VERSION ""

NS_ :

BS_:

BU_: TM

BO_ 1142 VCU_SF: 8 Vector__XXX
 SG_ PEPS_MTO_Failure_Status : 9|2@0+ (1,0) [0|3] ""  TM
 SG_ ABS_ESP_MRC_Failure_Status : 1|2@0+ (1,0) [0|3] ""  TM
 SG_ ABS_ESP_CRC_Failure_Status : 3|2@0+ (1,0) [0|3] ""  TM
 SG_ BattVolt_VCU : 23|8@0+ (0.1,0) [0|25] "Volts"  TM
 SG_ Telematics_MTO_Failure_status : 61|2@0+ (1,0) [0|3] ""  TM
 SG_ Telematics_Invalid_FailureStatus : 63|2@0+ (1,0) [0|3] ""  TM
 SG_ SRS_MTO_Failure_Status : 59|2@0+ (1,0) [0|3] ""  TM
 SG_ IPcMToFailureStatus : 49|2@0+ (1,0) [0|3] ""  TM
 SG_ IPcInvalidFailureStatus : 51|2@0+ (1,0) [0|3] ""  TM
 SG_ ABsMToFailureStatus : 7|2@0+ (1,0) [0|3] ""  TM
 SG_ ABsInvalidFailureStatus : 5|2@0+ (1,0) [0|3] ""  TM
 SG_ VCU_SW_Version : 31|16@0+ (1,0) [0|65535] ""  TM
 SG_ VCU_EP_Failure_Status : 13|2@0+ (1,0) [0|3] ""  TM
 SG_ VCU_BO_Failure_Status : 15|2@0+ (1,0) [0|3] ""  TM
 SG_ GSS_EV_Invalid_Failure_Status : 41|2@0+ (1,0) [0|3] ""  TM
 SG_ GSS_EV_MTO_Failure_Status : 43|2@0+ (1,0) [0|3] ""  TM
 SG_ CCM_MTO_Failure_Status : 45|2@0+ (1,0) [0|3] ""  TM
 SG_ CCM_Invalid_Failure_Status : 47|2@0+ (1,0) [0|3] ""  TM
 SG_ BCmMToFailureStatus : 11|2@0+ (1,0) [0|3] ""  TM

BO_ 1827 Telematics_DiagRequest: 8 Vector__XXX
 SG_ Telematics_DiagRequest : 7|64@0+ (1,0) [0|0] ""  TM

BO_ 1835 Telematics_DiagResponse_USDT: 8 TM
 SG_ Telematics_DiagResponse_USDT : 7|64@0+ (1,0) [0|0] "" Vector__XXX

BO_ 1579 Telematics_DiagResponse_UUDT: 8 TM
 SG_ Telematics_DiagResponse_UUDT : 7|64@0+ (1,0) [0|0] "" Vector__XXX

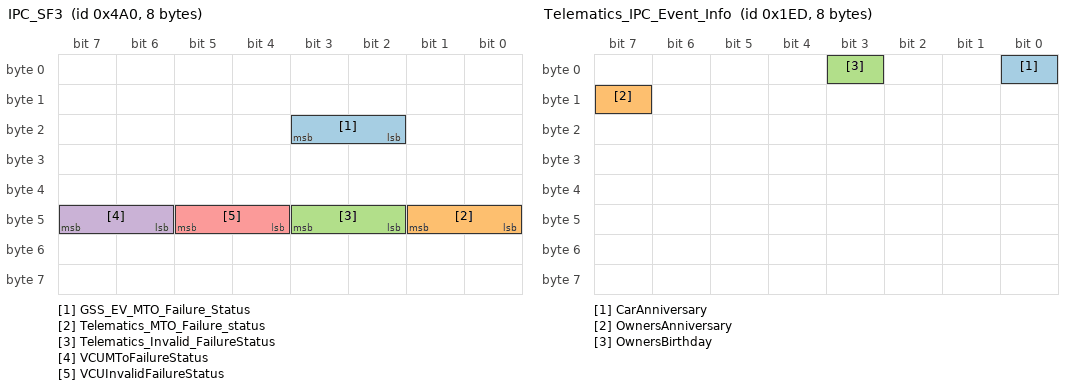
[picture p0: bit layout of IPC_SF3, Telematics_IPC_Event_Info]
BO_ 1184 IPC_SF3: 8 Vector__XXX
 SG_ GSS_EV_MTO_Failure_Status : 19|2@0+ (1,0) [0|3] ""  TM
 SG_ Telematics_MTO_Failure_status : 41|2@0+ (1,0) [0|3] ""  TM
 SG_ Telematics_Invalid_FailureStatus : 43|2@0+ (1,0) [0|3] ""  TM
 SG_ VCUMToFailureStatus : 47|2@0+ (1,0) [0|3] ""  TM
 SG_ VCUInvalidFailureStatus : 45|2@0+ (1,0) [0|3] ""  TM

BO_ 493 Telematics_IPC_Event_Info: 8 TM
 SG_ CarAnniversary : 0|1@0+ (1,0) [0|1] "" Vector__XXX
 SG_ OwnersAnniversary : 15|1@0+ (1,0) [0|1] "" Vector__XXX
 SG_ OwnersBirthday : 3|1@0+ (1,0) [0|1] "" Vector__XXX

BO_ 581 VCU8_RC: 8 Vector__XXX
 SG_ HvChargeTypeStatus : 37|2@0+ (1,0) [0|3] ""  TM
 SG_ HvChargeType : 35|2@0+ (1,0) [0|3] ""  TM
 SG_ HvChargingStateStatus : 33|2@0+ (1,0) [0|3] ""  TM
 SG_ HvChargingState : 26|3@0+ (1,0) [0|7] ""  TM
 SG_ TimetoChargeHVMintsStatus : 17|2@0+ (1,0) [0|3] ""  TM
 SG_ TimetoChargeHVMints : 23|6@0+ (1,0) [0|59] "Minutes"  TM
 SG_ TimetoChargeHVHoursStatus : 10|2@0+ (1,0) [0|3] ""  TM
 SG_ TimetoChargeHVHours : 15|5@0+ (1,0) [0|23] "Hours"  TM
 SG_ CoolingPwrFdbkVal : 63|7@0+ (1,0) [0|100] "%"  TM
 SG_ HeatingPwrFdbkVal : 55|7@0+ (1,0) [0|100] "%"  TM
 SG_ CabinCoolingSolValveStateStatus : 29|2@0+ (1,0) [0|3] ""  TM
 SG_ CabinCoolingSolValveState : 31|2@0+ (1,0) [0|3] ""  TM
 SG_ LowHVBatteryChargeStatus : 7|2@0+ (1,0) [0|3] ""  TM
 SG_ LowHVBatteryCharge : 5|2@0+ (1,0) [0|3] ""  TM
 SG_ LowLVBatteryChargeStatus : 3|2@0+ (1,0) [0|3] ""  TM
 SG_ LowLVBatteryCharge : 1|2@0+ (1,0) [0|3] ""  TM
 SG_ HvAmpHrStatus : 39|2@0+ (1,0) [0|3] ""  TM
 SG_ HvAmpHr : 47|8@0+ (0.5,0) [0|125] ""  TM

BO_ 1171 CCM_SF2: 8 Vector__XXX
 SG_ VCUMToFailureStatus : 33|2@0+ (1,0) [0|3] ""  TM
 SG_ VCUInvalidFailureStatus : 35|2@0+ (1,0) [0|3] ""  TM

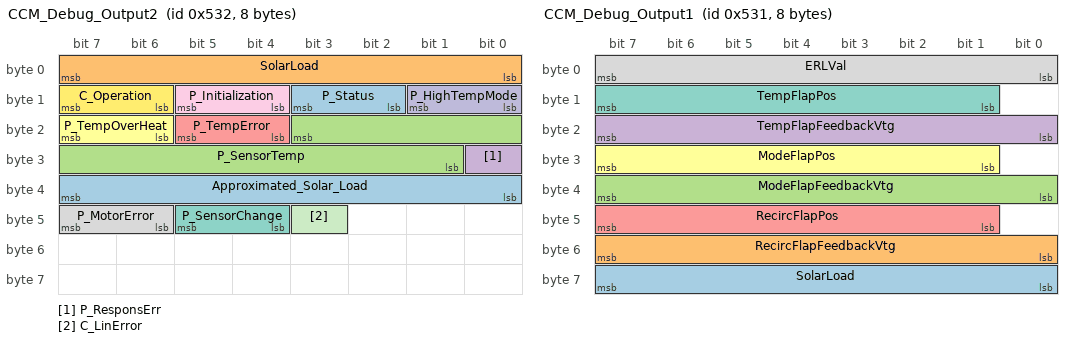
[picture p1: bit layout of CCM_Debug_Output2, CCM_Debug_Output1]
BO_ 1330 CCM_Debug_Output2: 8 Vector__XXX
 SG_ P_Status : 11|2@0+ (1,0) [0|3] ""  TM
 SG_ SolarLoad : 7|8@0+ (5,0) [0|1200] "W/M^2"  TM
 SG_ P_SensorTemp : 19|11@0+ (0.1,-40) [-40|164.7] ""  TM
 SG_ P_ResponsErr : 24|1@0+ (1,0) [0|1] ""  TM
 SG_ P_TempError : 21|2@0+ (1,0) [0|3] ""  TM
 SG_ P_TempOverHeat : 23|2@0+ (1,0) [0|3] ""  TM
 SG_ P_SensorChange : 45|2@0+ (1,0) [0|3] ""  TM
 SG_ P_MotorError : 47|2@0+ (1,0) [0|3] ""  TM
 SG_ P_Initialization : 13|2@0+ (1,0) [0|3] ""  TM
 SG_ P_HighTempMode : 9|2@0+ (1,0) [0|3] ""  TM
 SG_ C_LinError : 43|1@0+ (1,0) [0|1] ""  TM
 SG_ C_Operation : 15|2@0+ (1,0) [0|3] ""  TM
 SG_ Approximated_Solar_Load : 39|8@0+ (5,0) [0|1200] "W/M^2"  TM

BO_ 1329 CCM_Debug_Output1: 8 Vector__XXX
 SG_ SolarLoad : 63|8@0+ (5,0) [0|1200] "W/M^2"  TM
 SG_ RecircFlapFeedbackVtg : 55|8@0+ (0.1,0) [0|25.5] "Volts"  TM
 SG_ ModeFlapFeedbackVtg : 39|8@0+ (0.1,0) [0|25.5] "Volts"  TM
 SG_ TempFlapFeedbackVtg : 23|8@0+ (0.1,0) [0|25.5] "Volts"  TM
 SG_ RecircFlapPos : 47|7@0+ (1,0) [0|100] "%"  TM
 SG_ ModeFlapPos : 31|7@0+ (1,0) [0|100] "%"  TM
 SG_ TempFlapPos : 15|7@0+ (1,0) [0|100] "%"  TM
 SG_ ERLVal : 7|8@0+ (1,0) [0|255] ""  TM

BO_ 1288 TM_NMPDU: 8 TM
 SG_ PartialNetworkInformation_TM : 14|1@0+ (1,0) [0|1] "" Vector__XXX
 SG_ Reserved55 : 23|1@0+ (1,0) [0|1] "" Vector__XXX
 SG_ Reserved54 : 22|1@0+ (1,0) [0|1] "" Vector__XXX
 SG_ Reserved53 : 21|1@0+ (1,0) [0|1] "" Vector__XXX
 SG_ Reserved52 : 20|1@0+ (1,0) [0|1] "" Vector__XXX
 SG_ Reserved51 : 15|1@0+ (1,0) [0|1] "" Vector__XXX
 SG_ Reserved50 : 13|1@0+ (1,0) [0|1] "" Vector__XXX
 SG_ Reserved49 : 10|1@0+ (1,0) [0|1] "" Vector__XXX
 SG_ Reserved48 : 9|1@0+ (1,0) [0|1] "" Vector__XXX
 SG_ RepeatMessageReq_TM : 8|1@0+ (1,0) [0|1] "" Vector__XXX
 SG_ PreviousState_TM : 19|3@0+ (1,0) [0|7] "" Vector__XXX
 SG_ NMCoOrdSlpReady_TM : 11|1@0+ (1,0) [0|1] "" Vector__XXX
 SG_ CurrentState_TM : 16|1@0+ (1,0) [0|1] "" Vector__XXX
 SG_ TM_NMPDU_USER_DATA_D5 : 63|8@0+ (1,0) [0|255] "" Vector__XXX
 SG_ TM_NMPDU_USER_DATA_D4 : 55|8@0+ (1,0) [0|255] "" Vector__XXX
 SG_ TM_NMPDU_USER_DATA_D3 : 47|8@0+ (1,0) [0|255] "" Vector__XXX
 SG_ TM_NMPDU_USER_DATA_D2 : 39|8@0+ (1,0) [0|255] "" Vector__XXX
 SG_ TM_NMPDU_USER_DATA_D1 : 31|8@0+ (1,0) [0|255] "" Vector__XXX
 SG_ TM_NMPDU_SRC_ECU_ID : 7|8@0+ (1,0) [0|255] "" Vector__XXX
 SG_ ActiveWakeUp_TM : 12|1@0+ (1,0) [0|1] "" Vector__XXX

BO_ 1287 VCU_NMPDU: 8 Vector__XXX
 SG_ PartialNetworkInformation_VCU : 14|1@0+ (1,0) [0|1] ""  TM
 SG_ VCU_NMPDU_USER_DATA_D3 : 47|8@0+ (1,0) [0|255] ""  TM
 SG_ Reserved47 : 23|1@0+ (1,0) [0|1] ""  TM
 SG_ Reserved46 : 22|1@0+ (1,0) [0|1] ""  TM
 SG_ Reserved45 : 21|1@0+ (1,0) [0|1] ""  TM
 SG_ Reserved44 : 20|1@0+ (1,0) [0|1] ""  TM
 SG_ Reserved43 : 15|1@0+ (1,0) [0|1] ""  TM
 SG_ Reserved42 : 13|1@0+ (1,0) [0|1] ""  TM
 SG_ Reserved41 : 10|1@0+ (1,0) [0|1] ""  TM
 SG_ Reserved40 : 9|1@0+ (1,0) [0|1] ""  TM
 SG_ RepeatMessageReq_VCU : 8|1@0+ (1,0) [0|1] ""  TM
 SG_ PreviousState_VCU : 19|3@0+ (1,0) [0|7] ""  TM
 SG_ NMCoOrdSlpReady_VCU : 11|1@0+ (1,0) [0|1] ""  TM
 SG_ CurrentState_VCU : 16|1@0+ (1,0) [0|1] ""  TM
 SG_ VCU_NMPDU_USER_DATA_D5 : 63|8@0+ (1,0) [0|255] ""  TM
 SG_ VCU_NMPDU_USER_DATA_D4 : 55|8@0+ (1,0) [0|255] ""  TM
 SG_ VCU_NMPDU_USER_DATA_D2 : 39|8@0+ (1,0) [0|255] ""  TM
 SG_ VCU_NMPDU_USER_DATA_D1 : 31|8@0+ (1,0) [0|255] ""  TM
 SG_ VCU_NMPDU_SRC_ECU_ID : 7|8@0+ (1,0) [0|255] ""  TM
 SG_ ActiveWakeUp_VCU : 12|1@0+ (1,0) [0|1] ""  TM

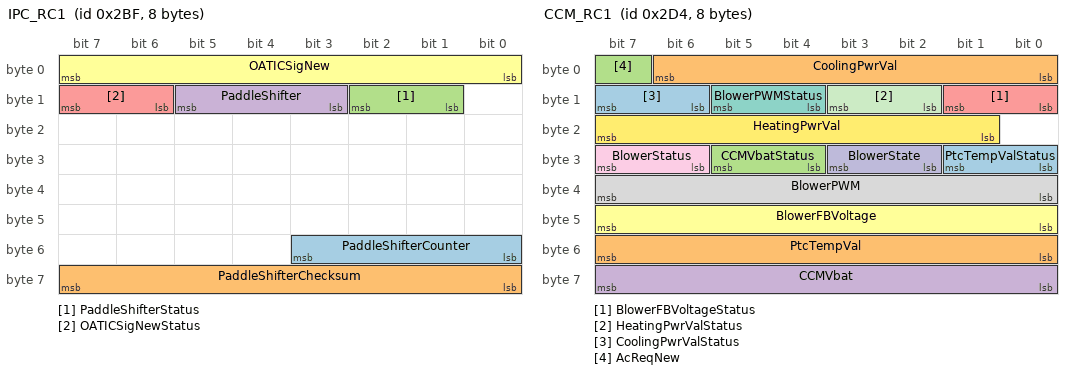
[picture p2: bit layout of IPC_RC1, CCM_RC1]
BO_ 703 IPC_RC1: 8 Vector__XXX
 SG_ PaddleShifterCounter : 51|4@0+ (1,0) [0|15] ""  TM
 SG_ PaddleShifterChecksum : 63|8@0+ (1,0) [0|255] ""  TM
 SG_ PaddleShifterStatus : 10|2@0+ (1,0) [0|3] ""  TM
 SG_ PaddleShifter : 13|3@0+ (1,0) [0|7] ""  TM
 SG_ OATICSigNewStatus : 15|2@0+ (1,0) [0|3] ""  TM
 SG_ OATICSigNew : 7|8@0+ (0.5,-40) [-40|85] "degC"  TM

BO_ 724 CCM_RC1: 8 Vector__XXX
 SG_ PtcTempValStatus : 25|2@0+ (1,0) [0|3] ""  TM
 SG_ PtcTempVal : 55|8@0+ (1,-40) [-40|215] "°C"  TM
 SG_ CCMVbatStatus : 29|2@0+ (1,0) [0|3] ""  TM
 SG_ CCMVbat : 63|8@0+ (0.1,0) [0|25.5] "Volts"  TM
 SG_ BlowerFBVoltageStatus : 9|2@0+ (1,0) [0|3] ""  TM
 SG_ BlowerFBVoltage : 47|8@0+ (0.1,0) [0|25.5] "Volts"  TM
 SG_ BlowerPWMStatus : 13|2@0+ (1,0) [0|3] ""  TM
 SG_ BlowerPWM : 39|8@0+ (1,0) [0|100] "%"  TM
 SG_ BlowerStatus : 31|2@0+ (1,0) [0|3] ""  TM
 SG_ BlowerState : 27|2@0+ (1,0) [0|3] ""  TM
 SG_ HeatingPwrValStatus : 11|2@0+ (1,0) [0|3] ""  TM
 SG_ HeatingPwrVal : 23|7@0+ (1,0) [0|100] "%"  TM
 SG_ CoolingPwrValStatus : 15|2@0+ (1,0) [0|3] ""  TM
 SG_ CoolingPwrVal : 6|7@0+ (1,0) [0|100] "%"  TM
 SG_ AcReqNew : 7|1@0+ (1,0) [0|1] ""  TM

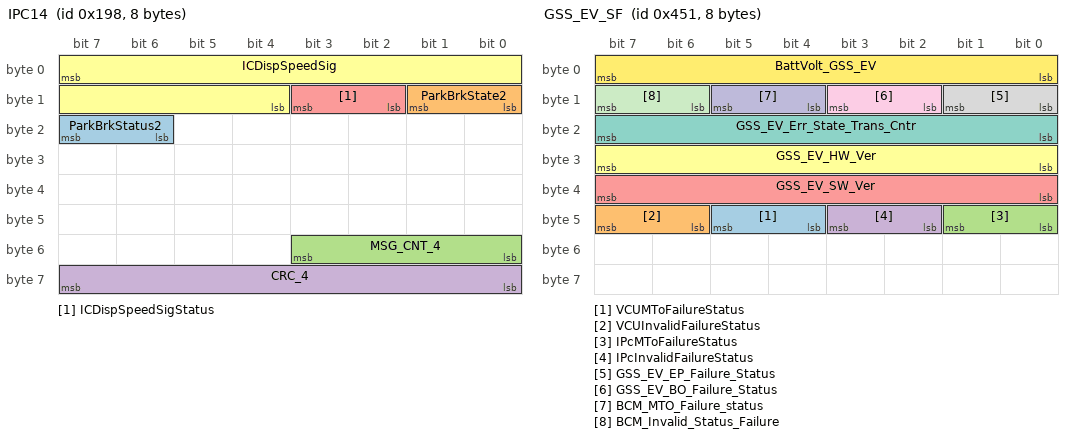
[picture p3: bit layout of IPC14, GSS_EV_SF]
BO_ 408 IPC14: 8 Vector__XXX
 SG_ ParkBrkStatus2 : 23|2@0+ (1,0) [0|3] ""  TM
 SG_ ParkBrkState2 : 9|2@0+ (1,0) [0|3] ""  TM
 SG_ MSG_CNT_4 : 51|4@0+ (1,0) [0|15] ""  TM
 SG_ CRC_4 : 63|8@0+ (1,0) [0|255] ""  TM
 SG_ ICDispSpeedSigStatus : 11|2@0+ (1,0) [0|3] ""  TM
 SG_ ICDispSpeedSig : 7|12@0+ (0.03125,0) [0|127.96875] "m/s"  TM

BO_ 738 BCM_RC5: 8 Vector__XXX
 SG_ BcmHbaFaultState : 49|1@0+ (1,0) [0|1] ""  TM
 SG_ HighBeamState : 23|1@0+ (1,0) [0|1] ""  TM
 SG_ RearWiperStateStatus : 22|2@0+ (1,0) [0|3] ""  TM
 SG_ RearWiperState : 20|2@0+ (1,0) [0|3] ""  TM
 SG_ RemoteUsecaseStateStatus : 51|2@0+ (1,0) [0|3] ""  TM
 SG_ RemoteUsecaseState : 53|2@0+ (1,0) [0|3] ""  TM
 SG_ DewPointTemperature : 47|10@0+ (0.1,-39.5) [-39.5|60.4] ""  TM
 SG_ WindshieldTemperature : 39|8@0+ (0.5,-39.5) [-39.5|87] ""  TM
 SG_ HumidityValue : 31|8@0+ (0.5,0) [0|100] "%"  TM
 SG_ HornStateStatus : 14|2@0+ (1,0) [0|3] ""  TM
 SG_ HornState : 15|1@0+ (1,0) [0|1] ""  TM
 SG_ ForcePanicStatus : 12|1@0+ (1,0) [0|1] ""  TM
 SG_ ApprochLampStateStatus : 18|2@0+ (1,0) [0|3] ""  TM
 SG_ ApprochLampState : 16|1@0+ (1,0) [0|1] ""  TM
 SG_ LowBeamTellTaleStatus : 11|2@0+ (1,0) [0|3] ""  TM
 SG_ LowBeamTellTale : 7|1@0+ (1,0) [0|1] ""  TM
 SG_ IntrusionInfoStateStatus : 9|2@0+ (1,0) [0|3] ""  TM
 SG_ IntrusionInfoState : 6|1@0+ (1,0) [0|1] ""  TM
 SG_ HazardLampState : 3|1@0+ (1,0) [0|1] ""  TM
 SG_ HazardLampStateStatus : 5|2@0+ (1,0) [0|3] ""  TM
 SG_ VehicleSecured : 0|1@0+ (1,0) [0|1] ""  TM
 SG_ VehicleSecuredStatus : 2|2@0+ (1,0) [0|3] ""  TM

BO_ 495 TelematicsEventMsg_RC4: 8 TM
 SG_ SharedLocationReqAck : 14|3@0+ (1,0) [0|7] "" Vector__XXX
 SG_ CommunityHelpResp : 18|3@0+ (1,0) [0|7] "" Vector__XXX
 SG_ CommunityHelpNotif : 55|4@0+ (1,0) [0|15] "" Vector__XXX
 SG_ RemoteHornCmdStatus : 44|2@0+ (1,0) [0|3] "" Vector__XXX
 SG_ RemoteHornCmd : 45|1@0+ (1,0) [0|1] "" Vector__XXX
 SG_ RemoteApprochLmpCmdStatus : 41|2@0+ (1,0) [0|3] "" Vector__XXX
 SG_ RemoteApprochLmpCmd : 42|1@0+ (1,0) [0|1] "" Vector__XXX
 SG_ RemoteValetCmdStatus : 47|2@0+ (1,0) [0|3] "" Vector__XXX
 SG_ RemoteValetCmd : 33|1@0+ (1,0) [0|1] "" Vector__XXX
 SG_ RemoteAcTempSetStatus : 30|2@0+ (1,0) [0|3] "" Vector__XXX
 SG_ RemoteAcTempSet : 28|5@0+ (0.5,0) [0|31] "" Vector__XXX
 SG_ RemoteAcCmd : 31|1@0+ (1,0) [0|1] "" Vector__XXX
 SG_ RemoteAcCmdStatus : 39|2@0+ (1,0) [0|3] "" Vector__XXX
 SG_ RemoteImmoReqStatus : 37|2@0+ (1,0) [0|3] "" Vector__XXX
 SG_ RemoteImmoReq : 35|2@0+ (1,0) [0|3] "" Vector__XXX
 SG_ TowInfoStatus : 20|2@0+ (1,0) [0|3] "" Vector__XXX
 SG_ TowInfo : 21|1@0+ (1,0) [0|1] "" Vector__XXX
 SG_ ParkingCollisionInfoStatus : 23|2@0+ (1,0) [0|3] "" Vector__XXX
 SG_ ParkingCollisionInfo : 8|1@0+ (1,0) [0|1] "" Vector__XXX
 SG_ RemotePositionCmdStatus : 7|2@0+ (1,0) [0|3] "" Vector__XXX
 SG_ RemotePositionCmd : 15|1@0+ (1,0) [0|1] "" Vector__XXX
 SG_ RemoteHazardCmdStatus : 11|2@0+ (1,0) [0|3] "" Vector__XXX
 SG_ RemoteHazardCmd : 9|1@0+ (1,0) [0|1] "" Vector__XXX
 SG_ RemoteVehicleUnlockCmdStatus : 5|2@0+ (1,0) [0|3] "" Vector__XXX
 SG_ RemoteVehicleUnlockCmd : 3|1@0+ (1,0) [0|1] "" Vector__XXX
 SG_ RemoteVehicleLockCmdStatus : 2|2@0+ (1,0) [0|3] "" Vector__XXX
 SG_ RemoteVehicleLockCmd : 0|1@0+ (1,0) [0|1] "" Vector__XXX

BO_ 1105 GSS_EV_SF: 8 Vector__XXX
 SG_ VCUMToFailureStatus : 45|2@0+ (1,0) [0|3] ""  TM
 SG_ VCUInvalidFailureStatus : 47|2@0+ (1,0) [0|3] ""  TM
 SG_ IPcMToFailureStatus : 41|2@0+ (1,0) [0|3] ""  TM
 SG_ IPcInvalidFailureStatus : 43|2@0+ (1,0) [0|3] ""  TM
 SG_ GSS_EV_SW_Ver : 39|8@0+ (1,0) [0|255] ""  TM
 SG_ GSS_EV_HW_Ver : 31|8@0+ (1,0) [0|99] ""  TM
 SG_ GSS_EV_Err_State_Trans_Cntr : 23|8@0+ (1,0) [0|255] ""  TM
 SG_ GSS_EV_EP_Failure_Status : 9|2@0+ (1,0) [0|3] ""  TM
 SG_ GSS_EV_BO_Failure_Status : 11|2@0+ (1,0) [0|3] ""  TM
 SG_ BCM_MTO_Failure_status : 13|2@0+ (1,0) [0|3] ""  TM
 SG_ BCM_Invalid_Status_Failure : 15|2@0+ (1,0) [0|3] ""  TM
 SG_ BattVolt_GSS_EV : 7|8@0+ (0.1,0) [0|25] "V"  TM

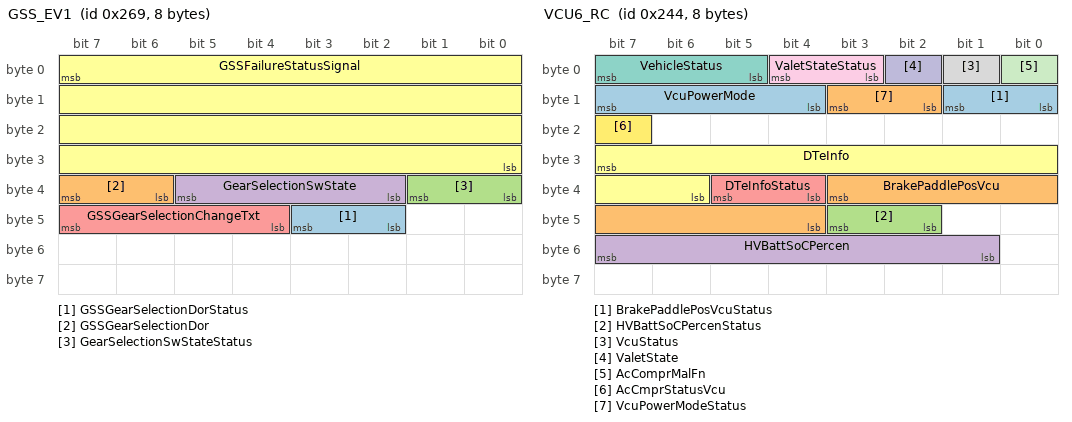
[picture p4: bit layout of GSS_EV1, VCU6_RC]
BO_ 617 GSS_EV1: 8 Vector__XXX
 SG_ GSSGearSelectionDorStatus : 43|2@0+ (1,0) [0|3] ""  TM
 SG_ GSSGearSelectionDor : 39|2@0+ (1,0) [0|3] ""  TM
 SG_ GearSelectionSwStateStatus : 33|2@0+ (1,0) [0|3] ""  TM
 SG_ GearSelectionSwState : 37|4@0+ (1,0) [0|15] ""  TM
 SG_ GSSGearSelectionChangeTxt : 47|4@0+ (1,0) [0|15] ""  TM
 SG_ GSSFailureStatusSignal : 7|32@0+ (1,0) [0|4294967295] ""  TM

BO_ 580 VCU6_RC: 8 Vector__XXX
 SG_ BrakePaddlePosVcuStatus : 9|2@0+ (1,0) [0|3] ""  TM
 SG_ BrakePaddlePosVcu : 35|8@0+ (0.5,0) [0|100] "%"  TM
 SG_ HVBattSoCPercenStatus : 43|2@0+ (1,0) [0|3] ""  TM
 SG_ HVBattSoCPercen : 55|7@0+ (1,0) [0|100] "%"  TM
 SG_ DTeInfoStatus : 37|2@0+ (1,0) [0|3] ""  TM
 SG_ DTeInfo : 31|10@0+ (1,0) [0|999] ""  TM
 SG_ VehicleStatus : 7|3@0+ (1,0) [0|7] ""  TM
 SG_ VcuStatus : 1|1@0+ (1,0) [0|1] ""  TM
 SG_ ValetStateStatus : 4|2@0+ (1,0) [0|3] ""  TM
 SG_ ValetState : 2|1@0+ (1,0) [0|1] ""  TM
 SG_ AcComprMalFn : 0|1@0+ (1,0) [0|1] ""  TM
 SG_ AcCmprStatusVcu : 23|1@0+ (1,0) [0|1] ""  TM
 SG_ VcuPowerMode : 15|4@0+ (1,0) [0|15] ""  TM
 SG_ VcuPowerModeStatus : 11|2@0+ (1,0) [0|3] ""  TM

CM_ BO_ 1142 "Supervision frame transmitted by VCU.";
CM_ SG_ 1142 PEPS_MTO_Failure_Status "Status of the PEPS  Message timeout  failure detected as per Tata-IVN_Specification_Network_Management.";
CM_ SG_ 1142 ABS_ESP_MRC_Failure_Status "Status of the message rolling counter failure detected by IC ECU as per communication layer spec";
CM_ SG_ 1142 ABS_ESP_CRC_Failure_Status "Status of the cyclic reduntancy failure detected by IC ECU as per communication layer spec.";
CM_ SG_ 1142 BattVolt_VCU "Battery voltage evaluated by VCU";
CM_ SG_ 1142 Telematics_MTO_Failure_status "Status of the Telematics Message timeout failure detected as per Tata-IVN_Specification_Network_Management.";
CM_ SG_ 1142 Telematics_Invalid_FailureStatus "Status of the Telematics Invalid failure detected as per Tata-IVN_Specification_Network_Management.";
CM_ SG_ 1142 SRS_MTO_Failure_Status "Status of the SRS  Message timeout  failure detected as per Tata-IVN_Specification_Network_Management.";
CM_ SG_ 1142 IPcMToFailureStatus "Status of the IPC Message Timeout  failure detected as per Tata-IVN_Specification_Network_Management.";
CM_ SG_ 1142 IPcInvalidFailureStatus "Status of the IC Invalid  signal  failure detected as per Tata-IVN_Specification_Network_Management.";
CM_ SG_ 1142 ABsMToFailureStatus "Status of the ESP  Message timeout failure detected as per Tata-IVN_Specification_Network_Management.";
CM_ SG_ 1142 ABsInvalidFailureStatus "Status of the ESP signal implausible  failure detected  by EPAS  as per  communication layer spec";
CM_ SG_ 1142 VCU_SW_Version "software Version of VCU ECU";
CM_ SG_ 1142 VCU_EP_Failure_Status "Status of the error-passive failure detected by VCU ECU as per Tata-IVN_Specification_Network_Management.";
CM_ SG_ 1142 VCU_BO_Failure_Status "Status of the bus off failure detected by VCU  ECU as per Tata-IVN_Specification_Network_Management.";
CM_ SG_ 1142 GSS_EV_Invalid_Failure_Status "Invalid failure status of GSS";
CM_ SG_ 1142 GSS_EV_MTO_Failure_Status "Status of the GSS messege timeout";
CM_ SG_ 1142 CCM_MTO_Failure_Status "Status of the FATC Message timeout failure detected as per Tata-IVN_Specification_Network_Management.";
CM_ SG_ 1142 CCM_Invalid_Failure_Status "Status of the  FATC Invalid  signal  failure detected as per Tata-IVN_Specification_Network_Management.";
CM_ SG_ 1142 BCmMToFailureStatus "Status of the BCM Message timeout  failure detected as per Tata-IVN_Specification_Network_Management.";
CM_ BO_ 1835 "Telematics Diagnostic Response USDT";
CM_ BO_ 1579 "Telematics Diagnostic Response UUDT";
CM_ BO_ 1184 "Supervision frame transmitted by IPC_EV";
CM_ SG_ 1184 GSS_EV_MTO_Failure_Status "Status of the GSS messege timeout";
CM_ SG_ 1184 Telematics_MTO_Failure_status "Status of the Telematics Message timeout failure detected as per Tata-IVN_Specification_Network_Management.";
CM_ SG_ 1184 Telematics_Invalid_FailureStatus "Status of the Telematics Invalid failure detected as per Tata-IVN_Specification_Network_Management.";
CM_ SG_ 1184 VCUMToFailureStatus "VCUMTO failure status";
CM_ SG_ 1184 VCUInvalidFailureStatus "VCU invalid failure status";
CM_ SG_ 493 CarAnniversary "Car Anniversary";
CM_ SG_ 493 OwnersAnniversary "Owenrs Marriage Anniversary";
CM_ SG_ 493 OwnersBirthday "It’s the car Owners Birthday";
CM_ SG_ 581 HvChargeTypeStatus "HV Battery Charging Type Status";
CM_ SG_ 581 HvChargeType "HV Battery Charging Type";
CM_ SG_ 581 HvChargingStateStatus "HV Battery Charging Status";
CM_ SG_ 581 HvChargingState "HV Battery Charging State";
CM_ SG_ 581 TimetoChargeHVMintsStatus "Time to charge HV Battery Minutes Status";
CM_ SG_ 581 TimetoChargeHVMints "Time to charge HV Battery Minutes";
CM_ SG_ 581 TimetoChargeHVHoursStatus "Time to charge HV Battery Hours Status";
CM_ SG_ 581 TimetoChargeHVHours "Time to charge HV Battery Hours";
CM_ SG_ 581 CoolingPwrFdbkVal "This signal is used to indicate the actual value of Cooling Power honored by VCU.";
CM_ SG_ 581 HeatingPwrFdbkVal "This signal is used to indicate the actual value of Heating Power honored by VCU.
";
CM_ SG_ 581 CabinCoolingSolValveStateStatus "Cabin Cooling Solenoid Valve Signal Status";
CM_ SG_ 581 CabinCoolingSolValveState "Cabin Cooling Solenoid Valve Signal";
CM_ SG_ 581 LowHVBatteryChargeStatus "Low HV Battery Charge Status";
CM_ SG_ 581 LowHVBatteryCharge "Low HV Battery Charge";
CM_ SG_ 581 LowLVBatteryChargeStatus "Low LV Battery Charge Status";
CM_ SG_ 581 LowLVBatteryCharge "Low LV Battery Charge";
CM_ SG_ 581 HvAmpHrStatus "HV Battery Charge Status";
CM_ SG_ 581 HvAmpHr "HV Battery Charge";
CM_ BO_ 1171 "Supervision frame transmitted by FATC";
CM_ SG_ 1171 VCUMToFailureStatus "VCUMTO failure status";
CM_ SG_ 1171 VCUInvalidFailureStatus "VCU invalid failure status";
CM_ SG_ 1330 P_Status "Transmit dust Sensor status signal";
CM_ SG_ 1330 SolarLoad "This signal is used to provide the current value of  Solar Load";
CM_ SG_ 1330 P_SensorTemp "Internal Sensor Temperature";
CM_ SG_ 1330 P_ResponsErr "Sensor standard LIN Response error status";
CM_ SG_ 1330 P_TempError "Transmit Sensor Temp error signal";
CM_ SG_ 1330 P_TempOverHeat "Transmit Sensor over-temp signal ";
CM_ SG_ 1330 P_SensorChange "Transmit Sensor Replace signal ";
CM_ SG_ 1330 P_MotorError "Transmit Fan Motor error signal ";
CM_ SG_ 1330 P_Initialization "Transmit initialization signal of Dust Sensor ";
CM_ SG_ 1330 P_HighTempMode "Transmit High temp operating mode signal ";
CM_ SG_ 1330 C_LinError "Sensor Communication error status";
CM_ SG_ 1330 C_Operation "Sensor operation permission signal by FATC.";
CM_ SG_ 1330 Approximated_Solar_Load "This signal is used to provide the current value of  Solar Load";
CM_ SG_ 1329 SolarLoad "This signal is used to provide the current value of  Solar Load";
CM_ SG_ 1329 RecircFlapFeedbackVtg "This signal is used to provide the feedback voltage value of  Air Inlet Flap Potentiometer";
CM_ SG_ 1329 ModeFlapFeedbackVtg "This signal is used to provide the feedback voltage value of  Air Distribution Flap Potentiometer";
CM_ SG_ 1329 TempFlapFeedbackVtg "This signal is used to provide the feedback voltage value of  Temperature Flap Potentiometer";
CM_ SG_ 1329 RecircFlapPos "This signal is used to provide the target value of  Air Inlet Flap";
CM_ SG_ 1329 ModeFlapPos "This signal is used to provide the target value of  Air Distribution Flap";
CM_ SG_ 1329 TempFlapPos "This signal is used to provide the target value of  Temperature Flap";
CM_ SG_ 1329 ERLVal "This signal is used to checked the Energy required for Cabin cooling / heating";
CM_ SG_ 703 PaddleShifterCounter "Rolling counter for the entire GSM Tx messages";
CM_ SG_ 703 PaddleShifterChecksum "CRC for entire GSM Tx messages";
CM_ SG_ 703 PaddleShifterStatus "This signal gives status of Paddle Shifter signal.";
CM_ SG_ 703 PaddleShifter "PaddleShifter signal";
CM_ SG_ 703 OATICSigNewStatus "Signal represents Status of OATSig";
CM_ SG_ 703 OATICSigNew "Signal represents Outside Ambient Temperature raw value evaluated by Instrument Cluster 
";
CM_ SG_ 724 PtcTempValStatus "PTC temperature signal status information";
CM_ SG_ 724 PtcTempVal "This signal is used to provide the current value of PTC temperature sensor";
CM_ SG_ 724 CCMVbatStatus "FATC battery Voltage Status";
CM_ SG_ 724 CCMVbat "Battery voltage measured by FATC";
CM_ SG_ 724 BlowerFBVoltageStatus "Blower feedback Voltage Status";
CM_ SG_ 724 BlowerFBVoltage "Blower Feedback voltage measured by FATC";
CM_ SG_ 724 BlowerPWMStatus "Blower PWM status";
CM_ SG_ 724 BlowerPWM "PWM% Given out by FATC for blower";
CM_ SG_ 724 BlowerStatus "Fault Occured:
It means one of the following faults has occured:
Blower Drive Line Short to Ground.
Blower Drive Line Short to Battery.
Blower Drive Line Open
Blower feedback Line Short to Battery.
Blower feedback Line Short to Ground or Open.";
CM_ SG_ 724 BlowerState "General Blower state
Not initialised:
it means blower is not yet initialised and all signal values of CCMblower message are not valid.
Off : it indicates that blower is Off.
On : it indicates that blower is On.";
CM_ SG_ 724 HeatingPwrValStatus "Indicate the status of heating power required for cabin heating ";
CM_ SG_ 724 HeatingPwrVal "This signal is used to control the PTC Heater for cabin heating";
CM_ SG_ 724 CoolingPwrValStatus "Indicate the status of cooling power required for cabin Cooling ";
CM_ SG_ 724 CoolingPwrVal "This signal is used to control the Compressor rpm for cabin Cooling";
CM_ SG_ 724 AcReqNew "VCU to recive the signal from FATC to know the AC request by driver";
CM_ SG_ 408 ParkBrkStatus2 "Signal represents Park brake status with 2 switch combination for RESS
";
CM_ SG_ 408 ParkBrkState2 "Signal represents Park brake states with 2 switch combination for RESS
";
CM_ SG_ 408 MSG_CNT_4 "rolling counter for message 0x198";
CM_ SG_ 408 CRC_4 "Signal represents CRC of the message.";
CM_ SG_ 408 ICDispSpeedSigStatus "Signal represents Status of Display Vehicle Speed Signal";
CM_ SG_ 408 ICDispSpeedSig "Signal represents Display Vehicle Speed evaluated by Instrument Cluster
";
CM_ SG_ 738 BcmHbaFaultState "It indicates any failure state in BCM for HBA control";
CM_ SG_ 738 HighBeamState "It indicates the status of input of High Beam switch";
CM_ SG_ 738 RearWiperStateStatus "Status of Rear Wiper function Activate/Deactivate to various ECUs";
CM_ SG_ 738 RearWiperState "Rear Wiper function Activate/Deactivate to various ECUs";
CM_ SG_ 738 RemoteUsecaseStateStatus "This signal gives status of RemoteUsecaseState signal.";
CM_ SG_ 738 RemoteUsecaseState "This signal is transmitted from BCM to TCM, PEPS, EMS, IPC & HU for informing ECUs about start working as normal Drive mode and ignore Remote Command recondition checks.";
CM_ SG_ 738 DewPointTemperature "The area of the Dew point Temperature where the RLS sensor is placed. (in Degree Celcius)";
CM_ SG_ 738 WindshieldTemperature "The area of the Windshield Temperature where the RLS sensor is placed. (in Degree Celcius)";
CM_ SG_ 738 HumidityValue "The area of the relative Humidity where the RLS sensor is placed (in terms of percentage)";
CM_ SG_ 738 HornStateStatus "HornStateStatus Signal information";
CM_ SG_ 738 HornState "Horn Status Information ";
CM_ SG_ 738 ForcePanicStatus "Force Panic Request signal";
CM_ SG_ 738 ApprochLampStateStatus "Status signal for ApprochLamp status from BCM";
CM_ SG_ 738 ApprochLampState "ApprochLampstatus from BCM";
CM_ SG_ 738 LowBeamTellTaleStatus "Status of the Low Beam Telltale";
CM_ SG_ 738 LowBeamTellTale "IC to display the low beam tell-tale when the low beam lamp is active";
CM_ SG_ 738 IntrusionInfoStateStatus "Status of Perimetric alarm state from BCM";
CM_ SG_ 738 IntrusionInfoState "Perimetric alarm state from BCM";
CM_ SG_ 738 HazardLampState "Hazard lamp status from BCM";
CM_ SG_ 738 HazardLampStateStatus "Status of signal HazardLampState";
CM_ SG_ 738 VehicleSecured "Vehicle secured information";
CM_ SG_ 738 VehicleSecuredStatus "Status of Vehicle secured information";
CM_ SG_ 495 CommunityHelpResp "TCM feedback to HU for community help command response";
CM_ SG_ 495 CommunityHelpNotif "Signal from Community Help receviers's TCM to receiver's HU to inform  the Community help request to Receiver.";
CM_ SG_ 495 RemoteHornCmdStatus "Status of the HornStateCmd signal published by TCU";
CM_ SG_ 495 RemoteHornCmd "Horn State on/off request from TCU";
CM_ SG_ 495 RemoteApprochLmpCmdStatus "Status of the RemoteApprochCmd signal published by TCU";
CM_ SG_ 495 RemoteApprochLmpCmd "Approch lamp on/off request from TCU";
CM_ SG_ 495 RemoteValetCmdStatus "Status of the Valetcmd Status published by TCU";
CM_ SG_ 495 RemoteValetCmd "Command published by TCU to request FATC";
CM_ SG_ 495 RemoteAcTempSetStatus "Status of the TCuAcTemperatureSet singnal as published by TCU.";
CM_ SG_ 495 RemoteAcTempSet "Set temperature value from TCU to FATC for in-cabin climate control.";
CM_ SG_ 495 RemoteAcCmd "Command published by TCU to request FATC to turn On/Off the AC.";
CM_ SG_ 495 RemoteAcCmdStatus "Status of the TCuAcCmd signal published by TCU";
CM_ SG_ 495 RemoteImmoReqStatus "Status signal for Immobilize request from TCU to VCU";
CM_ SG_ 495 RemoteImmoReq "Immobilize request from TCU to VCU";
CM_ SG_ 495 TowInfoStatus "status signal for TCU sends the Tow away detection to BCM";
CM_ SG_ 495 TowInfo "TCU sends the Tow away detection to BCM ";
CM_ SG_ 495 ParkingCollisionInfoStatus "status signal for TCU sends the Park collision detection to BCM";
CM_ SG_ 495 ParkingCollisionInfo "TCU sends the Park collision detection to BCM ";
CM_ SG_ 495 RemotePositionCmdStatus "Status of the RemotePositionCmd signal published by BCM";
CM_ SG_ 495 RemotePositionCmd "Position lamp on/off request from TCU";
CM_ SG_ 495 RemoteHazardCmdStatus "Status of the RemoteHazardCmd signal published by TCU";
CM_ SG_ 495 RemoteHazardCmd "Hazard lamp on/off request from TCU";
CM_ SG_ 495 RemoteVehicleUnlockCmdStatus "Staus of signal for Command published by TCU to request BCM to unlock the vehicle";
CM_ SG_ 495 RemoteVehicleUnlockCmd "Command published by TCU to request BCM to unlock the vehicle";
CM_ SG_ 495 RemoteVehicleLockCmdStatus "Staus of signal for Command published by TCU to request BCM to lock the vehicle";
CM_ SG_ 495 RemoteVehicleLockCmd "Command published by TCU to request BCM to lock the vehicle";
CM_ BO_ 1105 "Supervision Frame of Gear Selection Switch";
CM_ SG_ 1105 VCUMToFailureStatus "VCUMTO failure status";
CM_ SG_ 1105 VCUInvalidFailureStatus "VCU invalid failure status";
CM_ SG_ 1105 IPcMToFailureStatus "Status of the IPC Message Timeout  failure detected as per Tata-IVN_Specification_Network_Management.";
CM_ SG_ 1105 IPcInvalidFailureStatus "Status of the IC Invalid  signal  failure detected as per Tata-IVN_Specification_Network_Management.";
CM_ SG_ 1105 GSS_EV_SW_Ver "SW version of GSS
";
CM_ SG_ 1105 GSS_EV_HW_Ver "SW version of GSS";
CM_ SG_ 1105 GSS_EV_Err_State_Trans_Cntr "Number of state transitions from bus ON to bus OFF state. Reset this value to Zero in each new Ignition cycle. Freeze this value to 65535 if number of state transitions are more than this value in a given Ignition cycle.
";
CM_ SG_ 1105 GSS_EV_EP_Failure_Status "Status of the error passive detected by GSU as per Tata-IVN_Specification_Network_Management.";
CM_ SG_ 1105 GSS_EV_BO_Failure_Status "Status of the bus-off failure detected byGSU as per Tata-IVN_Specification_Network_Management.

";
CM_ SG_ 1105 BCM_MTO_Failure_status "Message timeout failure flag against BCM ECU";
CM_ SG_ 1105 BCM_Invalid_Status_Failure "Invalid data reception from BCM ECU failure flag";
CM_ SG_ 1105 BattVolt_GSS_EV "Battery voltage evaluated by GSS

";
CM_ BO_ 617 "Gear Selection  Switch";
CM_ SG_ 617 GSSGearSelectionDorStatus "GSS Direction of Rotation Status";
CM_ SG_ 617 GSSGearSelectionDor "GSS Direction of Rotation";
CM_ SG_ 617 GearSelectionSwStateStatus "Information is used to consider the Gear Selection to VCU";
CM_ SG_ 617 GearSelectionSwState "Information is used to consider the Gear Selection to VCU";
CM_ SG_ 617 GSSGearSelectionChangeTxt "GSS Selection Change Request";
CM_ SG_ 617 GSSFailureStatusSignal "Indicates the Failure Modes in GSS";
CM_ SG_ 580 BrakePaddlePosVcuStatus "Brake paddle travel percentage status information shall be Transmissted  by VCU to Telematics ";
CM_ SG_ 580 BrakePaddlePosVcu "Brake paddle travel percentage shall be Transmissted  by VCU to Telematics ";
CM_ SG_ 580 HVBattSoCPercenStatus "HV Battery SoC Percentage Status";
CM_ SG_ 580 HVBattSoCPercen "HV Battery SoC Percentage";
CM_ SG_ 580 DTeInfoStatus "Distance to Empty Information Status";
CM_ SG_ 580 DTeInfo "Distance to Empty Information";
CM_ SG_ 580 VehicleStatus "Vehicle status display messages";
CM_ SG_ 580 VcuStatus "This function displays status of the VCU Malfunctioning
";
CM_ SG_ 580 ValetStateStatus "ValetStateStatus signlal published by VCU";
CM_ SG_ 580 ValetState "ValetState as Published by VCU";
CM_ SG_ 580 AcComprMalFn "This function displays status of the AC Compressor Malfunctioning";
CM_ SG_ 580 AcCmprStatusVcu "This signal is used to cycle the compressor and diagnostic";
CM_ SG_ 580 VcuPowerMode "Indicates the VCU power mode";
CM_ SG_ 580 VcuPowerModeStatus "This information is used to determine the plausibility status for VCU power mode message";
BA_DEF_ SG_  "Remarks" STRING ;
BA_DEF_ SG_  "NWM_WakeupAllowed" ENUM  "No","Yes";
BA_DEF_ SG_  "GenSigTimeoutTime_HU_Mid_X451" INT 0 65535;
BA_DEF_ SG_  "GenSigTimeoutTime_HU_High_X451" INT 0 65535;
BA_DEF_ SG_  "GenSigTimeoutTime_HU_B" INT 0 65535;
BA_DEF_ SG_  "GenSigTimeoutTime_HU_A" INT 0 65535;
BA_DEF_ SG_  "GenSigTimeoutTime_BCM_Mid" INT 0 65535;
BA_DEF_ SG_  "GenSigTimeoutMsg_HU_Mid_X451" INT 0 65535;
BA_DEF_ SG_  "GenSigTimeoutMsg_HU_High_X451" INT 0 65535;
BA_DEF_ SG_  "GenSigTimeoutMsg_HU_B" INT 0 65535;
BA_DEF_ SG_  "GenSigTimeoutMsg_HU_A" INT 0 65535;
BA_DEF_ SG_  "GenSigStartValue" INT 0 0;
BA_DEF_ SG_  "GenSigSendType" ENUM  "Cyclic","OnWrite","OnWriteWithRepetition","OnChange","OnChangeWithRepetition","IfActive","IfActiveWithRepetition","NoSigSendType","NotUsed","NotUsed","NotUsed","NotUsed","NotUsed";
BA_DEF_ SG_  "GenSigInactiveValue" INT 0 0;
BA_DEF_ SG_  "GenSigEnvVarType" ENUM  "int","float","undef";
BA_DEF_ SG_  "GenSigCycleTimeActive" INT 0 0;
BA_DEF_ SG_  "GenSigCycleTime" INT 0 0;
BA_DEF_ SG_  "GenSigTimeoutMsg_HU_High_X445" INT 0 65535;
BA_DEF_ SG_  "GenSigTimeoutMsg_HU_Mid_X445" INT 0 65535;
BA_DEF_ SG_  "GenSigTimeoutTime_HU_High_X445" INT 0 65535;
BA_DEF_ SG_  "GenSigTimeoutTime_HU_Mid_X445" INT 0 65535;
BA_DEF_ SG_  "GenSigTimeoutMsg_IVI" INT 0 65535;
BA_DEF_ SG_  "GenSigTimeoutTime_IVI" INT 0 65535;
BA_DEF_ BO_  "NmMessage" ENUM  "no","yes";
BA_DEF_ BO_  "NmAsrMessage" ENUM  "<n.a.>","No","Yes";
BA_DEF_ BO_  "MessageTimeout" INT 0 65535;
BA_DEF_ BO_  "Me" INT 0 0;
BA_DEF_ BO_  "GenMsgStartDelayTime" INT 0 0;
BA_DEF_ BO_  "GenMsgSendType" ENUM  "Cyclic","NotUsed","NotUsed","NotUsed","NotUsed","NotUsed","NotUsed","IfActive","NoMsgSendType","NotUsed";
BA_DEF_ BO_  "GenMsgNrOfRepetition" INT 0 0;
BA_DEF_ BO_  "GenMsgILSupport" ENUM  "No","Yes";
BA_DEF_ BO_  "GenMsgDelayTime" INT 0 0;
BA_DEF_ BO_  "GenMsgCycleTimeFast" INT 0 0;
BA_DEF_ BO_  "GenMsgCycleTime" INT 0 0;
BA_DEF_ BO_  "DiagUudtResponse" ENUM  "false","true";
BA_DEF_ BO_  "DiagUsdtResponse" ENUM  "false","true";
BA_DEF_ BO_  "DiagState" ENUM  "No","Yes";
BA_DEF_ BO_  "DiagResponse" ENUM  "No","Yes";
BA_DEF_ BO_  "DiagRequest" ENUM  "No","Yes";
BA_DEF_ BO_  "MsgType" ENUM  "Application","NM","NMH";
BA_DEF_ SG_  "SystemSignalLongSymbol" STRING ;
BA_DEF_DEF_  "Remarks" "null";
BA_DEF_DEF_  "NWM_WakeupAllowed" "No";
BA_DEF_DEF_  "GenSigTimeoutTime_HU_Mid_X451" 500;
BA_DEF_DEF_  "GenSigTimeoutTime_HU_High_X451" 500;
BA_DEF_DEF_  "GenSigTimeoutTime_HU_B" 500;
BA_DEF_DEF_  "GenSigTimeoutTime_HU_A" 500;
BA_DEF_DEF_  "GenSigTimeoutTime_BCM_Mid" 0;
BA_DEF_DEF_  "GenSigTimeoutMsg_HU_Mid_X451" 500;
BA_DEF_DEF_  "GenSigTimeoutMsg_HU_High_X451" 500;
BA_DEF_DEF_  "GenSigTimeoutMsg_HU_B" 500;
BA_DEF_DEF_  "GenSigTimeoutMsg_HU_A" 500;
BA_DEF_DEF_  "GenSigStartValue" 0;
BA_DEF_DEF_  "GenSigSendType" "Cyclic";
BA_DEF_DEF_  "GenSigInactiveValue" 0;
BA_DEF_DEF_  "GenSigEnvVarType" "undef";
BA_DEF_DEF_  "GenSigCycleTimeActive" 0;
BA_DEF_DEF_  "GenSigCycleTime" 0;
BA_DEF_DEF_  "GenSigTimeoutMsg_HU_High_X445" 500;
BA_DEF_DEF_  "GenSigTimeoutMsg_HU_Mid_X445" 500;
BA_DEF_DEF_  "GenSigTimeoutTime_HU_High_X445" 500;
BA_DEF_DEF_  "GenSigTimeoutTime_HU_Mid_X445" 500;
BA_DEF_DEF_  "GenSigTimeoutMsg_IVI" 500;
BA_DEF_DEF_  "GenSigTimeoutTime_IVI" 500;
BA_DEF_DEF_  "NmMessage" "no";
BA_DEF_DEF_  "NmAsrMessage" "<n.a.>";
BA_DEF_DEF_  "MessageTimeout" 500;
BA_DEF_DEF_  "Me" 0;
BA_DEF_DEF_  "GenMsgStartDelayTime" 0;
BA_DEF_DEF_  "GenMsgSendType" "Cyclic";
BA_DEF_DEF_  "GenMsgNrOfRepetition" 0;
BA_DEF_DEF_  "GenMsgILSupport" "Yes";
BA_DEF_DEF_  "GenMsgDelayTime" 0;
BA_DEF_DEF_  "GenMsgCycleTimeFast" 0;
BA_DEF_DEF_  "GenMsgCycleTime" 0;
BA_DEF_DEF_  "DiagUudtResponse" "false";
BA_DEF_DEF_  "DiagUsdtResponse" "false";
BA_DEF_DEF_  "DiagState" "No";
BA_DEF_DEF_  "DiagResponse" "No";
BA_DEF_DEF_  "DiagRequest" "No";
BA_DEF_DEF_  "MsgType" "Application";
BA_DEF_DEF_  "SystemSignalLongSymbol" "";
BA_ "MessageTimeout" BO_ 1142 0;
BA_ "GenMsgCycleTime" BO_ 1142 100;
BA_ "MessageTimeout" BO_ 1827 0;
BA_ "GenMsgSendType" BO_ 1827 8;
BA_ "GenMsgILSupport" BO_ 1827 0;
BA_ "DiagRequest" BO_ 1827 1;
BA_ "MessageTimeout" BO_ 1835 0;
BA_ "GenMsgSendType" BO_ 1835 8;
BA_ "GenMsgILSupport" BO_ 1835 0;
BA_ "DiagResponse" BO_ 1835 1;
BA_ "MessageTimeout" BO_ 1579 0;
BA_ "GenMsgSendType" BO_ 1579 8;
BA_ "GenMsgILSupport" BO_ 1579 0;
BA_ "DiagResponse" BO_ 1579 1;
BA_ "MessageTimeout" BO_ 1184 0;
BA_ "GenMsgStartDelayTime" BO_ 1184 35;
BA_ "GenMsgCycleTime" BO_ 1184 100;
BA_ "MessageTimeout" BO_ 493 0;
BA_ "GenMsgSendType" BO_ 493 8;
BA_ "GenMsgNrOfRepetition" BO_ 493 3;
BA_ "GenMsgDelayTime" BO_ 493 100;
BA_ "GenMsgCycleTime" BO_ 581 100;
BA_ "MessageTimeout" BO_ 1171 0;
BA_ "GenMsgCycleTime" BO_ 1171 100;
BA_ "GenMsgCycleTime" BO_ 1330 100;
BA_ "GenMsgCycleTime" BO_ 1329 100;
BA_ "MessageTimeout" BO_ 1288 1000;
BA_ "GenMsgCycleTime" BO_ 1288 200;
BA_ "MessageTimeout" BO_ 1287 1000;
BA_ "GenMsgCycleTime" BO_ 1287 200;
BA_ "GenMsgCycleTime" BO_ 703 100;
BA_ "GenMsgCycleTime" BO_ 724 100;
BA_ "GenMsgCycleTime" BO_ 408 20;
BA_ "GenMsgCycleTime" BO_ 738 100;
BA_ "MessageTimeout" BO_ 495 0;
BA_ "GenMsgSendType" BO_ 495 8;
BA_ "GenMsgNrOfRepetition" BO_ 495 10;
BA_ "GenMsgDelayTime" BO_ 495 200;
BA_ "GenMsgCycleTimeFast" BO_ 495 200;
BA_ "GenMsgCycleTime" BO_ 1105 100;
BA_ "GenMsgCycleTimeFast" BO_ 617 100;
BA_ "GenMsgCycleTime" BO_ 617 100;
BA_ "GenMsgCycleTime" BO_ 580 100;
BA_ "GenSigTimeoutTime_HU_B" SG_ 1142 PEPS_MTO_Failure_Status 0;
BA_ "GenSigTimeoutTime_HU_A" SG_ 1142 PEPS_MTO_Failure_Status 0;
BA_ "GenSigTimeoutMsg_HU_B" SG_ 1142 PEPS_MTO_Failure_Status 0;
BA_ "GenSigTimeoutMsg_HU_A" SG_ 1142 PEPS_MTO_Failure_Status 0;
BA_ "GenSigSendType" SG_ 1142 PEPS_MTO_Failure_Status 7;
BA_ "GenSigCycleTimeActive" SG_ 1142 PEPS_MTO_Failure_Status 100;
BA_ "GenSigCycleTime" SG_ 1142 PEPS_MTO_Failure_Status 100;
BA_ "GenSigTimeoutTime_HU_B" SG_ 1142 ABS_ESP_MRC_Failure_Status 0;
BA_ "GenSigTimeoutTime_HU_A" SG_ 1142 ABS_ESP_MRC_Failure_Status 0;
BA_ "GenSigTimeoutMsg_HU_B" SG_ 1142 ABS_ESP_MRC_Failure_Status 0;
BA_ "GenSigTimeoutMsg_HU_A" SG_ 1142 ABS_ESP_MRC_Failure_Status 0;
BA_ "GenSigSendType" SG_ 1142 ABS_ESP_MRC_Failure_Status 7;
BA_ "GenSigCycleTimeActive" SG_ 1142 ABS_ESP_MRC_Failure_Status 100;
BA_ "GenSigCycleTime" SG_ 1142 ABS_ESP_MRC_Failure_Status 100;
BA_ "GenSigTimeoutTime_HU_B" SG_ 1142 ABS_ESP_CRC_Failure_Status 0;
BA_ "GenSigTimeoutTime_HU_A" SG_ 1142 ABS_ESP_CRC_Failure_Status 0;
BA_ "GenSigTimeoutMsg_HU_B" SG_ 1142 ABS_ESP_CRC_Failure_Status 0;
BA_ "GenSigTimeoutMsg_HU_A" SG_ 1142 ABS_ESP_CRC_Failure_Status 0;
BA_ "GenSigSendType" SG_ 1142 ABS_ESP_CRC_Failure_Status 7;
BA_ "GenSigCycleTimeActive" SG_ 1142 ABS_ESP_CRC_Failure_Status 100;
BA_ "GenSigCycleTime" SG_ 1142 ABS_ESP_CRC_Failure_Status 100;
BA_ "GenSigTimeoutTime_HU_Mid_X451" SG_ 1142 BattVolt_VCU 0;
BA_ "GenSigTimeoutTime_HU_High_X451" SG_ 1142 BattVolt_VCU 0;
BA_ "GenSigTimeoutTime_HU_B" SG_ 1142 BattVolt_VCU 0;
BA_ "GenSigTimeoutTime_HU_A" SG_ 1142 BattVolt_VCU 0;
BA_ "GenSigTimeoutMsg_HU_Mid_X451" SG_ 1142 BattVolt_VCU 0;
BA_ "GenSigTimeoutMsg_HU_High_X451" SG_ 1142 BattVolt_VCU 0;
BA_ "GenSigTimeoutMsg_HU_B" SG_ 1142 BattVolt_VCU 0;
BA_ "GenSigTimeoutMsg_HU_A" SG_ 1142 BattVolt_VCU 0;
BA_ "GenSigSendType" SG_ 1142 BattVolt_VCU 7;
BA_ "GenSigCycleTimeActive" SG_ 1142 BattVolt_VCU 100;
BA_ "GenSigCycleTime" SG_ 1142 BattVolt_VCU 100;
BA_ "GenSigTimeoutTime_HU_Mid_X451" SG_ 1142 Telematics_MTO_Failure_status 0;
BA_ "GenSigTimeoutTime_HU_High_X451" SG_ 1142 Telematics_MTO_Failure_status 0;
BA_ "GenSigTimeoutTime_HU_B" SG_ 1142 Telematics_MTO_Failure_status 0;
BA_ "GenSigTimeoutTime_HU_A" SG_ 1142 Telematics_MTO_Failure_status 0;
BA_ "GenSigTimeoutMsg_HU_Mid_X451" SG_ 1142 Telematics_MTO_Failure_status 0;
BA_ "GenSigTimeoutMsg_HU_High_X451" SG_ 1142 Telematics_MTO_Failure_status 0;
BA_ "GenSigTimeoutMsg_HU_B" SG_ 1142 Telematics_MTO_Failure_status 0;
BA_ "GenSigTimeoutMsg_HU_A" SG_ 1142 Telematics_MTO_Failure_status 0;
BA_ "GenSigSendType" SG_ 1142 Telematics_MTO_Failure_status 7;
BA_ "GenSigCycleTimeActive" SG_ 1142 Telematics_MTO_Failure_status 100;
BA_ "GenSigCycleTime" SG_ 1142 Telematics_MTO_Failure_status 100;
BA_ "GenSigTimeoutTime_HU_Mid_X451" SG_ 1142 Telematics_Invalid_FailureStatus 0;
BA_ "GenSigTimeoutTime_HU_High_X451" SG_ 1142 Telematics_Invalid_FailureStatus 0;
BA_ "GenSigTimeoutTime_HU_B" SG_ 1142 Telematics_Invalid_FailureStatus 0;
BA_ "GenSigTimeoutTime_HU_A" SG_ 1142 Telematics_Invalid_FailureStatus 0;
BA_ "GenSigTimeoutMsg_HU_Mid_X451" SG_ 1142 Telematics_Invalid_FailureStatus 0;
BA_ "GenSigTimeoutMsg_HU_High_X451" SG_ 1142 Telematics_Invalid_FailureStatus 0;
BA_ "GenSigTimeoutMsg_HU_B" SG_ 1142 Telematics_Invalid_FailureStatus 0;
BA_ "GenSigTimeoutMsg_HU_A" SG_ 1142 Telematics_Invalid_FailureStatus 0;
BA_ "GenSigSendType" SG_ 1142 Telematics_Invalid_FailureStatus 7;
BA_ "GenSigCycleTimeActive" SG_ 1142 Telematics_Invalid_FailureStatus 100;
BA_ "GenSigCycleTime" SG_ 1142 Telematics_Invalid_FailureStatus 100;
BA_ "GenSigTimeoutTime_HU_Mid_X451" SG_ 1142 SRS_MTO_Failure_Status 0;
BA_ "GenSigTimeoutTime_HU_High_X451" SG_ 1142 SRS_MTO_Failure_Status 0;
BA_ "GenSigTimeoutTime_HU_B" SG_ 1142 SRS_MTO_Failure_Status 0;
BA_ "GenSigTimeoutTime_HU_A" SG_ 1142 SRS_MTO_Failure_Status 0;
BA_ "GenSigTimeoutMsg_HU_Mid_X451" SG_ 1142 SRS_MTO_Failure_Status 0;
BA_ "GenSigTimeoutMsg_HU_High_X451" SG_ 1142 SRS_MTO_Failure_Status 0;
BA_ "GenSigTimeoutMsg_HU_B" SG_ 1142 SRS_MTO_Failure_Status 0;
BA_ "GenSigTimeoutMsg_HU_A" SG_ 1142 SRS_MTO_Failure_Status 0;
BA_ "GenSigSendType" SG_ 1142 SRS_MTO_Failure_Status 7;
BA_ "GenSigCycleTimeActive" SG_ 1142 SRS_MTO_Failure_Status 100;
BA_ "GenSigCycleTime" SG_ 1142 SRS_MTO_Failure_Status 100;
BA_ "GenSigTimeoutTime_HU_Mid_X451" SG_ 1142 IPcMToFailureStatus 0;
BA_ "GenSigTimeoutTime_HU_High_X451" SG_ 1142 IPcMToFailureStatus 0;
BA_ "GenSigTimeoutTime_HU_B" SG_ 1142 IPcMToFailureStatus 0;
BA_ "GenSigTimeoutTime_HU_A" SG_ 1142 IPcMToFailureStatus 0;
BA_ "GenSigTimeoutMsg_HU_Mid_X451" SG_ 1142 IPcMToFailureStatus 0;
BA_ "GenSigTimeoutMsg_HU_High_X451" SG_ 1142 IPcMToFailureStatus 0;
BA_ "GenSigTimeoutMsg_HU_B" SG_ 1142 IPcMToFailureStatus 0;
BA_ "GenSigTimeoutMsg_HU_A" SG_ 1142 IPcMToFailureStatus 0;
BA_ "GenSigSendType" SG_ 1142 IPcMToFailureStatus 7;
BA_ "GenSigCycleTimeActive" SG_ 1142 IPcMToFailureStatus 100;
BA_ "GenSigCycleTime" SG_ 1142 IPcMToFailureStatus 100;
BA_ "GenSigTimeoutTime_HU_Mid_X451" SG_ 1142 IPcInvalidFailureStatus 0;
BA_ "GenSigTimeoutTime_HU_High_X451" SG_ 1142 IPcInvalidFailureStatus 0;
BA_ "GenSigTimeoutTime_HU_B" SG_ 1142 IPcInvalidFailureStatus 0;
BA_ "GenSigTimeoutTime_HU_A" SG_ 1142 IPcInvalidFailureStatus 0;
BA_ "GenSigTimeoutMsg_HU_Mid_X451" SG_ 1142 IPcInvalidFailureStatus 0;
BA_ "GenSigTimeoutMsg_HU_High_X451" SG_ 1142 IPcInvalidFailureStatus 0;
BA_ "GenSigTimeoutMsg_HU_B" SG_ 1142 IPcInvalidFailureStatus 0;
BA_ "GenSigTimeoutMsg_HU_A" SG_ 1142 IPcInvalidFailureStatus 0;
BA_ "GenSigSendType" SG_ 1142 IPcInvalidFailureStatus 7;
BA_ "GenSigCycleTimeActive" SG_ 1142 IPcInvalidFailureStatus 100;
BA_ "GenSigCycleTime" SG_ 1142 IPcInvalidFailureStatus 100;
BA_ "GenSigTimeoutTime_HU_Mid_X451" SG_ 1142 ABsMToFailureStatus 0;
BA_ "GenSigTimeoutTime_HU_High_X451" SG_ 1142 ABsMToFailureStatus 0;
BA_ "GenSigTimeoutTime_HU_B" SG_ 1142 ABsMToFailureStatus 0;
BA_ "GenSigTimeoutTime_HU_A" SG_ 1142 ABsMToFailureStatus 0;
BA_ "GenSigTimeoutMsg_HU_Mid_X451" SG_ 1142 ABsMToFailureStatus 0;
BA_ "GenSigTimeoutMsg_HU_High_X451" SG_ 1142 ABsMToFailureStatus 0;
BA_ "GenSigTimeoutMsg_HU_B" SG_ 1142 ABsMToFailureStatus 0;
BA_ "GenSigTimeoutMsg_HU_A" SG_ 1142 ABsMToFailureStatus 0;
BA_ "GenSigSendType" SG_ 1142 ABsMToFailureStatus 7;
BA_ "GenSigCycleTimeActive" SG_ 1142 ABsMToFailureStatus 100;
BA_ "GenSigCycleTime" SG_ 1142 ABsMToFailureStatus 100;
BA_ "GenSigTimeoutTime_HU_Mid_X451" SG_ 1142 ABsInvalidFailureStatus 0;
BA_ "GenSigTimeoutTime_HU_High_X451" SG_ 1142 ABsInvalidFailureStatus 0;
BA_ "GenSigTimeoutTime_HU_B" SG_ 1142 ABsInvalidFailureStatus 0;
BA_ "GenSigTimeoutTime_HU_A" SG_ 1142 ABsInvalidFailureStatus 0;
BA_ "GenSigTimeoutMsg_HU_Mid_X451" SG_ 1142 ABsInvalidFailureStatus 0;
BA_ "GenSigTimeoutMsg_HU_High_X451" SG_ 1142 ABsInvalidFailureStatus 0;
BA_ "GenSigTimeoutMsg_HU_B" SG_ 1142 ABsInvalidFailureStatus 0;
BA_ "GenSigTimeoutMsg_HU_A" SG_ 1142 ABsInvalidFailureStatus 0;
BA_ "GenSigSendType" SG_ 1142 ABsInvalidFailureStatus 7;
BA_ "GenSigCycleTimeActive" SG_ 1142 ABsInvalidFailureStatus 100;
BA_ "GenSigCycleTime" SG_ 1142 ABsInvalidFailureStatus 100;
BA_ "GenSigTimeoutTime_HU_Mid_X451" SG_ 1142 VCU_SW_Version 0;
BA_ "GenSigTimeoutTime_HU_High_X451" SG_ 1142 VCU_SW_Version 0;
BA_ "GenSigTimeoutTime_HU_B" SG_ 1142 VCU_SW_Version 0;
BA_ "GenSigTimeoutTime_HU_A" SG_ 1142 VCU_SW_Version 0;
BA_ "GenSigTimeoutMsg_HU_Mid_X451" SG_ 1142 VCU_SW_Version 0;
BA_ "GenSigTimeoutMsg_HU_High_X451" SG_ 1142 VCU_SW_Version 0;
BA_ "GenSigTimeoutMsg_HU_B" SG_ 1142 VCU_SW_Version 0;
BA_ "GenSigTimeoutMsg_HU_A" SG_ 1142 VCU_SW_Version 0;
BA_ "GenSigSendType" SG_ 1142 VCU_SW_Version 7;
BA_ "GenSigCycleTimeActive" SG_ 1142 VCU_SW_Version 100;
BA_ "GenSigCycleTime" SG_ 1142 VCU_SW_Version 100;
BA_ "GenSigTimeoutTime_HU_Mid_X451" SG_ 1142 VCU_EP_Failure_Status 0;
BA_ "GenSigTimeoutTime_HU_High_X451" SG_ 1142 VCU_EP_Failure_Status 0;
BA_ "GenSigTimeoutTime_HU_B" SG_ 1142 VCU_EP_Failure_Status 0;
BA_ "GenSigTimeoutTime_HU_A" SG_ 1142 VCU_EP_Failure_Status 0;
BA_ "GenSigTimeoutMsg_HU_Mid_X451" SG_ 1142 VCU_EP_Failure_Status 0;
BA_ "GenSigTimeoutMsg_HU_High_X451" SG_ 1142 VCU_EP_Failure_Status 0;
BA_ "GenSigTimeoutMsg_HU_B" SG_ 1142 VCU_EP_Failure_Status 0;
BA_ "GenSigTimeoutMsg_HU_A" SG_ 1142 VCU_EP_Failure_Status 0;
BA_ "GenSigSendType" SG_ 1142 VCU_EP_Failure_Status 7;
BA_ "GenSigCycleTimeActive" SG_ 1142 VCU_EP_Failure_Status 100;
BA_ "GenSigCycleTime" SG_ 1142 VCU_EP_Failure_Status 100;
BA_ "GenSigTimeoutTime_HU_Mid_X451" SG_ 1142 VCU_BO_Failure_Status 0;
BA_ "GenSigTimeoutTime_HU_High_X451" SG_ 1142 VCU_BO_Failure_Status 0;
BA_ "GenSigTimeoutTime_HU_B" SG_ 1142 VCU_BO_Failure_Status 0;
BA_ "GenSigTimeoutTime_HU_A" SG_ 1142 VCU_BO_Failure_Status 0;
BA_ "GenSigTimeoutMsg_HU_Mid_X451" SG_ 1142 VCU_BO_Failure_Status 0;
BA_ "GenSigTimeoutMsg_HU_High_X451" SG_ 1142 VCU_BO_Failure_Status 0;
BA_ "GenSigTimeoutMsg_HU_B" SG_ 1142 VCU_BO_Failure_Status 0;
BA_ "GenSigTimeoutMsg_HU_A" SG_ 1142 VCU_BO_Failure_Status 0;
BA_ "GenSigSendType" SG_ 1142 VCU_BO_Failure_Status 7;
BA_ "GenSigCycleTimeActive" SG_ 1142 VCU_BO_Failure_Status 100;
BA_ "GenSigCycleTime" SG_ 1142 VCU_BO_Failure_Status 100;
BA_ "GenSigTimeoutTime_HU_Mid_X451" SG_ 1142 GSS_EV_Invalid_Failure_Status 0;
BA_ "GenSigTimeoutTime_HU_High_X451" SG_ 1142 GSS_EV_Invalid_Failure_Status 0;
BA_ "GenSigTimeoutTime_HU_B" SG_ 1142 GSS_EV_Invalid_Failure_Status 0;
BA_ "GenSigTimeoutTime_HU_A" SG_ 1142 GSS_EV_Invalid_Failure_Status 0;
BA_ "GenSigTimeoutMsg_HU_Mid_X451" SG_ 1142 GSS_EV_Invalid_Failure_Status 0;
BA_ "GenSigTimeoutMsg_HU_High_X451" SG_ 1142 GSS_EV_Invalid_Failure_Status 0;
BA_ "GenSigTimeoutMsg_HU_B" SG_ 1142 GSS_EV_Invalid_Failure_Status 0;
BA_ "GenSigTimeoutMsg_HU_A" SG_ 1142 GSS_EV_Invalid_Failure_Status 0;
BA_ "GenSigSendType" SG_ 1142 GSS_EV_Invalid_Failure_Status 7;
BA_ "GenSigCycleTimeActive" SG_ 1142 GSS_EV_Invalid_Failure_Status 100;
BA_ "GenSigCycleTime" SG_ 1142 GSS_EV_Invalid_Failure_Status 100;
BA_ "GenSigTimeoutTime_HU_Mid_X451" SG_ 1142 GSS_EV_MTO_Failure_Status 0;
BA_ "GenSigTimeoutTime_HU_High_X451" SG_ 1142 GSS_EV_MTO_Failure_Status 0;
BA_ "GenSigTimeoutTime_HU_B" SG_ 1142 GSS_EV_MTO_Failure_Status 0;
BA_ "GenSigTimeoutTime_HU_A" SG_ 1142 GSS_EV_MTO_Failure_Status 0;
BA_ "GenSigTimeoutMsg_HU_Mid_X451" SG_ 1142 GSS_EV_MTO_Failure_Status 0;
BA_ "GenSigTimeoutMsg_HU_High_X451" SG_ 1142 GSS_EV_MTO_Failure_Status 0;
BA_ "GenSigTimeoutMsg_HU_B" SG_ 1142 GSS_EV_MTO_Failure_Status 0;
BA_ "GenSigTimeoutMsg_HU_A" SG_ 1142 GSS_EV_MTO_Failure_Status 0;
BA_ "GenSigSendType" SG_ 1142 GSS_EV_MTO_Failure_Status 7;
BA_ "GenSigCycleTimeActive" SG_ 1142 GSS_EV_MTO_Failure_Status 100;
BA_ "GenSigCycleTime" SG_ 1142 GSS_EV_MTO_Failure_Status 100;
BA_ "GenSigTimeoutTime_HU_Mid_X451" SG_ 1142 CCM_MTO_Failure_Status 0;
BA_ "GenSigTimeoutTime_HU_High_X451" SG_ 1142 CCM_MTO_Failure_Status 0;
BA_ "GenSigTimeoutTime_HU_B" SG_ 1142 CCM_MTO_Failure_Status 0;
BA_ "GenSigTimeoutTime_HU_A" SG_ 1142 CCM_MTO_Failure_Status 0;
BA_ "GenSigTimeoutMsg_HU_Mid_X451" SG_ 1142 CCM_MTO_Failure_Status 0;
BA_ "GenSigTimeoutMsg_HU_High_X451" SG_ 1142 CCM_MTO_Failure_Status 0;
BA_ "GenSigTimeoutMsg_HU_B" SG_ 1142 CCM_MTO_Failure_Status 0;
BA_ "GenSigTimeoutMsg_HU_A" SG_ 1142 CCM_MTO_Failure_Status 0;
BA_ "GenSigSendType" SG_ 1142 CCM_MTO_Failure_Status 7;
BA_ "GenSigCycleTimeActive" SG_ 1142 CCM_MTO_Failure_Status 100;
BA_ "GenSigCycleTime" SG_ 1142 CCM_MTO_Failure_Status 100;
BA_ "GenSigTimeoutTime_HU_Mid_X451" SG_ 1142 CCM_Invalid_Failure_Status 0;
BA_ "GenSigTimeoutTime_HU_High_X451" SG_ 1142 CCM_Invalid_Failure_Status 0;
BA_ "GenSigTimeoutTime_HU_B" SG_ 1142 CCM_Invalid_Failure_Status 0;
BA_ "GenSigTimeoutTime_HU_A" SG_ 1142 CCM_Invalid_Failure_Status 0;
BA_ "GenSigTimeoutMsg_HU_Mid_X451" SG_ 1142 CCM_Invalid_Failure_Status 0;
BA_ "GenSigTimeoutMsg_HU_High_X451" SG_ 1142 CCM_Invalid_Failure_Status 0;
BA_ "GenSigTimeoutMsg_HU_B" SG_ 1142 CCM_Invalid_Failure_Status 0;
BA_ "GenSigTimeoutMsg_HU_A" SG_ 1142 CCM_Invalid_Failure_Status 0;
BA_ "GenSigSendType" SG_ 1142 CCM_Invalid_Failure_Status 7;
BA_ "GenSigCycleTimeActive" SG_ 1142 CCM_Invalid_Failure_Status 100;
BA_ "GenSigCycleTime" SG_ 1142 CCM_Invalid_Failure_Status 100;
BA_ "GenSigTimeoutTime_HU_Mid_X451" SG_ 1142 BCmMToFailureStatus 0;
BA_ "GenSigTimeoutTime_HU_High_X451" SG_ 1142 BCmMToFailureStatus 0;
BA_ "GenSigTimeoutTime_HU_B" SG_ 1142 BCmMToFailureStatus 0;
BA_ "GenSigTimeoutTime_HU_A" SG_ 1142 BCmMToFailureStatus 0;
BA_ "GenSigTimeoutMsg_HU_Mid_X451" SG_ 1142 BCmMToFailureStatus 0;
BA_ "GenSigTimeoutMsg_HU_High_X451" SG_ 1142 BCmMToFailureStatus 0;
BA_ "GenSigTimeoutMsg_HU_B" SG_ 1142 BCmMToFailureStatus 0;
BA_ "GenSigTimeoutMsg_HU_A" SG_ 1142 BCmMToFailureStatus 0;
BA_ "GenSigSendType" SG_ 1142 BCmMToFailureStatus 7;
BA_ "GenSigCycleTimeActive" SG_ 1142 BCmMToFailureStatus 100;
BA_ "GenSigCycleTime" SG_ 1142 BCmMToFailureStatus 100;
BA_ "GenSigTimeoutTime_HU_Mid_X451" SG_ 1827 Telematics_DiagRequest 0;
BA_ "GenSigTimeoutTime_HU_High_X451" SG_ 1827 Telematics_DiagRequest 0;
BA_ "GenSigTimeoutTime_HU_B" SG_ 1827 Telematics_DiagRequest 0;
BA_ "GenSigTimeoutTime_HU_A" SG_ 1827 Telematics_DiagRequest 0;
BA_ "GenSigTimeoutMsg_HU_Mid_X451" SG_ 1827 Telematics_DiagRequest 0;
BA_ "GenSigTimeoutMsg_HU_High_X451" SG_ 1827 Telematics_DiagRequest 0;
BA_ "GenSigTimeoutMsg_HU_B" SG_ 1827 Telematics_DiagRequest 0;
BA_ "GenSigTimeoutMsg_HU_A" SG_ 1827 Telematics_DiagRequest 0;
BA_ "GenSigSendType" SG_ 1827 Telematics_DiagRequest 1;
BA_ "GenSigTimeoutMsg_HU_High_X445" SG_ 1827 Telematics_DiagRequest 0;
BA_ "GenSigTimeoutMsg_HU_Mid_X445" SG_ 1827 Telematics_DiagRequest 0;
BA_ "GenSigTimeoutTime_HU_High_X445" SG_ 1827 Telematics_DiagRequest 0;
BA_ "GenSigTimeoutTime_HU_Mid_X445" SG_ 1827 Telematics_DiagRequest 0;
BA_ "GenSigTimeoutMsg_IVI" SG_ 1827 Telematics_DiagRequest 0;
BA_ "GenSigTimeoutTime_IVI" SG_ 1827 Telematics_DiagRequest 0;
BA_ "GenSigTimeoutTime_HU_Mid_X451" SG_ 1835 Telematics_DiagResponse_USDT 0;
BA_ "GenSigTimeoutTime_HU_High_X451" SG_ 1835 Telematics_DiagResponse_USDT 0;
BA_ "GenSigTimeoutTime_HU_B" SG_ 1835 Telematics_DiagResponse_USDT 0;
BA_ "GenSigTimeoutTime_HU_A" SG_ 1835 Telematics_DiagResponse_USDT 0;
BA_ "GenSigTimeoutMsg_HU_Mid_X451" SG_ 1835 Telematics_DiagResponse_USDT 0;
BA_ "GenSigTimeoutMsg_HU_High_X451" SG_ 1835 Telematics_DiagResponse_USDT 0;
BA_ "GenSigTimeoutMsg_HU_B" SG_ 1835 Telematics_DiagResponse_USDT 0;
BA_ "GenSigTimeoutMsg_HU_A" SG_ 1835 Telematics_DiagResponse_USDT 0;
BA_ "GenSigSendType" SG_ 1835 Telematics_DiagResponse_USDT 1;
BA_ "GenSigTimeoutMsg_HU_High_X445" SG_ 1835 Telematics_DiagResponse_USDT 0;
BA_ "GenSigTimeoutMsg_HU_Mid_X445" SG_ 1835 Telematics_DiagResponse_USDT 0;
BA_ "GenSigTimeoutTime_HU_High_X445" SG_ 1835 Telematics_DiagResponse_USDT 0;
BA_ "GenSigTimeoutTime_HU_Mid_X445" SG_ 1835 Telematics_DiagResponse_USDT 0;
BA_ "GenSigTimeoutMsg_IVI" SG_ 1835 Telematics_DiagResponse_USDT 0;
BA_ "GenSigTimeoutTime_IVI" SG_ 1835 Telematics_DiagResponse_USDT 0;
BA_ "GenSigTimeoutTime_HU_Mid_X451" SG_ 1579 Telematics_DiagResponse_UUDT 0;
BA_ "GenSigTimeoutTime_HU_High_X451" SG_ 1579 Telematics_DiagResponse_UUDT 0;
BA_ "GenSigTimeoutTime_HU_B" SG_ 1579 Telematics_DiagResponse_UUDT 0;
BA_ "GenSigTimeoutTime_HU_A" SG_ 1579 Telematics_DiagResponse_UUDT 0;
BA_ "GenSigTimeoutMsg_HU_Mid_X451" SG_ 1579 Telematics_DiagResponse_UUDT 0;
BA_ "GenSigTimeoutMsg_HU_High_X451" SG_ 1579 Telematics_DiagResponse_UUDT 0;
BA_ "GenSigTimeoutMsg_HU_B" SG_ 1579 Telematics_DiagResponse_UUDT 0;
BA_ "GenSigTimeoutMsg_HU_A" SG_ 1579 Telematics_DiagResponse_UUDT 0;
BA_ "GenSigSendType" SG_ 1579 Telematics_DiagResponse_UUDT 1;
BA_ "GenSigTimeoutMsg_HU_High_X445" SG_ 1579 Telematics_DiagResponse_UUDT 0;
BA_ "GenSigTimeoutMsg_HU_Mid_X445" SG_ 1579 Telematics_DiagResponse_UUDT 0;
BA_ "GenSigTimeoutTime_HU_High_X445" SG_ 1579 Telematics_DiagResponse_UUDT 0;
BA_ "GenSigTimeoutTime_HU_Mid_X445" SG_ 1579 Telematics_DiagResponse_UUDT 0;
BA_ "GenSigTimeoutMsg_IVI" SG_ 1579 Telematics_DiagResponse_UUDT 0;
BA_ "GenSigTimeoutTime_IVI" SG_ 1579 Telematics_DiagResponse_UUDT 0;
BA_ "GenSigSendType" SG_ 1184 GSS_EV_MTO_Failure_Status 7;
BA_ "GenSigCycleTimeActive" SG_ 1184 GSS_EV_MTO_Failure_Status 100;
BA_ "GenSigCycleTime" SG_ 1184 GSS_EV_MTO_Failure_Status 100;
BA_ "GenSigSendType" SG_ 1184 Telematics_MTO_Failure_status 7;
BA_ "GenSigCycleTimeActive" SG_ 1184 Telematics_MTO_Failure_status 100;
BA_ "GenSigCycleTime" SG_ 1184 Telematics_MTO_Failure_status 100;
BA_ "GenSigSendType" SG_ 1184 Telematics_Invalid_FailureStatus 7;
BA_ "GenSigCycleTimeActive" SG_ 1184 Telematics_Invalid_FailureStatus 100;
BA_ "GenSigCycleTime" SG_ 1184 Telematics_Invalid_FailureStatus 100;
BA_ "GenSigSendType" SG_ 1184 VCUMToFailureStatus 7;
BA_ "GenSigCycleTimeActive" SG_ 1184 VCUMToFailureStatus 100;
BA_ "GenSigCycleTime" SG_ 1184 VCUMToFailureStatus 100;
BA_ "GenSigSendType" SG_ 1184 VCUInvalidFailureStatus 7;
BA_ "GenSigCycleTimeActive" SG_ 1184 VCUInvalidFailureStatus 100;
BA_ "GenSigCycleTime" SG_ 1184 VCUInvalidFailureStatus 100;
BA_ "GenSigTimeoutTime_HU_Mid_X451" SG_ 493 CarAnniversary 0;
BA_ "GenSigTimeoutTime_HU_High_X451" SG_ 493 CarAnniversary 0;
BA_ "GenSigTimeoutTime_HU_B" SG_ 493 CarAnniversary 0;
BA_ "GenSigTimeoutTime_HU_A" SG_ 493 CarAnniversary 0;
BA_ "GenSigTimeoutMsg_HU_Mid_X451" SG_ 493 CarAnniversary 0;
BA_ "GenSigTimeoutMsg_HU_High_X451" SG_ 493 CarAnniversary 0;
BA_ "GenSigTimeoutMsg_HU_B" SG_ 493 CarAnniversary 0;
BA_ "GenSigTimeoutMsg_HU_A" SG_ 493 CarAnniversary 0;
BA_ "GenSigSendType" SG_ 493 CarAnniversary 2;
BA_ "GenSigTimeoutMsg_HU_High_X445" SG_ 493 CarAnniversary 0;
BA_ "GenSigTimeoutMsg_HU_Mid_X445" SG_ 493 CarAnniversary 0;
BA_ "GenSigTimeoutTime_HU_High_X445" SG_ 493 CarAnniversary 0;
BA_ "GenSigTimeoutTime_HU_Mid_X445" SG_ 493 CarAnniversary 0;
BA_ "GenSigTimeoutMsg_IVI" SG_ 493 CarAnniversary 0;
BA_ "GenSigTimeoutTime_IVI" SG_ 493 CarAnniversary 0;
BA_ "GenSigTimeoutTime_HU_Mid_X451" SG_ 493 OwnersAnniversary 0;
BA_ "GenSigTimeoutTime_HU_High_X451" SG_ 493 OwnersAnniversary 0;
BA_ "GenSigTimeoutTime_HU_B" SG_ 493 OwnersAnniversary 0;
BA_ "GenSigTimeoutTime_HU_A" SG_ 493 OwnersAnniversary 0;
BA_ "GenSigTimeoutMsg_HU_Mid_X451" SG_ 493 OwnersAnniversary 0;
BA_ "GenSigTimeoutMsg_HU_High_X451" SG_ 493 OwnersAnniversary 0;
BA_ "GenSigTimeoutMsg_HU_B" SG_ 493 OwnersAnniversary 0;
BA_ "GenSigTimeoutMsg_HU_A" SG_ 493 OwnersAnniversary 0;
BA_ "GenSigSendType" SG_ 493 OwnersAnniversary 2;
BA_ "GenSigTimeoutMsg_HU_High_X445" SG_ 493 OwnersAnniversary 0;
BA_ "GenSigTimeoutMsg_HU_Mid_X445" SG_ 493 OwnersAnniversary 0;
BA_ "GenSigTimeoutTime_HU_High_X445" SG_ 493 OwnersAnniversary 0;
BA_ "GenSigTimeoutTime_HU_Mid_X445" SG_ 493 OwnersAnniversary 0;
BA_ "GenSigTimeoutMsg_IVI" SG_ 493 OwnersAnniversary 0;
BA_ "GenSigTimeoutTime_IVI" SG_ 493 OwnersAnniversary 0;
BA_ "GenSigTimeoutTime_HU_Mid_X451" SG_ 493 OwnersBirthday 0;
BA_ "GenSigTimeoutTime_HU_High_X451" SG_ 493 OwnersBirthday 0;
BA_ "GenSigTimeoutTime_HU_B" SG_ 493 OwnersBirthday 0;
BA_ "GenSigTimeoutTime_HU_A" SG_ 493 OwnersBirthday 0;
BA_ "GenSigTimeoutMsg_HU_Mid_X451" SG_ 493 OwnersBirthday 0;
BA_ "GenSigTimeoutMsg_HU_High_X451" SG_ 493 OwnersBirthday 0;
BA_ "GenSigTimeoutMsg_HU_B" SG_ 493 OwnersBirthday 0;
BA_ "GenSigTimeoutMsg_HU_A" SG_ 493 OwnersBirthday 0;
BA_ "GenSigSendType" SG_ 493 OwnersBirthday 2;
BA_ "GenSigTimeoutMsg_HU_High_X445" SG_ 493 OwnersBirthday 0;
BA_ "GenSigTimeoutMsg_HU_Mid_X445" SG_ 493 OwnersBirthday 0;
BA_ "GenSigTimeoutTime_HU_High_X445" SG_ 493 OwnersBirthday 0;
BA_ "GenSigTimeoutTime_HU_Mid_X445" SG_ 493 OwnersBirthday 0;
BA_ "GenSigTimeoutMsg_IVI" SG_ 493 OwnersBirthday 0;
BA_ "GenSigTimeoutTime_IVI" SG_ 493 OwnersBirthday 0;
BA_ "GenSigSendType" SG_ 581 HvChargeTypeStatus 7;
BA_ "GenSigCycleTimeActive" SG_ 581 HvChargeTypeStatus 100;
BA_ "GenSigCycleTime" SG_ 581 HvChargeTypeStatus 100;
BA_ "GenSigSendType" SG_ 581 HvChargeType 7;
BA_ "GenSigCycleTimeActive" SG_ 581 HvChargeType 100;
BA_ "GenSigCycleTime" SG_ 581 HvChargeType 100;
BA_ "GenSigSendType" SG_ 581 HvChargingStateStatus 7;
BA_ "GenSigCycleTimeActive" SG_ 581 HvChargingStateStatus 100;
BA_ "GenSigCycleTime" SG_ 581 HvChargingStateStatus 100;
BA_ "GenSigSendType" SG_ 581 HvChargingState 7;
BA_ "GenSigCycleTimeActive" SG_ 581 HvChargingState 100;
BA_ "GenSigCycleTime" SG_ 581 HvChargingState 100;
BA_ "GenSigSendType" SG_ 581 TimetoChargeHVMintsStatus 7;
BA_ "GenSigCycleTimeActive" SG_ 581 TimetoChargeHVMintsStatus 100;
BA_ "GenSigCycleTime" SG_ 581 TimetoChargeHVMintsStatus 100;
BA_ "GenSigSendType" SG_ 581 TimetoChargeHVMints 7;
BA_ "GenSigCycleTimeActive" SG_ 581 TimetoChargeHVMints 100;
BA_ "GenSigCycleTime" SG_ 581 TimetoChargeHVMints 100;
BA_ "GenSigSendType" SG_ 581 TimetoChargeHVHoursStatus 7;
BA_ "GenSigCycleTimeActive" SG_ 581 TimetoChargeHVHoursStatus 100;
BA_ "GenSigCycleTime" SG_ 581 TimetoChargeHVHoursStatus 100;
BA_ "GenSigSendType" SG_ 581 TimetoChargeHVHours 7;
BA_ "GenSigCycleTimeActive" SG_ 581 TimetoChargeHVHours 100;
BA_ "GenSigCycleTime" SG_ 581 TimetoChargeHVHours 100;
BA_ "GenSigTimeoutTime_HU_Mid_X451" SG_ 581 CoolingPwrFdbkVal 0;
BA_ "GenSigTimeoutTime_HU_High_X451" SG_ 581 CoolingPwrFdbkVal 0;
BA_ "GenSigTimeoutTime_HU_B" SG_ 581 CoolingPwrFdbkVal 0;
BA_ "GenSigTimeoutTime_HU_A" SG_ 581 CoolingPwrFdbkVal 0;
BA_ "GenSigTimeoutMsg_HU_Mid_X451" SG_ 581 CoolingPwrFdbkVal 0;
BA_ "GenSigTimeoutMsg_HU_High_X451" SG_ 581 CoolingPwrFdbkVal 0;
BA_ "GenSigTimeoutMsg_HU_B" SG_ 581 CoolingPwrFdbkVal 0;
BA_ "GenSigTimeoutMsg_HU_A" SG_ 581 CoolingPwrFdbkVal 0;
BA_ "GenSigSendType" SG_ 581 CoolingPwrFdbkVal 7;
BA_ "GenSigCycleTimeActive" SG_ 581 CoolingPwrFdbkVal 100;
BA_ "GenSigCycleTime" SG_ 581 CoolingPwrFdbkVal 100;
BA_ "GenSigTimeoutMsg_HU_High_X445" SG_ 581 CoolingPwrFdbkVal 0;
BA_ "GenSigTimeoutMsg_HU_Mid_X445" SG_ 581 CoolingPwrFdbkVal 0;
BA_ "GenSigTimeoutTime_HU_High_X445" SG_ 581 CoolingPwrFdbkVal 0;
BA_ "GenSigTimeoutTime_HU_Mid_X445" SG_ 581 CoolingPwrFdbkVal 0;
BA_ "GenSigTimeoutTime_HU_Mid_X451" SG_ 581 HeatingPwrFdbkVal 0;
BA_ "GenSigTimeoutTime_HU_High_X451" SG_ 581 HeatingPwrFdbkVal 0;
BA_ "GenSigTimeoutTime_HU_B" SG_ 581 HeatingPwrFdbkVal 0;
BA_ "GenSigTimeoutTime_HU_A" SG_ 581 HeatingPwrFdbkVal 0;
BA_ "GenSigTimeoutMsg_HU_Mid_X451" SG_ 581 HeatingPwrFdbkVal 0;
BA_ "GenSigTimeoutMsg_HU_High_X451" SG_ 581 HeatingPwrFdbkVal 0;
BA_ "GenSigTimeoutMsg_HU_B" SG_ 581 HeatingPwrFdbkVal 0;
BA_ "GenSigTimeoutMsg_HU_A" SG_ 581 HeatingPwrFdbkVal 0;
BA_ "GenSigSendType" SG_ 581 HeatingPwrFdbkVal 7;
BA_ "GenSigCycleTimeActive" SG_ 581 HeatingPwrFdbkVal 100;
BA_ "GenSigCycleTime" SG_ 581 HeatingPwrFdbkVal 100;
BA_ "GenSigTimeoutMsg_HU_High_X445" SG_ 581 HeatingPwrFdbkVal 0;
BA_ "GenSigTimeoutMsg_HU_Mid_X445" SG_ 581 HeatingPwrFdbkVal 0;
BA_ "GenSigTimeoutTime_HU_High_X445" SG_ 581 HeatingPwrFdbkVal 0;
BA_ "GenSigTimeoutTime_HU_Mid_X445" SG_ 581 HeatingPwrFdbkVal 0;
BA_ "GenSigTimeoutTime_HU_Mid_X451" SG_ 581 CabinCoolingSolValveStateStatus 0;
BA_ "GenSigTimeoutTime_HU_High_X451" SG_ 581 CabinCoolingSolValveStateStatus 0;
BA_ "GenSigTimeoutTime_HU_B" SG_ 581 CabinCoolingSolValveStateStatus 0;
BA_ "GenSigTimeoutTime_HU_A" SG_ 581 CabinCoolingSolValveStateStatus 0;
BA_ "GenSigTimeoutMsg_HU_Mid_X451" SG_ 581 CabinCoolingSolValveStateStatus 0;
BA_ "GenSigTimeoutMsg_HU_High_X451" SG_ 581 CabinCoolingSolValveStateStatus 0;
BA_ "GenSigTimeoutMsg_HU_B" SG_ 581 CabinCoolingSolValveStateStatus 0;
BA_ "GenSigTimeoutMsg_HU_A" SG_ 581 CabinCoolingSolValveStateStatus 0;
BA_ "GenSigSendType" SG_ 581 CabinCoolingSolValveStateStatus 7;
BA_ "GenSigCycleTimeActive" SG_ 581 CabinCoolingSolValveStateStatus 100;
BA_ "GenSigCycleTime" SG_ 581 CabinCoolingSolValveStateStatus 100;
BA_ "GenSigTimeoutTime_HU_Mid_X451" SG_ 581 CabinCoolingSolValveState 0;
BA_ "GenSigTimeoutTime_HU_High_X451" SG_ 581 CabinCoolingSolValveState 0;
BA_ "GenSigTimeoutTime_HU_B" SG_ 581 CabinCoolingSolValveState 0;
BA_ "GenSigTimeoutTime_HU_A" SG_ 581 CabinCoolingSolValveState 0;
BA_ "GenSigTimeoutMsg_HU_Mid_X451" SG_ 581 CabinCoolingSolValveState 0;
BA_ "GenSigTimeoutMsg_HU_High_X451" SG_ 581 CabinCoolingSolValveState 0;
BA_ "GenSigTimeoutMsg_HU_B" SG_ 581 CabinCoolingSolValveState 0;
BA_ "GenSigTimeoutMsg_HU_A" SG_ 581 CabinCoolingSolValveState 0;
BA_ "GenSigSendType" SG_ 581 CabinCoolingSolValveState 7;
BA_ "GenSigCycleTimeActive" SG_ 581 CabinCoolingSolValveState 100;
BA_ "GenSigCycleTime" SG_ 581 CabinCoolingSolValveState 100;
BA_ "GenSigTimeoutTime_HU_Mid_X451" SG_ 581 LowHVBatteryChargeStatus 0;
BA_ "GenSigTimeoutTime_HU_High_X451" SG_ 581 LowHVBatteryChargeStatus 0;
BA_ "GenSigTimeoutTime_HU_B" SG_ 581 LowHVBatteryChargeStatus 0;
BA_ "GenSigTimeoutTime_HU_A" SG_ 581 LowHVBatteryChargeStatus 0;
BA_ "GenSigTimeoutMsg_HU_Mid_X451" SG_ 581 LowHVBatteryChargeStatus 0;
BA_ "GenSigTimeoutMsg_HU_High_X451" SG_ 581 LowHVBatteryChargeStatus 0;
BA_ "GenSigTimeoutMsg_HU_B" SG_ 581 LowHVBatteryChargeStatus 0;
BA_ "GenSigTimeoutMsg_HU_A" SG_ 581 LowHVBatteryChargeStatus 0;
BA_ "GenSigSendType" SG_ 581 LowHVBatteryChargeStatus 7;
BA_ "GenSigCycleTimeActive" SG_ 581 LowHVBatteryChargeStatus 100;
BA_ "GenSigCycleTime" SG_ 581 LowHVBatteryChargeStatus 100;
BA_ "GenSigTimeoutTime_HU_Mid_X451" SG_ 581 LowHVBatteryCharge 0;
BA_ "GenSigTimeoutTime_HU_High_X451" SG_ 581 LowHVBatteryCharge 0;
BA_ "GenSigTimeoutTime_HU_B" SG_ 581 LowHVBatteryCharge 0;
BA_ "GenSigTimeoutTime_HU_A" SG_ 581 LowHVBatteryCharge 0;
BA_ "GenSigTimeoutMsg_HU_Mid_X451" SG_ 581 LowHVBatteryCharge 0;
BA_ "GenSigTimeoutMsg_HU_High_X451" SG_ 581 LowHVBatteryCharge 0;
BA_ "GenSigTimeoutMsg_HU_B" SG_ 581 LowHVBatteryCharge 0;
BA_ "GenSigTimeoutMsg_HU_A" SG_ 581 LowHVBatteryCharge 0;
BA_ "GenSigSendType" SG_ 581 LowHVBatteryCharge 7;
BA_ "GenSigCycleTimeActive" SG_ 581 LowHVBatteryCharge 100;
BA_ "GenSigCycleTime" SG_ 581 LowHVBatteryCharge 100;
BA_ "GenSigTimeoutTime_HU_Mid_X451" SG_ 581 LowLVBatteryChargeStatus 0;
BA_ "GenSigTimeoutTime_HU_High_X451" SG_ 581 LowLVBatteryChargeStatus 0;
BA_ "GenSigTimeoutTime_HU_B" SG_ 581 LowLVBatteryChargeStatus 0;
BA_ "GenSigTimeoutTime_HU_A" SG_ 581 LowLVBatteryChargeStatus 0;
BA_ "GenSigTimeoutMsg_HU_Mid_X451" SG_ 581 LowLVBatteryChargeStatus 0;
BA_ "GenSigTimeoutMsg_HU_High_X451" SG_ 581 LowLVBatteryChargeStatus 0;
BA_ "GenSigTimeoutMsg_HU_B" SG_ 581 LowLVBatteryChargeStatus 0;
BA_ "GenSigTimeoutMsg_HU_A" SG_ 581 LowLVBatteryChargeStatus 0;
BA_ "GenSigSendType" SG_ 581 LowLVBatteryChargeStatus 7;
BA_ "GenSigCycleTimeActive" SG_ 581 LowLVBatteryChargeStatus 100;
BA_ "GenSigCycleTime" SG_ 581 LowLVBatteryChargeStatus 100;
BA_ "GenSigTimeoutTime_HU_Mid_X451" SG_ 581 LowLVBatteryCharge 0;
BA_ "GenSigTimeoutTime_HU_High_X451" SG_ 581 LowLVBatteryCharge 0;
BA_ "GenSigTimeoutTime_HU_B" SG_ 581 LowLVBatteryCharge 0;
BA_ "GenSigTimeoutTime_HU_A" SG_ 581 LowLVBatteryCharge 0;
BA_ "GenSigTimeoutMsg_HU_Mid_X451" SG_ 581 LowLVBatteryCharge 0;
BA_ "GenSigTimeoutMsg_HU_High_X451" SG_ 581 LowLVBatteryCharge 0;
BA_ "GenSigTimeoutMsg_HU_B" SG_ 581 LowLVBatteryCharge 0;
BA_ "GenSigTimeoutMsg_HU_A" SG_ 581 LowLVBatteryCharge 0;
BA_ "GenSigSendType" SG_ 581 LowLVBatteryCharge 7;
BA_ "GenSigCycleTimeActive" SG_ 581 LowLVBatteryCharge 100;
BA_ "GenSigCycleTime" SG_ 581 LowLVBatteryCharge 100;
BA_ "GenSigSendType" SG_ 581 HvAmpHrStatus 7;
BA_ "GenSigCycleTimeActive" SG_ 581 HvAmpHrStatus 100;
BA_ "GenSigCycleTime" SG_ 581 HvAmpHrStatus 100;
BA_ "GenSigSendType" SG_ 581 HvAmpHr 7;
BA_ "GenSigCycleTimeActive" SG_ 581 HvAmpHr 100;
BA_ "GenSigCycleTime" SG_ 581 HvAmpHr 100;
BA_ "GenSigTimeoutTime_HU_Mid_X451" SG_ 1171 VCUMToFailureStatus 0;
BA_ "GenSigTimeoutTime_HU_High_X451" SG_ 1171 VCUMToFailureStatus 0;
BA_ "GenSigTimeoutTime_HU_B" SG_ 1171 VCUMToFailureStatus 0;
BA_ "GenSigTimeoutTime_HU_A" SG_ 1171 VCUMToFailureStatus 0;
BA_ "GenSigTimeoutMsg_HU_Mid_X451" SG_ 1171 VCUMToFailureStatus 0;
BA_ "GenSigTimeoutMsg_HU_High_X451" SG_ 1171 VCUMToFailureStatus 0;
BA_ "GenSigTimeoutMsg_HU_B" SG_ 1171 VCUMToFailureStatus 0;
BA_ "GenSigTimeoutMsg_HU_A" SG_ 1171 VCUMToFailureStatus 0;
BA_ "GenSigSendType" SG_ 1171 VCUMToFailureStatus 7;
BA_ "GenSigCycleTimeActive" SG_ 1171 VCUMToFailureStatus 100;
BA_ "GenSigCycleTime" SG_ 1171 VCUMToFailureStatus 100;
BA_ "GenSigTimeoutTime_HU_Mid_X451" SG_ 1171 VCUInvalidFailureStatus 0;
BA_ "GenSigTimeoutTime_HU_High_X451" SG_ 1171 VCUInvalidFailureStatus 0;
BA_ "GenSigTimeoutTime_HU_B" SG_ 1171 VCUInvalidFailureStatus 0;
BA_ "GenSigTimeoutTime_HU_A" SG_ 1171 VCUInvalidFailureStatus 0;
BA_ "GenSigTimeoutMsg_HU_Mid_X451" SG_ 1171 VCUInvalidFailureStatus 0;
BA_ "GenSigTimeoutMsg_HU_High_X451" SG_ 1171 VCUInvalidFailureStatus 0;
BA_ "GenSigTimeoutMsg_HU_B" SG_ 1171 VCUInvalidFailureStatus 0;
BA_ "GenSigTimeoutMsg_HU_A" SG_ 1171 VCUInvalidFailureStatus 0;
BA_ "GenSigSendType" SG_ 1171 VCUInvalidFailureStatus 7;
BA_ "GenSigCycleTimeActive" SG_ 1171 VCUInvalidFailureStatus 100;
BA_ "GenSigCycleTime" SG_ 1171 VCUInvalidFailureStatus 100;
BA_ "GenSigSendType" SG_ 1330 P_Status 7;
BA_ "GenSigCycleTimeActive" SG_ 1330 P_Status 100;
BA_ "GenSigCycleTime" SG_ 1330 P_Status 100;
BA_ "GenSigSendType" SG_ 1330 SolarLoad 7;
BA_ "GenSigCycleTimeActive" SG_ 1330 SolarLoad 100;
BA_ "GenSigCycleTime" SG_ 1330 SolarLoad 100;
BA_ "GenSigStartValue" SG_ 1330 P_SensorTemp 400;
BA_ "GenSigSendType" SG_ 1330 P_SensorTemp 7;
BA_ "GenSigCycleTimeActive" SG_ 1330 P_SensorTemp 100;
BA_ "GenSigCycleTime" SG_ 1330 P_SensorTemp 100;
BA_ "GenSigSendType" SG_ 1330 P_ResponsErr 7;
BA_ "GenSigCycleTimeActive" SG_ 1330 P_ResponsErr 100;
BA_ "GenSigCycleTime" SG_ 1330 P_ResponsErr 100;
BA_ "GenSigSendType" SG_ 1330 P_TempError 7;
BA_ "GenSigCycleTimeActive" SG_ 1330 P_TempError 100;
BA_ "GenSigCycleTime" SG_ 1330 P_TempError 100;
BA_ "GenSigSendType" SG_ 1330 P_TempOverHeat 7;
BA_ "GenSigCycleTimeActive" SG_ 1330 P_TempOverHeat 100;
BA_ "GenSigCycleTime" SG_ 1330 P_TempOverHeat 100;
BA_ "GenSigSendType" SG_ 1330 P_SensorChange 7;
BA_ "GenSigCycleTimeActive" SG_ 1330 P_SensorChange 100;
BA_ "GenSigCycleTime" SG_ 1330 P_SensorChange 100;
BA_ "GenSigSendType" SG_ 1330 P_MotorError 7;
BA_ "GenSigCycleTimeActive" SG_ 1330 P_MotorError 100;
BA_ "GenSigCycleTime" SG_ 1330 P_MotorError 100;
BA_ "GenSigSendType" SG_ 1330 P_Initialization 7;
BA_ "GenSigCycleTimeActive" SG_ 1330 P_Initialization 100;
BA_ "GenSigCycleTime" SG_ 1330 P_Initialization 100;
BA_ "GenSigSendType" SG_ 1330 P_HighTempMode 7;
BA_ "GenSigCycleTimeActive" SG_ 1330 P_HighTempMode 100;
BA_ "GenSigCycleTime" SG_ 1330 P_HighTempMode 100;
BA_ "GenSigSendType" SG_ 1330 C_LinError 7;
BA_ "GenSigCycleTimeActive" SG_ 1330 C_LinError 100;
BA_ "GenSigCycleTime" SG_ 1330 C_LinError 100;
BA_ "GenSigSendType" SG_ 1330 C_Operation 7;
BA_ "GenSigCycleTimeActive" SG_ 1330 C_Operation 100;
BA_ "GenSigCycleTime" SG_ 1330 C_Operation 100;
BA_ "GenSigSendType" SG_ 1330 Approximated_Solar_Load 7;
BA_ "GenSigCycleTimeActive" SG_ 1330 Approximated_Solar_Load 100;
BA_ "GenSigCycleTime" SG_ 1330 Approximated_Solar_Load 100;
BA_ "GenSigSendType" SG_ 1329 SolarLoad 7;
BA_ "GenSigCycleTimeActive" SG_ 1329 SolarLoad 100;
BA_ "GenSigCycleTime" SG_ 1329 SolarLoad 100;
BA_ "GenSigTimeoutTime_HU_Mid_X451" SG_ 1329 RecircFlapFeedbackVtg 0;
BA_ "GenSigTimeoutTime_HU_High_X451" SG_ 1329 RecircFlapFeedbackVtg 0;
BA_ "GenSigTimeoutTime_HU_B" SG_ 1329 RecircFlapFeedbackVtg 0;
BA_ "GenSigTimeoutTime_HU_A" SG_ 1329 RecircFlapFeedbackVtg 0;
BA_ "GenSigTimeoutMsg_HU_Mid_X451" SG_ 1329 RecircFlapFeedbackVtg 0;
BA_ "GenSigTimeoutMsg_HU_High_X451" SG_ 1329 RecircFlapFeedbackVtg 0;
BA_ "GenSigTimeoutMsg_HU_B" SG_ 1329 RecircFlapFeedbackVtg 0;
BA_ "GenSigTimeoutMsg_HU_A" SG_ 1329 RecircFlapFeedbackVtg 0;
BA_ "GenSigSendType" SG_ 1329 RecircFlapFeedbackVtg 7;
BA_ "GenSigCycleTimeActive" SG_ 1329 RecircFlapFeedbackVtg 100;
BA_ "GenSigCycleTime" SG_ 1329 RecircFlapFeedbackVtg 100;
BA_ "GenSigTimeoutTime_HU_Mid_X451" SG_ 1329 ModeFlapFeedbackVtg 0;
BA_ "GenSigTimeoutTime_HU_High_X451" SG_ 1329 ModeFlapFeedbackVtg 0;
BA_ "GenSigTimeoutTime_HU_B" SG_ 1329 ModeFlapFeedbackVtg 0;
BA_ "GenSigTimeoutTime_HU_A" SG_ 1329 ModeFlapFeedbackVtg 0;
BA_ "GenSigTimeoutMsg_HU_Mid_X451" SG_ 1329 ModeFlapFeedbackVtg 0;
BA_ "GenSigTimeoutMsg_HU_High_X451" SG_ 1329 ModeFlapFeedbackVtg 0;
BA_ "GenSigTimeoutMsg_HU_B" SG_ 1329 ModeFlapFeedbackVtg 0;
BA_ "GenSigTimeoutMsg_HU_A" SG_ 1329 ModeFlapFeedbackVtg 0;
BA_ "GenSigSendType" SG_ 1329 ModeFlapFeedbackVtg 7;
BA_ "GenSigCycleTimeActive" SG_ 1329 ModeFlapFeedbackVtg 100;
BA_ "GenSigCycleTime" SG_ 1329 ModeFlapFeedbackVtg 100;
BA_ "GenSigTimeoutTime_HU_Mid_X451" SG_ 1329 TempFlapFeedbackVtg 0;
BA_ "GenSigTimeoutTime_HU_High_X451" SG_ 1329 TempFlapFeedbackVtg 0;
BA_ "GenSigTimeoutTime_HU_B" SG_ 1329 TempFlapFeedbackVtg 0;
BA_ "GenSigTimeoutTime_HU_A" SG_ 1329 TempFlapFeedbackVtg 0;
BA_ "GenSigTimeoutMsg_HU_Mid_X451" SG_ 1329 TempFlapFeedbackVtg 0;
BA_ "GenSigTimeoutMsg_HU_High_X451" SG_ 1329 TempFlapFeedbackVtg 0;
BA_ "GenSigTimeoutMsg_HU_B" SG_ 1329 TempFlapFeedbackVtg 0;
BA_ "GenSigTimeoutMsg_HU_A" SG_ 1329 TempFlapFeedbackVtg 0;
BA_ "GenSigSendType" SG_ 1329 TempFlapFeedbackVtg 7;
BA_ "GenSigCycleTimeActive" SG_ 1329 TempFlapFeedbackVtg 100;
BA_ "GenSigCycleTime" SG_ 1329 TempFlapFeedbackVtg 100;
BA_ "GenSigTimeoutTime_HU_Mid_X451" SG_ 1329 RecircFlapPos 0;
BA_ "GenSigTimeoutTime_HU_High_X451" SG_ 1329 RecircFlapPos 0;
BA_ "GenSigTimeoutTime_HU_B" SG_ 1329 RecircFlapPos 0;
BA_ "GenSigTimeoutTime_HU_A" SG_ 1329 RecircFlapPos 0;
BA_ "GenSigTimeoutMsg_HU_Mid_X451" SG_ 1329 RecircFlapPos 0;
BA_ "GenSigTimeoutMsg_HU_High_X451" SG_ 1329 RecircFlapPos 0;
BA_ "GenSigTimeoutMsg_HU_B" SG_ 1329 RecircFlapPos 0;
BA_ "GenSigTimeoutMsg_HU_A" SG_ 1329 RecircFlapPos 0;
BA_ "GenSigSendType" SG_ 1329 RecircFlapPos 7;
BA_ "GenSigCycleTimeActive" SG_ 1329 RecircFlapPos 100;
BA_ "GenSigCycleTime" SG_ 1329 RecircFlapPos 100;
BA_ "GenSigTimeoutTime_HU_Mid_X451" SG_ 1329 ModeFlapPos 0;
BA_ "GenSigTimeoutTime_HU_High_X451" SG_ 1329 ModeFlapPos 0;
BA_ "GenSigTimeoutTime_HU_B" SG_ 1329 ModeFlapPos 0;
BA_ "GenSigTimeoutTime_HU_A" SG_ 1329 ModeFlapPos 0;
BA_ "GenSigTimeoutMsg_HU_Mid_X451" SG_ 1329 ModeFlapPos 0;
BA_ "GenSigTimeoutMsg_HU_High_X451" SG_ 1329 ModeFlapPos 0;
BA_ "GenSigTimeoutMsg_HU_B" SG_ 1329 ModeFlapPos 0;
BA_ "GenSigTimeoutMsg_HU_A" SG_ 1329 ModeFlapPos 0;
BA_ "GenSigSendType" SG_ 1329 ModeFlapPos 7;
BA_ "GenSigCycleTimeActive" SG_ 1329 ModeFlapPos 100;
BA_ "GenSigCycleTime" SG_ 1329 ModeFlapPos 100;
BA_ "GenSigTimeoutTime_HU_Mid_X451" SG_ 1329 TempFlapPos 0;
BA_ "GenSigTimeoutTime_HU_High_X451" SG_ 1329 TempFlapPos 0;
BA_ "GenSigTimeoutTime_HU_B" SG_ 1329 TempFlapPos 0;
BA_ "GenSigTimeoutTime_HU_A" SG_ 1329 TempFlapPos 0;
BA_ "GenSigTimeoutMsg_HU_Mid_X451" SG_ 1329 TempFlapPos 0;
BA_ "GenSigTimeoutMsg_HU_High_X451" SG_ 1329 TempFlapPos 0;
BA_ "GenSigTimeoutMsg_HU_B" SG_ 1329 TempFlapPos 0;
BA_ "GenSigTimeoutMsg_HU_A" SG_ 1329 TempFlapPos 0;
BA_ "GenSigSendType" SG_ 1329 TempFlapPos 7;
BA_ "GenSigCycleTimeActive" SG_ 1329 TempFlapPos 100;
BA_ "GenSigCycleTime" SG_ 1329 TempFlapPos 100;
BA_ "GenSigTimeoutTime_HU_Mid_X451" SG_ 1329 ERLVal 0;
BA_ "GenSigTimeoutTime_HU_High_X451" SG_ 1329 ERLVal 0;
BA_ "GenSigTimeoutTime_HU_B" SG_ 1329 ERLVal 0;
BA_ "GenSigTimeoutTime_HU_A" SG_ 1329 ERLVal 0;
BA_ "GenSigTimeoutMsg_HU_Mid_X451" SG_ 1329 ERLVal 0;
BA_ "GenSigTimeoutMsg_HU_High_X451" SG_ 1329 ERLVal 0;
BA_ "GenSigTimeoutMsg_HU_B" SG_ 1329 ERLVal 0;
BA_ "GenSigTimeoutMsg_HU_A" SG_ 1329 ERLVal 0;
BA_ "GenSigSendType" SG_ 1329 ERLVal 7;
BA_ "GenSigCycleTimeActive" SG_ 1329 ERLVal 100;
BA_ "GenSigCycleTime" SG_ 1329 ERLVal 100;
BA_ "GenSigTimeoutTime_HU_Mid_X451" SG_ 1288 PartialNetworkInformation_TM 1000;
BA_ "GenSigTimeoutTime_HU_High_X451" SG_ 1288 PartialNetworkInformation_TM 1000;
BA_ "GenSigTimeoutTime_HU_B" SG_ 1288 PartialNetworkInformation_TM 1000;
BA_ "GenSigTimeoutTime_HU_A" SG_ 1288 PartialNetworkInformation_TM 1000;
BA_ "GenSigTimeoutMsg_HU_Mid_X451" SG_ 1288 PartialNetworkInformation_TM 1000;
BA_ "GenSigTimeoutMsg_HU_High_X451" SG_ 1288 PartialNetworkInformation_TM 1000;
BA_ "GenSigTimeoutMsg_HU_B" SG_ 1288 PartialNetworkInformation_TM 1000;
BA_ "GenSigTimeoutMsg_HU_A" SG_ 1288 PartialNetworkInformation_TM 1000;
BA_ "GenSigSendType" SG_ 1288 PartialNetworkInformation_TM 7;
BA_ "GenSigCycleTimeActive" SG_ 1288 PartialNetworkInformation_TM 200;
BA_ "GenSigCycleTime" SG_ 1288 PartialNetworkInformation_TM 200;
BA_ "GenSigTimeoutMsg_HU_High_X445" SG_ 1288 PartialNetworkInformation_TM 1000;
BA_ "GenSigTimeoutMsg_HU_Mid_X445" SG_ 1288 PartialNetworkInformation_TM 1000;
BA_ "GenSigTimeoutTime_HU_High_X445" SG_ 1288 PartialNetworkInformation_TM 1000;
BA_ "GenSigTimeoutTime_HU_Mid_X445" SG_ 1288 PartialNetworkInformation_TM 1000;
BA_ "GenSigTimeoutMsg_IVI" SG_ 1288 PartialNetworkInformation_TM 1000;
BA_ "GenSigTimeoutTime_IVI" SG_ 1288 PartialNetworkInformation_TM 1000;
BA_ "GenSigTimeoutTime_HU_Mid_X451" SG_ 1288 Reserved55 1000;
BA_ "GenSigTimeoutTime_HU_High_X451" SG_ 1288 Reserved55 1000;
BA_ "GenSigTimeoutTime_HU_B" SG_ 1288 Reserved55 1000;
BA_ "GenSigTimeoutTime_HU_A" SG_ 1288 Reserved55 1000;
BA_ "GenSigTimeoutMsg_HU_Mid_X451" SG_ 1288 Reserved55 1000;
BA_ "GenSigTimeoutMsg_HU_High_X451" SG_ 1288 Reserved55 1000;
BA_ "GenSigTimeoutMsg_HU_B" SG_ 1288 Reserved55 1000;
BA_ "GenSigTimeoutMsg_HU_A" SG_ 1288 Reserved55 1000;
BA_ "GenSigSendType" SG_ 1288 Reserved55 7;
BA_ "GenSigCycleTimeActive" SG_ 1288 Reserved55 200;
BA_ "GenSigCycleTime" SG_ 1288 Reserved55 200;
BA_ "GenSigTimeoutMsg_HU_High_X445" SG_ 1288 Reserved55 1000;
BA_ "GenSigTimeoutMsg_HU_Mid_X445" SG_ 1288 Reserved55 1000;
BA_ "GenSigTimeoutTime_HU_High_X445" SG_ 1288 Reserved55 1000;
BA_ "GenSigTimeoutTime_HU_Mid_X445" SG_ 1288 Reserved55 1000;
BA_ "GenSigTimeoutMsg_IVI" SG_ 1288 Reserved55 1000;
BA_ "GenSigTimeoutTime_IVI" SG_ 1288 Reserved55 1000;
BA_ "GenSigTimeoutTime_HU_Mid_X451" SG_ 1288 Reserved54 1000;
BA_ "GenSigTimeoutTime_HU_High_X451" SG_ 1288 Reserved54 1000;
BA_ "GenSigTimeoutTime_HU_B" SG_ 1288 Reserved54 1000;
BA_ "GenSigTimeoutTime_HU_A" SG_ 1288 Reserved54 1000;
BA_ "GenSigTimeoutMsg_HU_Mid_X451" SG_ 1288 Reserved54 1000;
BA_ "GenSigTimeoutMsg_HU_High_X451" SG_ 1288 Reserved54 1000;
BA_ "GenSigTimeoutMsg_HU_B" SG_ 1288 Reserved54 1000;
BA_ "GenSigTimeoutMsg_HU_A" SG_ 1288 Reserved54 1000;
BA_ "GenSigSendType" SG_ 1288 Reserved54 7;
BA_ "GenSigCycleTimeActive" SG_ 1288 Reserved54 200;
BA_ "GenSigCycleTime" SG_ 1288 Reserved54 200;
BA_ "GenSigTimeoutMsg_HU_High_X445" SG_ 1288 Reserved54 1000;
BA_ "GenSigTimeoutMsg_HU_Mid_X445" SG_ 1288 Reserved54 1000;
BA_ "GenSigTimeoutTime_HU_High_X445" SG_ 1288 Reserved54 1000;
BA_ "GenSigTimeoutTime_HU_Mid_X445" SG_ 1288 Reserved54 1000;
BA_ "GenSigTimeoutMsg_IVI" SG_ 1288 Reserved54 1000;
BA_ "GenSigTimeoutTime_IVI" SG_ 1288 Reserved54 1000;
BA_ "GenSigTimeoutTime_HU_Mid_X451" SG_ 1288 Reserved53 1000;
BA_ "GenSigTimeoutTime_HU_High_X451" SG_ 1288 Reserved53 1000;
BA_ "GenSigTimeoutTime_HU_B" SG_ 1288 Reserved53 1000;
BA_ "GenSigTimeoutTime_HU_A" SG_ 1288 Reserved53 1000;
BA_ "GenSigTimeoutMsg_HU_Mid_X451" SG_ 1288 Reserved53 1000;
BA_ "GenSigTimeoutMsg_HU_High_X451" SG_ 1288 Reserved53 1000;
BA_ "GenSigTimeoutMsg_HU_B" SG_ 1288 Reserved53 1000;
BA_ "GenSigTimeoutMsg_HU_A" SG_ 1288 Reserved53 1000;
BA_ "GenSigSendType" SG_ 1288 Reserved53 7;
BA_ "GenSigCycleTimeActive" SG_ 1288 Reserved53 200;
BA_ "GenSigCycleTime" SG_ 1288 Reserved53 200;
BA_ "GenSigTimeoutMsg_HU_High_X445" SG_ 1288 Reserved53 1000;
BA_ "GenSigTimeoutMsg_HU_Mid_X445" SG_ 1288 Reserved53 1000;
BA_ "GenSigTimeoutTime_HU_High_X445" SG_ 1288 Reserved53 1000;
BA_ "GenSigTimeoutTime_HU_Mid_X445" SG_ 1288 Reserved53 1000;
BA_ "GenSigTimeoutMsg_IVI" SG_ 1288 Reserved53 1000;
BA_ "GenSigTimeoutTime_IVI" SG_ 1288 Reserved53 1000;
BA_ "GenSigTimeoutTime_HU_Mid_X451" SG_ 1288 Reserved52 1000;
BA_ "GenSigTimeoutTime_HU_High_X451" SG_ 1288 Reserved52 1000;
BA_ "GenSigTimeoutTime_HU_B" SG_ 1288 Reserved52 1000;
BA_ "GenSigTimeoutTime_HU_A" SG_ 1288 Reserved52 1000;
BA_ "GenSigTimeoutMsg_HU_Mid_X451" SG_ 1288 Reserved52 1000;
BA_ "GenSigTimeoutMsg_HU_High_X451" SG_ 1288 Reserved52 1000;
BA_ "GenSigTimeoutMsg_HU_B" SG_ 1288 Reserved52 1000;
BA_ "GenSigTimeoutMsg_HU_A" SG_ 1288 Reserved52 1000;
BA_ "GenSigSendType" SG_ 1288 Reserved52 7;
BA_ "GenSigCycleTimeActive" SG_ 1288 Reserved52 200;
BA_ "GenSigCycleTime" SG_ 1288 Reserved52 200;
BA_ "GenSigTimeoutMsg_HU_High_X445" SG_ 1288 Reserved52 1000;
BA_ "GenSigTimeoutMsg_HU_Mid_X445" SG_ 1288 Reserved52 1000;
BA_ "GenSigTimeoutTime_HU_High_X445" SG_ 1288 Reserved52 1000;
BA_ "GenSigTimeoutTime_HU_Mid_X445" SG_ 1288 Reserved52 1000;
BA_ "GenSigTimeoutMsg_IVI" SG_ 1288 Reserved52 1000;
BA_ "GenSigTimeoutTime_IVI" SG_ 1288 Reserved52 1000;
BA_ "GenSigTimeoutTime_HU_Mid_X451" SG_ 1288 Reserved51 1000;
BA_ "GenSigTimeoutTime_HU_High_X451" SG_ 1288 Reserved51 1000;
BA_ "GenSigTimeoutTime_HU_B" SG_ 1288 Reserved51 1000;
BA_ "GenSigTimeoutTime_HU_A" SG_ 1288 Reserved51 1000;
BA_ "GenSigTimeoutMsg_HU_Mid_X451" SG_ 1288 Reserved51 1000;
BA_ "GenSigTimeoutMsg_HU_High_X451" SG_ 1288 Reserved51 1000;
BA_ "GenSigTimeoutMsg_HU_B" SG_ 1288 Reserved51 1000;
BA_ "GenSigTimeoutMsg_HU_A" SG_ 1288 Reserved51 1000;
BA_ "GenSigSendType" SG_ 1288 Reserved51 7;
BA_ "GenSigCycleTimeActive" SG_ 1288 Reserved51 200;
BA_ "GenSigCycleTime" SG_ 1288 Reserved51 200;
BA_ "GenSigTimeoutMsg_HU_High_X445" SG_ 1288 Reserved51 1000;
BA_ "GenSigTimeoutMsg_HU_Mid_X445" SG_ 1288 Reserved51 1000;
BA_ "GenSigTimeoutTime_HU_High_X445" SG_ 1288 Reserved51 1000;
BA_ "GenSigTimeoutTime_HU_Mid_X445" SG_ 1288 Reserved51 1000;
BA_ "GenSigTimeoutMsg_IVI" SG_ 1288 Reserved51 1000;
BA_ "GenSigTimeoutTime_IVI" SG_ 1288 Reserved51 1000;
BA_ "GenSigTimeoutTime_HU_Mid_X451" SG_ 1288 Reserved50 1000;
BA_ "GenSigTimeoutTime_HU_High_X451" SG_ 1288 Reserved50 1000;
BA_ "GenSigTimeoutTime_HU_B" SG_ 1288 Reserved50 1000;
BA_ "GenSigTimeoutTime_HU_A" SG_ 1288 Reserved50 1000;
BA_ "GenSigTimeoutMsg_HU_Mid_X451" SG_ 1288 Reserved50 1000;
BA_ "GenSigTimeoutMsg_HU_High_X451" SG_ 1288 Reserved50 1000;
BA_ "GenSigTimeoutMsg_HU_B" SG_ 1288 Reserved50 1000;
BA_ "GenSigTimeoutMsg_HU_A" SG_ 1288 Reserved50 1000;
BA_ "GenSigSendType" SG_ 1288 Reserved50 7;
BA_ "GenSigCycleTimeActive" SG_ 1288 Reserved50 200;
BA_ "GenSigCycleTime" SG_ 1288 Reserved50 200;
BA_ "GenSigTimeoutMsg_HU_High_X445" SG_ 1288 Reserved50 1000;
BA_ "GenSigTimeoutMsg_HU_Mid_X445" SG_ 1288 Reserved50 1000;
BA_ "GenSigTimeoutTime_HU_High_X445" SG_ 1288 Reserved50 1000;
BA_ "GenSigTimeoutTime_HU_Mid_X445" SG_ 1288 Reserved50 1000;
BA_ "GenSigTimeoutMsg_IVI" SG_ 1288 Reserved50 1000;
BA_ "GenSigTimeoutTime_IVI" SG_ 1288 Reserved50 1000;
BA_ "GenSigTimeoutTime_HU_Mid_X451" SG_ 1288 Reserved49 1000;
BA_ "GenSigTimeoutTime_HU_High_X451" SG_ 1288 Reserved49 1000;
BA_ "GenSigTimeoutTime_HU_B" SG_ 1288 Reserved49 1000;
BA_ "GenSigTimeoutTime_HU_A" SG_ 1288 Reserved49 1000;
BA_ "GenSigTimeoutMsg_HU_Mid_X451" SG_ 1288 Reserved49 1000;
BA_ "GenSigTimeoutMsg_HU_High_X451" SG_ 1288 Reserved49 1000;
BA_ "GenSigTimeoutMsg_HU_B" SG_ 1288 Reserved49 1000;
BA_ "GenSigTimeoutMsg_HU_A" SG_ 1288 Reserved49 1000;
BA_ "GenSigSendType" SG_ 1288 Reserved49 7;
BA_ "GenSigCycleTimeActive" SG_ 1288 Reserved49 200;
BA_ "GenSigCycleTime" SG_ 1288 Reserved49 200;
BA_ "GenSigTimeoutMsg_HU_High_X445" SG_ 1288 Reserved49 1000;
BA_ "GenSigTimeoutMsg_HU_Mid_X445" SG_ 1288 Reserved49 1000;
BA_ "GenSigTimeoutTime_HU_High_X445" SG_ 1288 Reserved49 1000;
BA_ "GenSigTimeoutTime_HU_Mid_X445" SG_ 1288 Reserved49 1000;
BA_ "GenSigTimeoutMsg_IVI" SG_ 1288 Reserved49 1000;
BA_ "GenSigTimeoutTime_IVI" SG_ 1288 Reserved49 1000;
BA_ "GenSigTimeoutTime_HU_Mid_X451" SG_ 1288 Reserved48 1000;
BA_ "GenSigTimeoutTime_HU_High_X451" SG_ 1288 Reserved48 1000;
BA_ "GenSigTimeoutTime_HU_B" SG_ 1288 Reserved48 1000;
BA_ "GenSigTimeoutTime_HU_A" SG_ 1288 Reserved48 1000;
BA_ "GenSigTimeoutMsg_HU_Mid_X451" SG_ 1288 Reserved48 1000;
BA_ "GenSigTimeoutMsg_HU_High_X451" SG_ 1288 Reserved48 1000;
BA_ "GenSigTimeoutMsg_HU_B" SG_ 1288 Reserved48 1000;
BA_ "GenSigTimeoutMsg_HU_A" SG_ 1288 Reserved48 1000;
BA_ "GenSigSendType" SG_ 1288 Reserved48 7;
BA_ "GenSigCycleTimeActive" SG_ 1288 Reserved48 200;
BA_ "GenSigCycleTime" SG_ 1288 Reserved48 200;
BA_ "GenSigTimeoutMsg_HU_High_X445" SG_ 1288 Reserved48 1000;
BA_ "GenSigTimeoutMsg_HU_Mid_X445" SG_ 1288 Reserved48 1000;
BA_ "GenSigTimeoutTime_HU_High_X445" SG_ 1288 Reserved48 1000;
BA_ "GenSigTimeoutTime_HU_Mid_X445" SG_ 1288 Reserved48 1000;
BA_ "GenSigTimeoutMsg_IVI" SG_ 1288 Reserved48 1000;
BA_ "GenSigTimeoutTime_IVI" SG_ 1288 Reserved48 1000;
BA_ "GenSigTimeoutTime_HU_Mid_X451" SG_ 1288 RepeatMessageReq_TM 1000;
BA_ "GenSigTimeoutTime_HU_High_X451" SG_ 1288 RepeatMessageReq_TM 1000;
BA_ "GenSigTimeoutTime_HU_B" SG_ 1288 RepeatMessageReq_TM 1000;
BA_ "GenSigTimeoutTime_HU_A" SG_ 1288 RepeatMessageReq_TM 1000;
BA_ "GenSigTimeoutMsg_HU_Mid_X451" SG_ 1288 RepeatMessageReq_TM 1000;
BA_ "GenSigTimeoutMsg_HU_High_X451" SG_ 1288 RepeatMessageReq_TM 1000;
BA_ "GenSigTimeoutMsg_HU_B" SG_ 1288 RepeatMessageReq_TM 1000;
BA_ "GenSigTimeoutMsg_HU_A" SG_ 1288 RepeatMessageReq_TM 1000;
BA_ "GenSigSendType" SG_ 1288 RepeatMessageReq_TM 7;
BA_ "GenSigCycleTimeActive" SG_ 1288 RepeatMessageReq_TM 200;
BA_ "GenSigCycleTime" SG_ 1288 RepeatMessageReq_TM 200;
BA_ "GenSigTimeoutMsg_HU_High_X445" SG_ 1288 RepeatMessageReq_TM 1000;
BA_ "GenSigTimeoutMsg_HU_Mid_X445" SG_ 1288 RepeatMessageReq_TM 1000;
BA_ "GenSigTimeoutTime_HU_High_X445" SG_ 1288 RepeatMessageReq_TM 1000;
BA_ "GenSigTimeoutTime_HU_Mid_X445" SG_ 1288 RepeatMessageReq_TM 1000;
BA_ "GenSigTimeoutMsg_IVI" SG_ 1288 RepeatMessageReq_TM 1000;
BA_ "GenSigTimeoutTime_IVI" SG_ 1288 RepeatMessageReq_TM 1000;
BA_ "GenSigTimeoutTime_HU_Mid_X451" SG_ 1288 PreviousState_TM 1000;
BA_ "GenSigTimeoutTime_HU_High_X451" SG_ 1288 PreviousState_TM 1000;
BA_ "GenSigTimeoutTime_HU_B" SG_ 1288 PreviousState_TM 1000;
BA_ "GenSigTimeoutTime_HU_A" SG_ 1288 PreviousState_TM 1000;
BA_ "GenSigTimeoutMsg_HU_Mid_X451" SG_ 1288 PreviousState_TM 1000;
BA_ "GenSigTimeoutMsg_HU_High_X451" SG_ 1288 PreviousState_TM 1000;
BA_ "GenSigTimeoutMsg_HU_B" SG_ 1288 PreviousState_TM 1000;
BA_ "GenSigTimeoutMsg_HU_A" SG_ 1288 PreviousState_TM 1000;
BA_ "GenSigSendType" SG_ 1288 PreviousState_TM 7;
BA_ "GenSigCycleTimeActive" SG_ 1288 PreviousState_TM 200;
BA_ "GenSigCycleTime" SG_ 1288 PreviousState_TM 200;
BA_ "GenSigTimeoutMsg_HU_High_X445" SG_ 1288 PreviousState_TM 1000;
BA_ "GenSigTimeoutMsg_HU_Mid_X445" SG_ 1288 PreviousState_TM 1000;
BA_ "GenSigTimeoutTime_HU_High_X445" SG_ 1288 PreviousState_TM 1000;
BA_ "GenSigTimeoutTime_HU_Mid_X445" SG_ 1288 PreviousState_TM 1000;
BA_ "GenSigTimeoutMsg_IVI" SG_ 1288 PreviousState_TM 1000;
BA_ "GenSigTimeoutTime_IVI" SG_ 1288 PreviousState_TM 1000;
BA_ "GenSigTimeoutTime_HU_Mid_X451" SG_ 1288 NMCoOrdSlpReady_TM 1000;
BA_ "GenSigTimeoutTime_HU_High_X451" SG_ 1288 NMCoOrdSlpReady_TM 1000;
BA_ "GenSigTimeoutTime_HU_B" SG_ 1288 NMCoOrdSlpReady_TM 1000;
BA_ "GenSigTimeoutTime_HU_A" SG_ 1288 NMCoOrdSlpReady_TM 1000;
BA_ "GenSigTimeoutMsg_HU_Mid_X451" SG_ 1288 NMCoOrdSlpReady_TM 1000;
BA_ "GenSigTimeoutMsg_HU_High_X451" SG_ 1288 NMCoOrdSlpReady_TM 1000;
BA_ "GenSigTimeoutMsg_HU_B" SG_ 1288 NMCoOrdSlpReady_TM 1000;
BA_ "GenSigTimeoutMsg_HU_A" SG_ 1288 NMCoOrdSlpReady_TM 1000;
BA_ "GenSigSendType" SG_ 1288 NMCoOrdSlpReady_TM 7;
BA_ "GenSigCycleTimeActive" SG_ 1288 NMCoOrdSlpReady_TM 200;
BA_ "GenSigCycleTime" SG_ 1288 NMCoOrdSlpReady_TM 200;
BA_ "GenSigTimeoutMsg_HU_High_X445" SG_ 1288 NMCoOrdSlpReady_TM 1000;
BA_ "GenSigTimeoutMsg_HU_Mid_X445" SG_ 1288 NMCoOrdSlpReady_TM 1000;
BA_ "GenSigTimeoutTime_HU_High_X445" SG_ 1288 NMCoOrdSlpReady_TM 1000;
BA_ "GenSigTimeoutTime_HU_Mid_X445" SG_ 1288 NMCoOrdSlpReady_TM 1000;
BA_ "GenSigTimeoutMsg_IVI" SG_ 1288 NMCoOrdSlpReady_TM 1000;
BA_ "GenSigTimeoutTime_IVI" SG_ 1288 NMCoOrdSlpReady_TM 1000;
BA_ "GenSigTimeoutTime_HU_Mid_X451" SG_ 1288 CurrentState_TM 1000;
BA_ "GenSigTimeoutTime_HU_High_X451" SG_ 1288 CurrentState_TM 1000;
BA_ "GenSigTimeoutTime_HU_B" SG_ 1288 CurrentState_TM 1000;
BA_ "GenSigTimeoutTime_HU_A" SG_ 1288 CurrentState_TM 1000;
BA_ "GenSigTimeoutMsg_HU_Mid_X451" SG_ 1288 CurrentState_TM 1000;
BA_ "GenSigTimeoutMsg_HU_High_X451" SG_ 1288 CurrentState_TM 1000;
BA_ "GenSigTimeoutMsg_HU_B" SG_ 1288 CurrentState_TM 1000;
BA_ "GenSigTimeoutMsg_HU_A" SG_ 1288 CurrentState_TM 1000;
BA_ "GenSigSendType" SG_ 1288 CurrentState_TM 7;
BA_ "GenSigCycleTimeActive" SG_ 1288 CurrentState_TM 200;
BA_ "GenSigCycleTime" SG_ 1288 CurrentState_TM 200;
BA_ "GenSigTimeoutMsg_HU_High_X445" SG_ 1288 CurrentState_TM 1000;
BA_ "GenSigTimeoutMsg_HU_Mid_X445" SG_ 1288 CurrentState_TM 1000;
BA_ "GenSigTimeoutTime_HU_High_X445" SG_ 1288 CurrentState_TM 1000;
BA_ "GenSigTimeoutTime_HU_Mid_X445" SG_ 1288 CurrentState_TM 1000;
BA_ "GenSigTimeoutMsg_IVI" SG_ 1288 CurrentState_TM 1000;
BA_ "GenSigTimeoutTime_IVI" SG_ 1288 CurrentState_TM 1000;
BA_ "GenSigTimeoutTime_HU_Mid_X451" SG_ 1288 TM_NMPDU_USER_DATA_D5 1000;
BA_ "GenSigTimeoutTime_HU_High_X451" SG_ 1288 TM_NMPDU_USER_DATA_D5 1000;
BA_ "GenSigTimeoutTime_HU_B" SG_ 1288 TM_NMPDU_USER_DATA_D5 1000;
BA_ "GenSigTimeoutTime_HU_A" SG_ 1288 TM_NMPDU_USER_DATA_D5 1000;
BA_ "GenSigTimeoutMsg_HU_Mid_X451" SG_ 1288 TM_NMPDU_USER_DATA_D5 1000;
BA_ "GenSigTimeoutMsg_HU_High_X451" SG_ 1288 TM_NMPDU_USER_DATA_D5 1000;
BA_ "GenSigTimeoutMsg_HU_B" SG_ 1288 TM_NMPDU_USER_DATA_D5 1000;
BA_ "GenSigTimeoutMsg_HU_A" SG_ 1288 TM_NMPDU_USER_DATA_D5 1000;
BA_ "GenSigSendType" SG_ 1288 TM_NMPDU_USER_DATA_D5 7;
BA_ "GenSigCycleTimeActive" SG_ 1288 TM_NMPDU_USER_DATA_D5 200;
BA_ "GenSigCycleTime" SG_ 1288 TM_NMPDU_USER_DATA_D5 200;
BA_ "GenSigTimeoutMsg_HU_High_X445" SG_ 1288 TM_NMPDU_USER_DATA_D5 1000;
BA_ "GenSigTimeoutMsg_HU_Mid_X445" SG_ 1288 TM_NMPDU_USER_DATA_D5 1000;
BA_ "GenSigTimeoutTime_HU_High_X445" SG_ 1288 TM_NMPDU_USER_DATA_D5 1000;
BA_ "GenSigTimeoutTime_HU_Mid_X445" SG_ 1288 TM_NMPDU_USER_DATA_D5 1000;
BA_ "GenSigTimeoutMsg_IVI" SG_ 1288 TM_NMPDU_USER_DATA_D5 1000;
BA_ "GenSigTimeoutTime_IVI" SG_ 1288 TM_NMPDU_USER_DATA_D5 1000;
BA_ "GenSigTimeoutTime_HU_Mid_X451" SG_ 1288 TM_NMPDU_USER_DATA_D4 1000;
BA_ "GenSigTimeoutTime_HU_High_X451" SG_ 1288 TM_NMPDU_USER_DATA_D4 1000;
BA_ "GenSigTimeoutTime_HU_B" SG_ 1288 TM_NMPDU_USER_DATA_D4 1000;
BA_ "GenSigTimeoutTime_HU_A" SG_ 1288 TM_NMPDU_USER_DATA_D4 1000;
BA_ "GenSigTimeoutMsg_HU_Mid_X451" SG_ 1288 TM_NMPDU_USER_DATA_D4 1000;
BA_ "GenSigTimeoutMsg_HU_High_X451" SG_ 1288 TM_NMPDU_USER_DATA_D4 1000;
BA_ "GenSigTimeoutMsg_HU_B" SG_ 1288 TM_NMPDU_USER_DATA_D4 1000;
BA_ "GenSigTimeoutMsg_HU_A" SG_ 1288 TM_NMPDU_USER_DATA_D4 1000;
BA_ "GenSigSendType" SG_ 1288 TM_NMPDU_USER_DATA_D4 7;
BA_ "GenSigCycleTimeActive" SG_ 1288 TM_NMPDU_USER_DATA_D4 200;
BA_ "GenSigCycleTime" SG_ 1288 TM_NMPDU_USER_DATA_D4 200;
BA_ "GenSigTimeoutMsg_HU_High_X445" SG_ 1288 TM_NMPDU_USER_DATA_D4 1000;
BA_ "GenSigTimeoutMsg_HU_Mid_X445" SG_ 1288 TM_NMPDU_USER_DATA_D4 1000;
BA_ "GenSigTimeoutTime_HU_High_X445" SG_ 1288 TM_NMPDU_USER_DATA_D4 1000;
BA_ "GenSigTimeoutTime_HU_Mid_X445" SG_ 1288 TM_NMPDU_USER_DATA_D4 1000;
BA_ "GenSigTimeoutMsg_IVI" SG_ 1288 TM_NMPDU_USER_DATA_D4 1000;
BA_ "GenSigTimeoutTime_IVI" SG_ 1288 TM_NMPDU_USER_DATA_D4 1000;
BA_ "GenSigTimeoutTime_HU_Mid_X451" SG_ 1288 TM_NMPDU_USER_DATA_D3 1000;
BA_ "GenSigTimeoutTime_HU_High_X451" SG_ 1288 TM_NMPDU_USER_DATA_D3 1000;
BA_ "GenSigTimeoutTime_HU_B" SG_ 1288 TM_NMPDU_USER_DATA_D3 1000;
BA_ "GenSigTimeoutTime_HU_A" SG_ 1288 TM_NMPDU_USER_DATA_D3 1000;
BA_ "GenSigTimeoutMsg_HU_Mid_X451" SG_ 1288 TM_NMPDU_USER_DATA_D3 1000;
BA_ "GenSigTimeoutMsg_HU_High_X451" SG_ 1288 TM_NMPDU_USER_DATA_D3 1000;
BA_ "GenSigTimeoutMsg_HU_B" SG_ 1288 TM_NMPDU_USER_DATA_D3 1000;
BA_ "GenSigTimeoutMsg_HU_A" SG_ 1288 TM_NMPDU_USER_DATA_D3 1000;
BA_ "GenSigSendType" SG_ 1288 TM_NMPDU_USER_DATA_D3 7;
BA_ "GenSigCycleTimeActive" SG_ 1288 TM_NMPDU_USER_DATA_D3 200;
BA_ "GenSigCycleTime" SG_ 1288 TM_NMPDU_USER_DATA_D3 200;
BA_ "GenSigTimeoutMsg_HU_High_X445" SG_ 1288 TM_NMPDU_USER_DATA_D3 1000;
BA_ "GenSigTimeoutMsg_HU_Mid_X445" SG_ 1288 TM_NMPDU_USER_DATA_D3 1000;
BA_ "GenSigTimeoutTime_HU_High_X445" SG_ 1288 TM_NMPDU_USER_DATA_D3 1000;
BA_ "GenSigTimeoutTime_HU_Mid_X445" SG_ 1288 TM_NMPDU_USER_DATA_D3 1000;
BA_ "GenSigTimeoutMsg_IVI" SG_ 1288 TM_NMPDU_USER_DATA_D3 1000;
BA_ "GenSigTimeoutTime_IVI" SG_ 1288 TM_NMPDU_USER_DATA_D3 1000;
BA_ "GenSigTimeoutTime_HU_Mid_X451" SG_ 1288 TM_NMPDU_USER_DATA_D2 1000;
BA_ "GenSigTimeoutTime_HU_High_X451" SG_ 1288 TM_NMPDU_USER_DATA_D2 1000;
BA_ "GenSigTimeoutTime_HU_B" SG_ 1288 TM_NMPDU_USER_DATA_D2 1000;
BA_ "GenSigTimeoutTime_HU_A" SG_ 1288 TM_NMPDU_USER_DATA_D2 1000;
BA_ "GenSigTimeoutMsg_HU_Mid_X451" SG_ 1288 TM_NMPDU_USER_DATA_D2 1000;
BA_ "GenSigTimeoutMsg_HU_High_X451" SG_ 1288 TM_NMPDU_USER_DATA_D2 1000;
BA_ "GenSigTimeoutMsg_HU_B" SG_ 1288 TM_NMPDU_USER_DATA_D2 1000;
BA_ "GenSigTimeoutMsg_HU_A" SG_ 1288 TM_NMPDU_USER_DATA_D2 1000;
BA_ "GenSigSendType" SG_ 1288 TM_NMPDU_USER_DATA_D2 7;
BA_ "GenSigCycleTimeActive" SG_ 1288 TM_NMPDU_USER_DATA_D2 200;
BA_ "GenSigCycleTime" SG_ 1288 TM_NMPDU_USER_DATA_D2 200;
BA_ "GenSigTimeoutMsg_HU_High_X445" SG_ 1288 TM_NMPDU_USER_DATA_D2 1000;
BA_ "GenSigTimeoutMsg_HU_Mid_X445" SG_ 1288 TM_NMPDU_USER_DATA_D2 1000;
BA_ "GenSigTimeoutTime_HU_High_X445" SG_ 1288 TM_NMPDU_USER_DATA_D2 1000;
BA_ "GenSigTimeoutTime_HU_Mid_X445" SG_ 1288 TM_NMPDU_USER_DATA_D2 1000;
BA_ "GenSigTimeoutMsg_IVI" SG_ 1288 TM_NMPDU_USER_DATA_D2 1000;
BA_ "GenSigTimeoutTime_IVI" SG_ 1288 TM_NMPDU_USER_DATA_D2 1000;
BA_ "GenSigTimeoutTime_HU_Mid_X451" SG_ 1288 TM_NMPDU_USER_DATA_D1 1000;
BA_ "GenSigTimeoutTime_HU_High_X451" SG_ 1288 TM_NMPDU_USER_DATA_D1 1000;
BA_ "GenSigTimeoutTime_HU_B" SG_ 1288 TM_NMPDU_USER_DATA_D1 1000;
BA_ "GenSigTimeoutTime_HU_A" SG_ 1288 TM_NMPDU_USER_DATA_D1 1000;
BA_ "GenSigTimeoutMsg_HU_Mid_X451" SG_ 1288 TM_NMPDU_USER_DATA_D1 1000;
BA_ "GenSigTimeoutMsg_HU_High_X451" SG_ 1288 TM_NMPDU_USER_DATA_D1 1000;
BA_ "GenSigTimeoutMsg_HU_B" SG_ 1288 TM_NMPDU_USER_DATA_D1 1000;
BA_ "GenSigTimeoutMsg_HU_A" SG_ 1288 TM_NMPDU_USER_DATA_D1 1000;
BA_ "GenSigSendType" SG_ 1288 TM_NMPDU_USER_DATA_D1 7;
BA_ "GenSigCycleTimeActive" SG_ 1288 TM_NMPDU_USER_DATA_D1 200;
BA_ "GenSigCycleTime" SG_ 1288 TM_NMPDU_USER_DATA_D1 200;
BA_ "GenSigTimeoutMsg_HU_High_X445" SG_ 1288 TM_NMPDU_USER_DATA_D1 1000;
BA_ "GenSigTimeoutMsg_HU_Mid_X445" SG_ 1288 TM_NMPDU_USER_DATA_D1 1000;
BA_ "GenSigTimeoutTime_HU_High_X445" SG_ 1288 TM_NMPDU_USER_DATA_D1 1000;
BA_ "GenSigTimeoutTime_HU_Mid_X445" SG_ 1288 TM_NMPDU_USER_DATA_D1 1000;
BA_ "GenSigTimeoutMsg_IVI" SG_ 1288 TM_NMPDU_USER_DATA_D1 1000;
BA_ "GenSigTimeoutTime_IVI" SG_ 1288 TM_NMPDU_USER_DATA_D1 1000;
BA_ "GenSigTimeoutTime_HU_Mid_X451" SG_ 1288 TM_NMPDU_SRC_ECU_ID 1000;
BA_ "GenSigTimeoutTime_HU_High_X451" SG_ 1288 TM_NMPDU_SRC_ECU_ID 1000;
BA_ "GenSigTimeoutTime_HU_B" SG_ 1288 TM_NMPDU_SRC_ECU_ID 1000;
BA_ "GenSigTimeoutTime_HU_A" SG_ 1288 TM_NMPDU_SRC_ECU_ID 1000;
BA_ "GenSigTimeoutMsg_HU_Mid_X451" SG_ 1288 TM_NMPDU_SRC_ECU_ID 1000;
BA_ "GenSigTimeoutMsg_HU_High_X451" SG_ 1288 TM_NMPDU_SRC_ECU_ID 1000;
BA_ "GenSigTimeoutMsg_HU_B" SG_ 1288 TM_NMPDU_SRC_ECU_ID 1000;
BA_ "GenSigTimeoutMsg_HU_A" SG_ 1288 TM_NMPDU_SRC_ECU_ID 1000;
BA_ "GenSigSendType" SG_ 1288 TM_NMPDU_SRC_ECU_ID 7;
BA_ "GenSigCycleTimeActive" SG_ 1288 TM_NMPDU_SRC_ECU_ID 200;
BA_ "GenSigCycleTime" SG_ 1288 TM_NMPDU_SRC_ECU_ID 200;
BA_ "GenSigTimeoutMsg_HU_High_X445" SG_ 1288 TM_NMPDU_SRC_ECU_ID 1000;
BA_ "GenSigTimeoutMsg_HU_Mid_X445" SG_ 1288 TM_NMPDU_SRC_ECU_ID 1000;
BA_ "GenSigTimeoutTime_HU_High_X445" SG_ 1288 TM_NMPDU_SRC_ECU_ID 1000;
BA_ "GenSigTimeoutTime_HU_Mid_X445" SG_ 1288 TM_NMPDU_SRC_ECU_ID 1000;
BA_ "GenSigTimeoutMsg_IVI" SG_ 1288 TM_NMPDU_SRC_ECU_ID 1000;
BA_ "GenSigTimeoutTime_IVI" SG_ 1288 TM_NMPDU_SRC_ECU_ID 1000;
BA_ "GenSigTimeoutTime_HU_Mid_X451" SG_ 1288 ActiveWakeUp_TM 1000;
BA_ "GenSigTimeoutTime_HU_High_X451" SG_ 1288 ActiveWakeUp_TM 1000;
BA_ "GenSigTimeoutTime_HU_B" SG_ 1288 ActiveWakeUp_TM 1000;
BA_ "GenSigTimeoutTime_HU_A" SG_ 1288 ActiveWakeUp_TM 1000;
BA_ "GenSigTimeoutMsg_HU_Mid_X451" SG_ 1288 ActiveWakeUp_TM 1000;
BA_ "GenSigTimeoutMsg_HU_High_X451" SG_ 1288 ActiveWakeUp_TM 1000;
BA_ "GenSigTimeoutMsg_HU_B" SG_ 1288 ActiveWakeUp_TM 1000;
BA_ "GenSigTimeoutMsg_HU_A" SG_ 1288 ActiveWakeUp_TM 1000;
BA_ "GenSigSendType" SG_ 1288 ActiveWakeUp_TM 7;
BA_ "GenSigCycleTimeActive" SG_ 1288 ActiveWakeUp_TM 200;
BA_ "GenSigCycleTime" SG_ 1288 ActiveWakeUp_TM 200;
BA_ "GenSigTimeoutMsg_HU_High_X445" SG_ 1288 ActiveWakeUp_TM 1000;
BA_ "GenSigTimeoutMsg_HU_Mid_X445" SG_ 1288 ActiveWakeUp_TM 1000;
BA_ "GenSigTimeoutTime_HU_High_X445" SG_ 1288 ActiveWakeUp_TM 1000;
BA_ "GenSigTimeoutTime_HU_Mid_X445" SG_ 1288 ActiveWakeUp_TM 1000;
BA_ "GenSigTimeoutMsg_IVI" SG_ 1288 ActiveWakeUp_TM 1000;
BA_ "GenSigTimeoutTime_IVI" SG_ 1288 ActiveWakeUp_TM 1000;
BA_ "GenSigTimeoutTime_HU_Mid_X451" SG_ 1287 PartialNetworkInformation_VCU 0;
BA_ "GenSigTimeoutTime_HU_High_X451" SG_ 1287 PartialNetworkInformation_VCU 0;
BA_ "GenSigTimeoutTime_HU_B" SG_ 1287 PartialNetworkInformation_VCU 0;
BA_ "GenSigTimeoutTime_HU_A" SG_ 1287 PartialNetworkInformation_VCU 0;
BA_ "GenSigTimeoutMsg_HU_Mid_X451" SG_ 1287 PartialNetworkInformation_VCU 0;
BA_ "GenSigTimeoutMsg_HU_High_X451" SG_ 1287 PartialNetworkInformation_VCU 0;
BA_ "GenSigTimeoutMsg_HU_B" SG_ 1287 PartialNetworkInformation_VCU 0;
BA_ "GenSigTimeoutMsg_HU_A" SG_ 1287 PartialNetworkInformation_VCU 0;
BA_ "GenSigSendType" SG_ 1287 PartialNetworkInformation_VCU 7;
BA_ "GenSigCycleTimeActive" SG_ 1287 PartialNetworkInformation_VCU 200;
BA_ "GenSigCycleTime" SG_ 1287 PartialNetworkInformation_VCU 200;
BA_ "GenSigTimeoutTime_HU_Mid_X451" SG_ 1287 VCU_NMPDU_USER_DATA_D3 0;
BA_ "GenSigTimeoutTime_HU_High_X451" SG_ 1287 VCU_NMPDU_USER_DATA_D3 0;
BA_ "GenSigTimeoutTime_HU_B" SG_ 1287 VCU_NMPDU_USER_DATA_D3 0;
BA_ "GenSigTimeoutTime_HU_A" SG_ 1287 VCU_NMPDU_USER_DATA_D3 0;
BA_ "GenSigTimeoutMsg_HU_Mid_X451" SG_ 1287 VCU_NMPDU_USER_DATA_D3 0;
BA_ "GenSigTimeoutMsg_HU_High_X451" SG_ 1287 VCU_NMPDU_USER_DATA_D3 0;
BA_ "GenSigTimeoutMsg_HU_B" SG_ 1287 VCU_NMPDU_USER_DATA_D3 0;
BA_ "GenSigTimeoutMsg_HU_A" SG_ 1287 VCU_NMPDU_USER_DATA_D3 0;
BA_ "GenSigSendType" SG_ 1287 VCU_NMPDU_USER_DATA_D3 7;
BA_ "GenSigCycleTimeActive" SG_ 1287 VCU_NMPDU_USER_DATA_D3 200;
BA_ "GenSigCycleTime" SG_ 1287 VCU_NMPDU_USER_DATA_D3 200;
BA_ "GenSigTimeoutTime_HU_Mid_X451" SG_ 1287 Reserved47 0;
BA_ "GenSigTimeoutTime_HU_High_X451" SG_ 1287 Reserved47 0;
BA_ "GenSigTimeoutTime_HU_B" SG_ 1287 Reserved47 0;
BA_ "GenSigTimeoutTime_HU_A" SG_ 1287 Reserved47 0;
BA_ "GenSigTimeoutMsg_HU_Mid_X451" SG_ 1287 Reserved47 0;
BA_ "GenSigTimeoutMsg_HU_High_X451" SG_ 1287 Reserved47 0;
BA_ "GenSigTimeoutMsg_HU_B" SG_ 1287 Reserved47 0;
BA_ "GenSigTimeoutMsg_HU_A" SG_ 1287 Reserved47 0;
BA_ "GenSigSendType" SG_ 1287 Reserved47 7;
BA_ "GenSigCycleTimeActive" SG_ 1287 Reserved47 200;
BA_ "GenSigCycleTime" SG_ 1287 Reserved47 200;
BA_ "GenSigTimeoutTime_HU_Mid_X451" SG_ 1287 Reserved46 0;
BA_ "GenSigTimeoutTime_HU_High_X451" SG_ 1287 Reserved46 0;
BA_ "GenSigTimeoutTime_HU_B" SG_ 1287 Reserved46 0;
BA_ "GenSigTimeoutTime_HU_A" SG_ 1287 Reserved46 0;
BA_ "GenSigTimeoutMsg_HU_Mid_X451" SG_ 1287 Reserved46 0;
BA_ "GenSigTimeoutMsg_HU_High_X451" SG_ 1287 Reserved46 0;
BA_ "GenSigTimeoutMsg_HU_B" SG_ 1287 Reserved46 0;
BA_ "GenSigTimeoutMsg_HU_A" SG_ 1287 Reserved46 0;
BA_ "GenSigSendType" SG_ 1287 Reserved46 7;
BA_ "GenSigCycleTimeActive" SG_ 1287 Reserved46 200;
BA_ "GenSigCycleTime" SG_ 1287 Reserved46 200;
BA_ "GenSigTimeoutTime_HU_Mid_X451" SG_ 1287 Reserved45 0;
BA_ "GenSigTimeoutTime_HU_High_X451" SG_ 1287 Reserved45 0;
BA_ "GenSigTimeoutTime_HU_B" SG_ 1287 Reserved45 0;
BA_ "GenSigTimeoutTime_HU_A" SG_ 1287 Reserved45 0;
BA_ "GenSigTimeoutMsg_HU_Mid_X451" SG_ 1287 Reserved45 0;
BA_ "GenSigTimeoutMsg_HU_High_X451" SG_ 1287 Reserved45 0;
BA_ "GenSigTimeoutMsg_HU_B" SG_ 1287 Reserved45 0;
BA_ "GenSigTimeoutMsg_HU_A" SG_ 1287 Reserved45 0;
BA_ "GenSigSendType" SG_ 1287 Reserved45 7;
BA_ "GenSigCycleTimeActive" SG_ 1287 Reserved45 200;
BA_ "GenSigCycleTime" SG_ 1287 Reserved45 200;
BA_ "GenSigTimeoutTime_HU_Mid_X451" SG_ 1287 Reserved44 0;
BA_ "GenSigTimeoutTime_HU_High_X451" SG_ 1287 Reserved44 0;
BA_ "GenSigTimeoutTime_HU_B" SG_ 1287 Reserved44 0;
BA_ "GenSigTimeoutTime_HU_A" SG_ 1287 Reserved44 0;
BA_ "GenSigTimeoutMsg_HU_Mid_X451" SG_ 1287 Reserved44 0;
BA_ "GenSigTimeoutMsg_HU_High_X451" SG_ 1287 Reserved44 0;
BA_ "GenSigTimeoutMsg_HU_B" SG_ 1287 Reserved44 0;
BA_ "GenSigTimeoutMsg_HU_A" SG_ 1287 Reserved44 0;
BA_ "GenSigSendType" SG_ 1287 Reserved44 7;
BA_ "GenSigCycleTimeActive" SG_ 1287 Reserved44 200;
BA_ "GenSigCycleTime" SG_ 1287 Reserved44 200;
BA_ "GenSigTimeoutTime_HU_Mid_X451" SG_ 1287 Reserved43 0;
BA_ "GenSigTimeoutTime_HU_High_X451" SG_ 1287 Reserved43 0;
BA_ "GenSigTimeoutTime_HU_B" SG_ 1287 Reserved43 0;
BA_ "GenSigTimeoutTime_HU_A" SG_ 1287 Reserved43 0;
BA_ "GenSigTimeoutMsg_HU_Mid_X451" SG_ 1287 Reserved43 0;
BA_ "GenSigTimeoutMsg_HU_High_X451" SG_ 1287 Reserved43 0;
BA_ "GenSigTimeoutMsg_HU_B" SG_ 1287 Reserved43 0;
BA_ "GenSigTimeoutMsg_HU_A" SG_ 1287 Reserved43 0;
BA_ "GenSigSendType" SG_ 1287 Reserved43 7;
BA_ "GenSigCycleTimeActive" SG_ 1287 Reserved43 200;
BA_ "GenSigCycleTime" SG_ 1287 Reserved43 200;
BA_ "GenSigTimeoutTime_HU_Mid_X451" SG_ 1287 Reserved42 0;
BA_ "GenSigTimeoutTime_HU_High_X451" SG_ 1287 Reserved42 0;
BA_ "GenSigTimeoutTime_HU_B" SG_ 1287 Reserved42 0;
BA_ "GenSigTimeoutTime_HU_A" SG_ 1287 Reserved42 0;
BA_ "GenSigTimeoutMsg_HU_Mid_X451" SG_ 1287 Reserved42 0;
BA_ "GenSigTimeoutMsg_HU_High_X451" SG_ 1287 Reserved42 0;
BA_ "GenSigTimeoutMsg_HU_B" SG_ 1287 Reserved42 0;
BA_ "GenSigTimeoutMsg_HU_A" SG_ 1287 Reserved42 0;
BA_ "GenSigSendType" SG_ 1287 Reserved42 7;
BA_ "GenSigCycleTimeActive" SG_ 1287 Reserved42 200;
BA_ "GenSigCycleTime" SG_ 1287 Reserved42 200;
BA_ "GenSigTimeoutTime_HU_Mid_X451" SG_ 1287 Reserved41 0;
BA_ "GenSigTimeoutTime_HU_High_X451" SG_ 1287 Reserved41 0;
BA_ "GenSigTimeoutTime_HU_B" SG_ 1287 Reserved41 0;
BA_ "GenSigTimeoutTime_HU_A" SG_ 1287 Reserved41 0;
BA_ "GenSigTimeoutMsg_HU_Mid_X451" SG_ 1287 Reserved41 0;
BA_ "GenSigTimeoutMsg_HU_High_X451" SG_ 1287 Reserved41 0;
BA_ "GenSigTimeoutMsg_HU_B" SG_ 1287 Reserved41 0;
BA_ "GenSigTimeoutMsg_HU_A" SG_ 1287 Reserved41 0;
BA_ "GenSigSendType" SG_ 1287 Reserved41 7;
BA_ "GenSigCycleTimeActive" SG_ 1287 Reserved41 200;
BA_ "GenSigCycleTime" SG_ 1287 Reserved41 200;
BA_ "GenSigTimeoutTime_HU_Mid_X451" SG_ 1287 Reserved40 0;
BA_ "GenSigTimeoutTime_HU_High_X451" SG_ 1287 Reserved40 0;
BA_ "GenSigTimeoutTime_HU_B" SG_ 1287 Reserved40 0;
BA_ "GenSigTimeoutTime_HU_A" SG_ 1287 Reserved40 0;
BA_ "GenSigTimeoutMsg_HU_Mid_X451" SG_ 1287 Reserved40 0;
BA_ "GenSigTimeoutMsg_HU_High_X451" SG_ 1287 Reserved40 0;
BA_ "GenSigTimeoutMsg_HU_B" SG_ 1287 Reserved40 0;
BA_ "GenSigTimeoutMsg_HU_A" SG_ 1287 Reserved40 0;
BA_ "GenSigSendType" SG_ 1287 Reserved40 7;
BA_ "GenSigCycleTimeActive" SG_ 1287 Reserved40 200;
BA_ "GenSigCycleTime" SG_ 1287 Reserved40 200;
BA_ "GenSigTimeoutTime_HU_Mid_X451" SG_ 1287 RepeatMessageReq_VCU 0;
BA_ "GenSigTimeoutTime_HU_High_X451" SG_ 1287 RepeatMessageReq_VCU 0;
BA_ "GenSigTimeoutTime_HU_B" SG_ 1287 RepeatMessageReq_VCU 0;
BA_ "GenSigTimeoutTime_HU_A" SG_ 1287 RepeatMessageReq_VCU 0;
BA_ "GenSigTimeoutMsg_HU_Mid_X451" SG_ 1287 RepeatMessageReq_VCU 0;
BA_ "GenSigTimeoutMsg_HU_High_X451" SG_ 1287 RepeatMessageReq_VCU 0;
BA_ "GenSigTimeoutMsg_HU_B" SG_ 1287 RepeatMessageReq_VCU 0;
BA_ "GenSigTimeoutMsg_HU_A" SG_ 1287 RepeatMessageReq_VCU 0;
BA_ "GenSigSendType" SG_ 1287 RepeatMessageReq_VCU 7;
BA_ "GenSigCycleTimeActive" SG_ 1287 RepeatMessageReq_VCU 200;
BA_ "GenSigCycleTime" SG_ 1287 RepeatMessageReq_VCU 200;
BA_ "GenSigTimeoutTime_HU_Mid_X451" SG_ 1287 PreviousState_VCU 0;
BA_ "GenSigTimeoutTime_HU_High_X451" SG_ 1287 PreviousState_VCU 0;
BA_ "GenSigTimeoutTime_HU_B" SG_ 1287 PreviousState_VCU 0;
BA_ "GenSigTimeoutTime_HU_A" SG_ 1287 PreviousState_VCU 0;
BA_ "GenSigTimeoutMsg_HU_Mid_X451" SG_ 1287 PreviousState_VCU 0;
BA_ "GenSigTimeoutMsg_HU_High_X451" SG_ 1287 PreviousState_VCU 0;
BA_ "GenSigTimeoutMsg_HU_B" SG_ 1287 PreviousState_VCU 0;
BA_ "GenSigTimeoutMsg_HU_A" SG_ 1287 PreviousState_VCU 0;
BA_ "GenSigSendType" SG_ 1287 PreviousState_VCU 7;
BA_ "GenSigCycleTimeActive" SG_ 1287 PreviousState_VCU 200;
BA_ "GenSigCycleTime" SG_ 1287 PreviousState_VCU 200;
BA_ "GenSigTimeoutTime_HU_Mid_X451" SG_ 1287 NMCoOrdSlpReady_VCU 0;
BA_ "GenSigTimeoutTime_HU_High_X451" SG_ 1287 NMCoOrdSlpReady_VCU 0;
BA_ "GenSigTimeoutTime_HU_B" SG_ 1287 NMCoOrdSlpReady_VCU 0;
BA_ "GenSigTimeoutTime_HU_A" SG_ 1287 NMCoOrdSlpReady_VCU 0;
BA_ "GenSigTimeoutMsg_HU_Mid_X451" SG_ 1287 NMCoOrdSlpReady_VCU 0;
BA_ "GenSigTimeoutMsg_HU_High_X451" SG_ 1287 NMCoOrdSlpReady_VCU 0;
BA_ "GenSigTimeoutMsg_HU_B" SG_ 1287 NMCoOrdSlpReady_VCU 0;
BA_ "GenSigTimeoutMsg_HU_A" SG_ 1287 NMCoOrdSlpReady_VCU 0;
BA_ "GenSigSendType" SG_ 1287 NMCoOrdSlpReady_VCU 7;
BA_ "GenSigCycleTimeActive" SG_ 1287 NMCoOrdSlpReady_VCU 200;
BA_ "GenSigCycleTime" SG_ 1287 NMCoOrdSlpReady_VCU 200;
BA_ "GenSigTimeoutTime_HU_Mid_X451" SG_ 1287 CurrentState_VCU 0;
BA_ "GenSigTimeoutTime_HU_High_X451" SG_ 1287 CurrentState_VCU 0;
BA_ "GenSigTimeoutTime_HU_B" SG_ 1287 CurrentState_VCU 0;
BA_ "GenSigTimeoutTime_HU_A" SG_ 1287 CurrentState_VCU 0;
BA_ "GenSigTimeoutMsg_HU_Mid_X451" SG_ 1287 CurrentState_VCU 0;
BA_ "GenSigTimeoutMsg_HU_High_X451" SG_ 1287 CurrentState_VCU 0;
BA_ "GenSigTimeoutMsg_HU_B" SG_ 1287 CurrentState_VCU 0;
BA_ "GenSigTimeoutMsg_HU_A" SG_ 1287 CurrentState_VCU 0;
BA_ "GenSigSendType" SG_ 1287 CurrentState_VCU 7;
BA_ "GenSigCycleTimeActive" SG_ 1287 CurrentState_VCU 200;
BA_ "GenSigCycleTime" SG_ 1287 CurrentState_VCU 200;
BA_ "GenSigTimeoutTime_HU_Mid_X451" SG_ 1287 VCU_NMPDU_USER_DATA_D5 0;
BA_ "GenSigTimeoutTime_HU_High_X451" SG_ 1287 VCU_NMPDU_USER_DATA_D5 0;
BA_ "GenSigTimeoutTime_HU_B" SG_ 1287 VCU_NMPDU_USER_DATA_D5 0;
BA_ "GenSigTimeoutTime_HU_A" SG_ 1287 VCU_NMPDU_USER_DATA_D5 0;
BA_ "GenSigTimeoutMsg_HU_Mid_X451" SG_ 1287 VCU_NMPDU_USER_DATA_D5 0;
BA_ "GenSigTimeoutMsg_HU_High_X451" SG_ 1287 VCU_NMPDU_USER_DATA_D5 0;
BA_ "GenSigTimeoutMsg_HU_B" SG_ 1287 VCU_NMPDU_USER_DATA_D5 0;
BA_ "GenSigTimeoutMsg_HU_A" SG_ 1287 VCU_NMPDU_USER_DATA_D5 0;
BA_ "GenSigSendType" SG_ 1287 VCU_NMPDU_USER_DATA_D5 7;
BA_ "GenSigCycleTimeActive" SG_ 1287 VCU_NMPDU_USER_DATA_D5 200;
BA_ "GenSigCycleTime" SG_ 1287 VCU_NMPDU_USER_DATA_D5 200;
BA_ "GenSigTimeoutTime_HU_Mid_X451" SG_ 1287 VCU_NMPDU_USER_DATA_D4 0;
BA_ "GenSigTimeoutTime_HU_High_X451" SG_ 1287 VCU_NMPDU_USER_DATA_D4 0;
BA_ "GenSigTimeoutTime_HU_B" SG_ 1287 VCU_NMPDU_USER_DATA_D4 0;
BA_ "GenSigTimeoutTime_HU_A" SG_ 1287 VCU_NMPDU_USER_DATA_D4 0;
BA_ "GenSigTimeoutMsg_HU_Mid_X451" SG_ 1287 VCU_NMPDU_USER_DATA_D4 0;
BA_ "GenSigTimeoutMsg_HU_High_X451" SG_ 1287 VCU_NMPDU_USER_DATA_D4 0;
BA_ "GenSigTimeoutMsg_HU_B" SG_ 1287 VCU_NMPDU_USER_DATA_D4 0;
BA_ "GenSigTimeoutMsg_HU_A" SG_ 1287 VCU_NMPDU_USER_DATA_D4 0;
BA_ "GenSigSendType" SG_ 1287 VCU_NMPDU_USER_DATA_D4 7;
BA_ "GenSigCycleTimeActive" SG_ 1287 VCU_NMPDU_USER_DATA_D4 200;
BA_ "GenSigCycleTime" SG_ 1287 VCU_NMPDU_USER_DATA_D4 200;
BA_ "GenSigTimeoutTime_HU_Mid_X451" SG_ 1287 VCU_NMPDU_USER_DATA_D2 0;
BA_ "GenSigTimeoutTime_HU_High_X451" SG_ 1287 VCU_NMPDU_USER_DATA_D2 0;
BA_ "GenSigTimeoutTime_HU_B" SG_ 1287 VCU_NMPDU_USER_DATA_D2 0;
BA_ "GenSigTimeoutTime_HU_A" SG_ 1287 VCU_NMPDU_USER_DATA_D2 0;
BA_ "GenSigTimeoutMsg_HU_Mid_X451" SG_ 1287 VCU_NMPDU_USER_DATA_D2 0;
BA_ "GenSigTimeoutMsg_HU_High_X451" SG_ 1287 VCU_NMPDU_USER_DATA_D2 0;
BA_ "GenSigTimeoutMsg_HU_B" SG_ 1287 VCU_NMPDU_USER_DATA_D2 0;
BA_ "GenSigTimeoutMsg_HU_A" SG_ 1287 VCU_NMPDU_USER_DATA_D2 0;
BA_ "GenSigSendType" SG_ 1287 VCU_NMPDU_USER_DATA_D2 7;
BA_ "GenSigCycleTimeActive" SG_ 1287 VCU_NMPDU_USER_DATA_D2 200;
BA_ "GenSigCycleTime" SG_ 1287 VCU_NMPDU_USER_DATA_D2 200;
BA_ "GenSigTimeoutTime_HU_Mid_X451" SG_ 1287 VCU_NMPDU_USER_DATA_D1 0;
BA_ "GenSigTimeoutTime_HU_High_X451" SG_ 1287 VCU_NMPDU_USER_DATA_D1 0;
BA_ "GenSigTimeoutTime_HU_B" SG_ 1287 VCU_NMPDU_USER_DATA_D1 0;
BA_ "GenSigTimeoutTime_HU_A" SG_ 1287 VCU_NMPDU_USER_DATA_D1 0;
BA_ "GenSigTimeoutMsg_HU_Mid_X451" SG_ 1287 VCU_NMPDU_USER_DATA_D1 0;
BA_ "GenSigTimeoutMsg_HU_High_X451" SG_ 1287 VCU_NMPDU_USER_DATA_D1 0;
BA_ "GenSigTimeoutMsg_HU_B" SG_ 1287 VCU_NMPDU_USER_DATA_D1 0;
BA_ "GenSigTimeoutMsg_HU_A" SG_ 1287 VCU_NMPDU_USER_DATA_D1 0;
BA_ "GenSigSendType" SG_ 1287 VCU_NMPDU_USER_DATA_D1 7;
BA_ "GenSigCycleTimeActive" SG_ 1287 VCU_NMPDU_USER_DATA_D1 200;
BA_ "GenSigCycleTime" SG_ 1287 VCU_NMPDU_USER_DATA_D1 200;
BA_ "GenSigTimeoutTime_HU_Mid_X451" SG_ 1287 VCU_NMPDU_SRC_ECU_ID 0;
BA_ "GenSigTimeoutTime_HU_High_X451" SG_ 1287 VCU_NMPDU_SRC_ECU_ID 0;
BA_ "GenSigTimeoutTime_HU_B" SG_ 1287 VCU_NMPDU_SRC_ECU_ID 0;
BA_ "GenSigTimeoutTime_HU_A" SG_ 1287 VCU_NMPDU_SRC_ECU_ID 0;
BA_ "GenSigTimeoutMsg_HU_Mid_X451" SG_ 1287 VCU_NMPDU_SRC_ECU_ID 0;
BA_ "GenSigTimeoutMsg_HU_High_X451" SG_ 1287 VCU_NMPDU_SRC_ECU_ID 0;
BA_ "GenSigTimeoutMsg_HU_B" SG_ 1287 VCU_NMPDU_SRC_ECU_ID 0;
BA_ "GenSigTimeoutMsg_HU_A" SG_ 1287 VCU_NMPDU_SRC_ECU_ID 0;
BA_ "GenSigSendType" SG_ 1287 VCU_NMPDU_SRC_ECU_ID 7;
BA_ "GenSigCycleTimeActive" SG_ 1287 VCU_NMPDU_SRC_ECU_ID 200;
BA_ "GenSigCycleTime" SG_ 1287 VCU_NMPDU_SRC_ECU_ID 200;
BA_ "GenSigTimeoutTime_HU_Mid_X451" SG_ 1287 ActiveWakeUp_VCU 0;
BA_ "GenSigTimeoutTime_HU_High_X451" SG_ 1287 ActiveWakeUp_VCU 0;
BA_ "GenSigTimeoutTime_HU_B" SG_ 1287 ActiveWakeUp_VCU 0;
BA_ "GenSigTimeoutTime_HU_A" SG_ 1287 ActiveWakeUp_VCU 0;
BA_ "GenSigTimeoutMsg_HU_Mid_X451" SG_ 1287 ActiveWakeUp_VCU 0;
BA_ "GenSigTimeoutMsg_HU_High_X451" SG_ 1287 ActiveWakeUp_VCU 0;
BA_ "GenSigTimeoutMsg_HU_B" SG_ 1287 ActiveWakeUp_VCU 0;
BA_ "GenSigTimeoutMsg_HU_A" SG_ 1287 ActiveWakeUp_VCU 0;
BA_ "GenSigSendType" SG_ 1287 ActiveWakeUp_VCU 7;
BA_ "GenSigCycleTimeActive" SG_ 1287 ActiveWakeUp_VCU 200;
BA_ "GenSigCycleTime" SG_ 1287 ActiveWakeUp_VCU 200;
BA_ "GenSigSendType" SG_ 703 PaddleShifterCounter 7;
BA_ "GenSigCycleTimeActive" SG_ 703 PaddleShifterCounter 100;
BA_ "GenSigCycleTime" SG_ 703 PaddleShifterCounter 100;
BA_ "GenSigSendType" SG_ 703 PaddleShifterChecksum 7;
BA_ "GenSigCycleTimeActive" SG_ 703 PaddleShifterChecksum 100;
BA_ "GenSigCycleTime" SG_ 703 PaddleShifterChecksum 100;
BA_ "GenSigSendType" SG_ 703 PaddleShifterStatus 7;
BA_ "GenSigCycleTimeActive" SG_ 703 PaddleShifterStatus 100;
BA_ "GenSigCycleTime" SG_ 703 PaddleShifterStatus 100;
BA_ "GenSigStartValue" SG_ 703 PaddleShifter 1;
BA_ "GenSigSendType" SG_ 703 PaddleShifter 7;
BA_ "GenSigCycleTimeActive" SG_ 703 PaddleShifter 100;
BA_ "GenSigCycleTime" SG_ 703 PaddleShifter 100;
BA_ "GenSigTimeoutTime_HU_Mid_X451" SG_ 703 OATICSigNewStatus 0;
BA_ "GenSigTimeoutTime_HU_High_X451" SG_ 703 OATICSigNewStatus 0;
BA_ "GenSigTimeoutTime_HU_B" SG_ 703 OATICSigNewStatus 0;
BA_ "GenSigTimeoutTime_HU_A" SG_ 703 OATICSigNewStatus 0;
BA_ "GenSigTimeoutMsg_HU_Mid_X451" SG_ 703 OATICSigNewStatus 0;
BA_ "GenSigTimeoutMsg_HU_High_X451" SG_ 703 OATICSigNewStatus 0;
BA_ "GenSigTimeoutMsg_HU_B" SG_ 703 OATICSigNewStatus 0;
BA_ "GenSigTimeoutMsg_HU_A" SG_ 703 OATICSigNewStatus 0;
BA_ "GenSigStartValue" SG_ 703 OATICSigNewStatus 2;
BA_ "GenSigSendType" SG_ 703 OATICSigNewStatus 7;
BA_ "GenSigCycleTimeActive" SG_ 703 OATICSigNewStatus 100;
BA_ "GenSigCycleTime" SG_ 703 OATICSigNewStatus 100;
BA_ "GenSigTimeoutTime_HU_Mid_X451" SG_ 703 OATICSigNew 0;
BA_ "GenSigTimeoutTime_HU_High_X451" SG_ 703 OATICSigNew 0;
BA_ "GenSigTimeoutTime_HU_B" SG_ 703 OATICSigNew 0;
BA_ "GenSigTimeoutTime_HU_A" SG_ 703 OATICSigNew 0;
BA_ "GenSigTimeoutMsg_HU_Mid_X451" SG_ 703 OATICSigNew 0;
BA_ "GenSigTimeoutMsg_HU_High_X451" SG_ 703 OATICSigNew 0;
BA_ "GenSigTimeoutMsg_HU_B" SG_ 703 OATICSigNew 0;
BA_ "GenSigTimeoutMsg_HU_A" SG_ 703 OATICSigNew 0;
BA_ "GenSigStartValue" SG_ 703 OATICSigNew 80;
BA_ "GenSigSendType" SG_ 703 OATICSigNew 7;
BA_ "GenSigCycleTimeActive" SG_ 703 OATICSigNew 100;
BA_ "GenSigCycleTime" SG_ 703 OATICSigNew 100;
BA_ "GenSigTimeoutTime_HU_Mid_X451" SG_ 724 PtcTempValStatus 0;
BA_ "GenSigTimeoutTime_HU_High_X451" SG_ 724 PtcTempValStatus 0;
BA_ "GenSigTimeoutTime_HU_B" SG_ 724 PtcTempValStatus 0;
BA_ "GenSigTimeoutTime_HU_A" SG_ 724 PtcTempValStatus 0;
BA_ "GenSigTimeoutMsg_HU_Mid_X451" SG_ 724 PtcTempValStatus 0;
BA_ "GenSigTimeoutMsg_HU_High_X451" SG_ 724 PtcTempValStatus 0;
BA_ "GenSigTimeoutMsg_HU_B" SG_ 724 PtcTempValStatus 0;
BA_ "GenSigTimeoutMsg_HU_A" SG_ 724 PtcTempValStatus 0;
BA_ "GenSigSendType" SG_ 724 PtcTempValStatus 7;
BA_ "GenSigCycleTimeActive" SG_ 724 PtcTempValStatus 100;
BA_ "GenSigCycleTime" SG_ 724 PtcTempValStatus 100;
BA_ "GenSigTimeoutTime_HU_Mid_X451" SG_ 724 PtcTempVal 0;
BA_ "GenSigTimeoutTime_HU_High_X451" SG_ 724 PtcTempVal 0;
BA_ "GenSigTimeoutTime_HU_B" SG_ 724 PtcTempVal 0;
BA_ "GenSigTimeoutTime_HU_A" SG_ 724 PtcTempVal 0;
BA_ "GenSigTimeoutMsg_HU_Mid_X451" SG_ 724 PtcTempVal 0;
BA_ "GenSigTimeoutMsg_HU_High_X451" SG_ 724 PtcTempVal 0;
BA_ "GenSigTimeoutMsg_HU_B" SG_ 724 PtcTempVal 0;
BA_ "GenSigTimeoutMsg_HU_A" SG_ 724 PtcTempVal 0;
BA_ "GenSigStartValue" SG_ 724 PtcTempVal 40;
BA_ "GenSigSendType" SG_ 724 PtcTempVal 7;
BA_ "GenSigCycleTimeActive" SG_ 724 PtcTempVal 100;
BA_ "GenSigCycleTime" SG_ 724 PtcTempVal 100;
BA_ "GenSigTimeoutTime_HU_Mid_X451" SG_ 724 CCMVbatStatus 0;
BA_ "GenSigTimeoutTime_HU_High_X451" SG_ 724 CCMVbatStatus 0;
BA_ "GenSigTimeoutTime_HU_B" SG_ 724 CCMVbatStatus 0;
BA_ "GenSigTimeoutTime_HU_A" SG_ 724 CCMVbatStatus 0;
BA_ "GenSigTimeoutMsg_HU_Mid_X451" SG_ 724 CCMVbatStatus 0;
BA_ "GenSigTimeoutMsg_HU_High_X451" SG_ 724 CCMVbatStatus 0;
BA_ "GenSigTimeoutMsg_HU_B" SG_ 724 CCMVbatStatus 0;
BA_ "GenSigTimeoutMsg_HU_A" SG_ 724 CCMVbatStatus 0;
BA_ "GenSigSendType" SG_ 724 CCMVbatStatus 7;
BA_ "GenSigCycleTimeActive" SG_ 724 CCMVbatStatus 100;
BA_ "GenSigCycleTime" SG_ 724 CCMVbatStatus 100;
BA_ "GenSigTimeoutTime_HU_Mid_X451" SG_ 724 CCMVbat 0;
BA_ "GenSigTimeoutTime_HU_High_X451" SG_ 724 CCMVbat 0;
BA_ "GenSigTimeoutTime_HU_B" SG_ 724 CCMVbat 0;
BA_ "GenSigTimeoutTime_HU_A" SG_ 724 CCMVbat 0;
BA_ "GenSigTimeoutMsg_HU_Mid_X451" SG_ 724 CCMVbat 0;
BA_ "GenSigTimeoutMsg_HU_High_X451" SG_ 724 CCMVbat 0;
BA_ "GenSigTimeoutMsg_HU_B" SG_ 724 CCMVbat 0;
BA_ "GenSigTimeoutMsg_HU_A" SG_ 724 CCMVbat 0;
BA_ "GenSigSendType" SG_ 724 CCMVbat 7;
BA_ "GenSigCycleTimeActive" SG_ 724 CCMVbat 100;
BA_ "GenSigCycleTime" SG_ 724 CCMVbat 100;
BA_ "GenSigTimeoutTime_HU_Mid_X451" SG_ 724 BlowerFBVoltageStatus 0;
BA_ "GenSigTimeoutTime_HU_High_X451" SG_ 724 BlowerFBVoltageStatus 0;
BA_ "GenSigTimeoutTime_HU_B" SG_ 724 BlowerFBVoltageStatus 0;
BA_ "GenSigTimeoutTime_HU_A" SG_ 724 BlowerFBVoltageStatus 0;
BA_ "GenSigTimeoutMsg_HU_Mid_X451" SG_ 724 BlowerFBVoltageStatus 0;
BA_ "GenSigTimeoutMsg_HU_High_X451" SG_ 724 BlowerFBVoltageStatus 0;
BA_ "GenSigTimeoutMsg_HU_B" SG_ 724 BlowerFBVoltageStatus 0;
BA_ "GenSigTimeoutMsg_HU_A" SG_ 724 BlowerFBVoltageStatus 0;
BA_ "GenSigSendType" SG_ 724 BlowerFBVoltageStatus 7;
BA_ "GenSigCycleTimeActive" SG_ 724 BlowerFBVoltageStatus 100;
BA_ "GenSigCycleTime" SG_ 724 BlowerFBVoltageStatus 100;
BA_ "GenSigTimeoutTime_HU_Mid_X451" SG_ 724 BlowerFBVoltage 0;
BA_ "GenSigTimeoutTime_HU_High_X451" SG_ 724 BlowerFBVoltage 0;
BA_ "GenSigTimeoutTime_HU_B" SG_ 724 BlowerFBVoltage 0;
BA_ "GenSigTimeoutTime_HU_A" SG_ 724 BlowerFBVoltage 0;
BA_ "GenSigTimeoutMsg_HU_Mid_X451" SG_ 724 BlowerFBVoltage 0;
BA_ "GenSigTimeoutMsg_HU_High_X451" SG_ 724 BlowerFBVoltage 0;
BA_ "GenSigTimeoutMsg_HU_B" SG_ 724 BlowerFBVoltage 0;
BA_ "GenSigTimeoutMsg_HU_A" SG_ 724 BlowerFBVoltage 0;
BA_ "GenSigSendType" SG_ 724 BlowerFBVoltage 7;
BA_ "GenSigCycleTimeActive" SG_ 724 BlowerFBVoltage 100;
BA_ "GenSigCycleTime" SG_ 724 BlowerFBVoltage 100;
BA_ "GenSigTimeoutTime_HU_Mid_X451" SG_ 724 BlowerPWMStatus 0;
BA_ "GenSigTimeoutTime_HU_High_X451" SG_ 724 BlowerPWMStatus 0;
BA_ "GenSigTimeoutTime_HU_B" SG_ 724 BlowerPWMStatus 0;
BA_ "GenSigTimeoutTime_HU_A" SG_ 724 BlowerPWMStatus 0;
BA_ "GenSigTimeoutMsg_HU_Mid_X451" SG_ 724 BlowerPWMStatus 0;
BA_ "GenSigTimeoutMsg_HU_High_X451" SG_ 724 BlowerPWMStatus 0;
BA_ "GenSigTimeoutMsg_HU_B" SG_ 724 BlowerPWMStatus 0;
BA_ "GenSigTimeoutMsg_HU_A" SG_ 724 BlowerPWMStatus 0;
BA_ "GenSigSendType" SG_ 724 BlowerPWMStatus 7;
BA_ "GenSigCycleTimeActive" SG_ 724 BlowerPWMStatus 100;
BA_ "GenSigCycleTime" SG_ 724 BlowerPWMStatus 100;
BA_ "GenSigTimeoutTime_HU_Mid_X451" SG_ 724 BlowerPWM 0;
BA_ "GenSigTimeoutTime_HU_High_X451" SG_ 724 BlowerPWM 0;
BA_ "GenSigTimeoutTime_HU_B" SG_ 724 BlowerPWM 0;
BA_ "GenSigTimeoutTime_HU_A" SG_ 724 BlowerPWM 0;
BA_ "GenSigTimeoutMsg_HU_Mid_X451" SG_ 724 BlowerPWM 0;
BA_ "GenSigTimeoutMsg_HU_High_X451" SG_ 724 BlowerPWM 0;
BA_ "GenSigTimeoutMsg_HU_B" SG_ 724 BlowerPWM 0;
BA_ "GenSigTimeoutMsg_HU_A" SG_ 724 BlowerPWM 0;
BA_ "GenSigSendType" SG_ 724 BlowerPWM 7;
BA_ "GenSigCycleTimeActive" SG_ 724 BlowerPWM 100;
BA_ "GenSigCycleTime" SG_ 724 BlowerPWM 100;
BA_ "GenSigTimeoutTime_HU_Mid_X451" SG_ 724 BlowerStatus 0;
BA_ "GenSigTimeoutTime_HU_High_X451" SG_ 724 BlowerStatus 0;
BA_ "GenSigTimeoutTime_HU_B" SG_ 724 BlowerStatus 0;
BA_ "GenSigTimeoutTime_HU_A" SG_ 724 BlowerStatus 0;
BA_ "GenSigTimeoutMsg_HU_Mid_X451" SG_ 724 BlowerStatus 0;
BA_ "GenSigTimeoutMsg_HU_High_X451" SG_ 724 BlowerStatus 0;
BA_ "GenSigTimeoutMsg_HU_B" SG_ 724 BlowerStatus 0;
BA_ "GenSigTimeoutMsg_HU_A" SG_ 724 BlowerStatus 0;
BA_ "GenSigSendType" SG_ 724 BlowerStatus 7;
BA_ "GenSigCycleTimeActive" SG_ 724 BlowerStatus 100;
BA_ "GenSigCycleTime" SG_ 724 BlowerStatus 100;
BA_ "GenSigTimeoutTime_HU_Mid_X451" SG_ 724 BlowerState 0;
BA_ "GenSigTimeoutTime_HU_High_X451" SG_ 724 BlowerState 0;
BA_ "GenSigTimeoutTime_HU_B" SG_ 724 BlowerState 0;
BA_ "GenSigTimeoutTime_HU_A" SG_ 724 BlowerState 0;
BA_ "GenSigTimeoutMsg_HU_Mid_X451" SG_ 724 BlowerState 0;
BA_ "GenSigTimeoutMsg_HU_High_X451" SG_ 724 BlowerState 0;
BA_ "GenSigTimeoutMsg_HU_B" SG_ 724 BlowerState 0;
BA_ "GenSigTimeoutMsg_HU_A" SG_ 724 BlowerState 0;
BA_ "GenSigSendType" SG_ 724 BlowerState 7;
BA_ "GenSigCycleTimeActive" SG_ 724 BlowerState 100;
BA_ "GenSigCycleTime" SG_ 724 BlowerState 100;
BA_ "GenSigTimeoutTime_HU_Mid_X451" SG_ 724 HeatingPwrValStatus 0;
BA_ "GenSigTimeoutTime_HU_High_X451" SG_ 724 HeatingPwrValStatus 0;
BA_ "GenSigTimeoutTime_HU_B" SG_ 724 HeatingPwrValStatus 0;
BA_ "GenSigTimeoutTime_HU_A" SG_ 724 HeatingPwrValStatus 0;
BA_ "GenSigTimeoutMsg_HU_Mid_X451" SG_ 724 HeatingPwrValStatus 0;
BA_ "GenSigTimeoutMsg_HU_High_X451" SG_ 724 HeatingPwrValStatus 0;
BA_ "GenSigTimeoutMsg_HU_B" SG_ 724 HeatingPwrValStatus 0;
BA_ "GenSigTimeoutMsg_HU_A" SG_ 724 HeatingPwrValStatus 0;
BA_ "GenSigSendType" SG_ 724 HeatingPwrValStatus 7;
BA_ "GenSigCycleTimeActive" SG_ 724 HeatingPwrValStatus 100;
BA_ "GenSigCycleTime" SG_ 724 HeatingPwrValStatus 100;
BA_ "GenSigTimeoutTime_HU_Mid_X451" SG_ 724 HeatingPwrVal 0;
BA_ "GenSigTimeoutTime_HU_High_X451" SG_ 724 HeatingPwrVal 0;
BA_ "GenSigTimeoutTime_HU_B" SG_ 724 HeatingPwrVal 0;
BA_ "GenSigTimeoutTime_HU_A" SG_ 724 HeatingPwrVal 0;
BA_ "GenSigTimeoutMsg_HU_Mid_X451" SG_ 724 HeatingPwrVal 0;
BA_ "GenSigTimeoutMsg_HU_High_X451" SG_ 724 HeatingPwrVal 0;
BA_ "GenSigTimeoutMsg_HU_B" SG_ 724 HeatingPwrVal 0;
BA_ "GenSigTimeoutMsg_HU_A" SG_ 724 HeatingPwrVal 0;
BA_ "GenSigSendType" SG_ 724 HeatingPwrVal 7;
BA_ "GenSigCycleTimeActive" SG_ 724 HeatingPwrVal 100;
BA_ "GenSigCycleTime" SG_ 724 HeatingPwrVal 100;
BA_ "GenSigTimeoutTime_HU_Mid_X451" SG_ 724 CoolingPwrValStatus 0;
BA_ "GenSigTimeoutTime_HU_High_X451" SG_ 724 CoolingPwrValStatus 0;
BA_ "GenSigTimeoutTime_HU_B" SG_ 724 CoolingPwrValStatus 0;
BA_ "GenSigTimeoutTime_HU_A" SG_ 724 CoolingPwrValStatus 0;
BA_ "GenSigTimeoutMsg_HU_Mid_X451" SG_ 724 CoolingPwrValStatus 0;
BA_ "GenSigTimeoutMsg_HU_High_X451" SG_ 724 CoolingPwrValStatus 0;
BA_ "GenSigTimeoutMsg_HU_B" SG_ 724 CoolingPwrValStatus 0;
BA_ "GenSigTimeoutMsg_HU_A" SG_ 724 CoolingPwrValStatus 0;
BA_ "GenSigStartValue" SG_ 724 CoolingPwrValStatus 2;
BA_ "GenSigSendType" SG_ 724 CoolingPwrValStatus 7;
BA_ "GenSigCycleTimeActive" SG_ 724 CoolingPwrValStatus 100;
BA_ "GenSigCycleTime" SG_ 724 CoolingPwrValStatus 100;
BA_ "GenSigTimeoutTime_HU_Mid_X451" SG_ 724 CoolingPwrVal 0;
BA_ "GenSigTimeoutTime_HU_High_X451" SG_ 724 CoolingPwrVal 0;
BA_ "GenSigTimeoutTime_HU_B" SG_ 724 CoolingPwrVal 0;
BA_ "GenSigTimeoutTime_HU_A" SG_ 724 CoolingPwrVal 0;
BA_ "GenSigTimeoutMsg_HU_Mid_X451" SG_ 724 CoolingPwrVal 0;
BA_ "GenSigTimeoutMsg_HU_High_X451" SG_ 724 CoolingPwrVal 0;
BA_ "GenSigTimeoutMsg_HU_B" SG_ 724 CoolingPwrVal 0;
BA_ "GenSigTimeoutMsg_HU_A" SG_ 724 CoolingPwrVal 0;
BA_ "GenSigSendType" SG_ 724 CoolingPwrVal 7;
BA_ "GenSigCycleTimeActive" SG_ 724 CoolingPwrVal 100;
BA_ "GenSigCycleTime" SG_ 724 CoolingPwrVal 100;
BA_ "GenSigTimeoutTime_HU_Mid_X451" SG_ 724 AcReqNew 0;
BA_ "GenSigTimeoutTime_HU_High_X451" SG_ 724 AcReqNew 0;
BA_ "GenSigTimeoutTime_HU_B" SG_ 724 AcReqNew 0;
BA_ "GenSigTimeoutTime_HU_A" SG_ 724 AcReqNew 0;
BA_ "GenSigTimeoutMsg_HU_Mid_X451" SG_ 724 AcReqNew 0;
BA_ "GenSigTimeoutMsg_HU_High_X451" SG_ 724 AcReqNew 0;
BA_ "GenSigTimeoutMsg_HU_B" SG_ 724 AcReqNew 0;
BA_ "GenSigTimeoutMsg_HU_A" SG_ 724 AcReqNew 0;
BA_ "GenSigSendType" SG_ 724 AcReqNew 7;
BA_ "GenSigCycleTimeActive" SG_ 724 AcReqNew 100;
BA_ "GenSigCycleTime" SG_ 724 AcReqNew 100;
BA_ "GenSigSendType" SG_ 408 ParkBrkStatus2 7;
BA_ "GenSigCycleTimeActive" SG_ 408 ParkBrkStatus2 20;
BA_ "GenSigCycleTime" SG_ 408 ParkBrkStatus2 20;
BA_ "GenSigStartValue" SG_ 408 ParkBrkState2 3;
BA_ "GenSigSendType" SG_ 408 ParkBrkState2 7;
BA_ "GenSigCycleTimeActive" SG_ 408 ParkBrkState2 20;
BA_ "GenSigCycleTime" SG_ 408 ParkBrkState2 20;
BA_ "GenSigSendType" SG_ 408 MSG_CNT_4 7;
BA_ "GenSigCycleTimeActive" SG_ 408 MSG_CNT_4 20;
BA_ "GenSigCycleTime" SG_ 408 MSG_CNT_4 20;
BA_ "GenSigSendType" SG_ 408 CRC_4 7;
BA_ "GenSigCycleTimeActive" SG_ 408 CRC_4 20;
BA_ "GenSigCycleTime" SG_ 408 CRC_4 20;
BA_ "GenSigSendType" SG_ 408 ICDispSpeedSigStatus 7;
BA_ "GenSigCycleTimeActive" SG_ 408 ICDispSpeedSigStatus 20;
BA_ "GenSigCycleTime" SG_ 408 ICDispSpeedSigStatus 20;
BA_ "GenSigSendType" SG_ 408 ICDispSpeedSig 7;
BA_ "GenSigCycleTimeActive" SG_ 408 ICDispSpeedSig 20;
BA_ "GenSigCycleTime" SG_ 408 ICDispSpeedSig 20;
BA_ "GenSigSendType" SG_ 738 BcmHbaFaultState 7;
BA_ "GenSigCycleTimeActive" SG_ 738 BcmHbaFaultState 100;
BA_ "GenSigCycleTime" SG_ 738 BcmHbaFaultState 100;
BA_ "GenSigSendType" SG_ 738 HighBeamState 7;
BA_ "GenSigCycleTimeActive" SG_ 738 HighBeamState 100;
BA_ "GenSigCycleTime" SG_ 738 HighBeamState 100;
BA_ "GenSigSendType" SG_ 738 RearWiperStateStatus 7;
BA_ "GenSigCycleTimeActive" SG_ 738 RearWiperStateStatus 100;
BA_ "GenSigCycleTime" SG_ 738 RearWiperStateStatus 100;
BA_ "GenSigSendType" SG_ 738 RearWiperState 7;
BA_ "GenSigCycleTimeActive" SG_ 738 RearWiperState 100;
BA_ "GenSigCycleTime" SG_ 738 RearWiperState 100;
BA_ "GenSigSendType" SG_ 738 RemoteUsecaseStateStatus 7;
BA_ "GenSigCycleTimeActive" SG_ 738 RemoteUsecaseStateStatus 100;
BA_ "GenSigCycleTime" SG_ 738 RemoteUsecaseStateStatus 100;
BA_ "GenSigStartValue" SG_ 738 RemoteUsecaseState 1;
BA_ "GenSigSendType" SG_ 738 RemoteUsecaseState 7;
BA_ "GenSigCycleTimeActive" SG_ 738 RemoteUsecaseState 100;
BA_ "GenSigCycleTime" SG_ 738 RemoteUsecaseState 100;
BA_ "GenSigStartValue" SG_ 738 DewPointTemperature 395;
BA_ "GenSigSendType" SG_ 738 DewPointTemperature 7;
BA_ "GenSigCycleTimeActive" SG_ 738 DewPointTemperature 100;
BA_ "GenSigCycleTime" SG_ 738 DewPointTemperature 100;
BA_ "GenSigStartValue" SG_ 738 WindshieldTemperature 79;
BA_ "GenSigSendType" SG_ 738 WindshieldTemperature 7;
BA_ "GenSigCycleTimeActive" SG_ 738 WindshieldTemperature 100;
BA_ "GenSigCycleTime" SG_ 738 WindshieldTemperature 100;
BA_ "GenSigSendType" SG_ 738 HumidityValue 7;
BA_ "GenSigCycleTimeActive" SG_ 738 HumidityValue 100;
BA_ "GenSigCycleTime" SG_ 738 HumidityValue 100;
BA_ "GenSigSendType" SG_ 738 HornStateStatus 7;
BA_ "GenSigCycleTimeActive" SG_ 738 HornStateStatus 100;
BA_ "GenSigCycleTime" SG_ 738 HornStateStatus 100;
BA_ "GenSigSendType" SG_ 738 HornState 7;
BA_ "GenSigCycleTimeActive" SG_ 738 HornState 100;
BA_ "GenSigCycleTime" SG_ 738 HornState 100;
BA_ "GenSigSendType" SG_ 738 ForcePanicStatus 7;
BA_ "GenSigCycleTimeActive" SG_ 738 ForcePanicStatus 100;
BA_ "GenSigCycleTime" SG_ 738 ForcePanicStatus 100;
BA_ "GenSigSendType" SG_ 738 ApprochLampStateStatus 7;
BA_ "GenSigCycleTimeActive" SG_ 738 ApprochLampStateStatus 100;
BA_ "GenSigCycleTime" SG_ 738 ApprochLampStateStatus 100;
BA_ "GenSigSendType" SG_ 738 ApprochLampState 7;
BA_ "GenSigCycleTimeActive" SG_ 738 ApprochLampState 100;
BA_ "GenSigCycleTime" SG_ 738 ApprochLampState 100;
BA_ "GenSigSendType" SG_ 738 LowBeamTellTaleStatus 7;
BA_ "GenSigCycleTimeActive" SG_ 738 LowBeamTellTaleStatus 100;
BA_ "GenSigCycleTime" SG_ 738 LowBeamTellTaleStatus 100;
BA_ "GenSigSendType" SG_ 738 LowBeamTellTale 7;
BA_ "GenSigCycleTimeActive" SG_ 738 LowBeamTellTale 100;
BA_ "GenSigCycleTime" SG_ 738 LowBeamTellTale 100;
BA_ "GenSigSendType" SG_ 738 IntrusionInfoStateStatus 7;
BA_ "GenSigCycleTimeActive" SG_ 738 IntrusionInfoStateStatus 100;
BA_ "GenSigCycleTime" SG_ 738 IntrusionInfoStateStatus 100;
BA_ "GenSigSendType" SG_ 738 IntrusionInfoState 7;
BA_ "GenSigCycleTimeActive" SG_ 738 IntrusionInfoState 100;
BA_ "GenSigCycleTime" SG_ 738 IntrusionInfoState 100;
BA_ "GenSigSendType" SG_ 738 HazardLampState 7;
BA_ "GenSigCycleTimeActive" SG_ 738 HazardLampState 100;
BA_ "GenSigCycleTime" SG_ 738 HazardLampState 100;
BA_ "GenSigSendType" SG_ 738 HazardLampStateStatus 7;
BA_ "GenSigCycleTimeActive" SG_ 738 HazardLampStateStatus 100;
BA_ "GenSigCycleTime" SG_ 738 HazardLampStateStatus 100;
BA_ "GenSigSendType" SG_ 738 VehicleSecured 7;
BA_ "GenSigCycleTimeActive" SG_ 738 VehicleSecured 100;
BA_ "GenSigCycleTime" SG_ 738 VehicleSecured 100;
BA_ "GenSigSendType" SG_ 738 VehicleSecuredStatus 7;
BA_ "GenSigCycleTimeActive" SG_ 738 VehicleSecuredStatus 100;
BA_ "GenSigCycleTime" SG_ 738 VehicleSecuredStatus 100;
BA_ "GenSigTimeoutTime_HU_Mid_X451" SG_ 495 SharedLocationReqAck 0;
BA_ "GenSigTimeoutTime_HU_High_X451" SG_ 495 SharedLocationReqAck 0;
BA_ "GenSigTimeoutTime_HU_B" SG_ 495 SharedLocationReqAck 0;
BA_ "GenSigTimeoutTime_HU_A" SG_ 495 SharedLocationReqAck 0;
BA_ "GenSigTimeoutMsg_HU_Mid_X451" SG_ 495 SharedLocationReqAck 0;
BA_ "GenSigTimeoutMsg_HU_High_X451" SG_ 495 SharedLocationReqAck 0;
BA_ "GenSigTimeoutMsg_HU_B" SG_ 495 SharedLocationReqAck 0;
BA_ "GenSigTimeoutMsg_HU_A" SG_ 495 SharedLocationReqAck 0;
BA_ "GenSigSendType" SG_ 495 SharedLocationReqAck 2;
BA_ "GenSigTimeoutMsg_HU_High_X445" SG_ 495 SharedLocationReqAck 0;
BA_ "GenSigTimeoutMsg_HU_Mid_X445" SG_ 495 SharedLocationReqAck 0;
BA_ "GenSigTimeoutTime_HU_High_X445" SG_ 495 SharedLocationReqAck 0;
BA_ "GenSigTimeoutTime_HU_Mid_X445" SG_ 495 SharedLocationReqAck 0;
BA_ "GenSigTimeoutMsg_IVI" SG_ 495 SharedLocationReqAck 0;
BA_ "GenSigTimeoutTime_IVI" SG_ 495 SharedLocationReqAck 0;
BA_ "GenSigTimeoutTime_HU_Mid_X451" SG_ 495 CommunityHelpResp 0;
BA_ "GenSigTimeoutTime_HU_High_X451" SG_ 495 CommunityHelpResp 0;
BA_ "GenSigTimeoutTime_HU_B" SG_ 495 CommunityHelpResp 0;
BA_ "GenSigTimeoutTime_HU_A" SG_ 495 CommunityHelpResp 0;
BA_ "GenSigTimeoutMsg_HU_Mid_X451" SG_ 495 CommunityHelpResp 0;
BA_ "GenSigTimeoutMsg_HU_High_X451" SG_ 495 CommunityHelpResp 0;
BA_ "GenSigTimeoutMsg_HU_B" SG_ 495 CommunityHelpResp 0;
BA_ "GenSigTimeoutMsg_HU_A" SG_ 495 CommunityHelpResp 0;
BA_ "GenSigSendType" SG_ 495 CommunityHelpResp 2;
BA_ "GenSigTimeoutMsg_HU_High_X445" SG_ 495 CommunityHelpResp 0;
BA_ "GenSigTimeoutMsg_HU_Mid_X445" SG_ 495 CommunityHelpResp 0;
BA_ "GenSigTimeoutTime_HU_High_X445" SG_ 495 CommunityHelpResp 0;
BA_ "GenSigTimeoutTime_HU_Mid_X445" SG_ 495 CommunityHelpResp 0;
BA_ "GenSigTimeoutMsg_IVI" SG_ 495 CommunityHelpResp 0;
BA_ "GenSigTimeoutTime_IVI" SG_ 495 CommunityHelpResp 0;
BA_ "GenSigTimeoutTime_HU_Mid_X451" SG_ 495 CommunityHelpNotif 0;
BA_ "GenSigTimeoutTime_HU_High_X451" SG_ 495 CommunityHelpNotif 0;
BA_ "GenSigTimeoutTime_HU_B" SG_ 495 CommunityHelpNotif 0;
BA_ "GenSigTimeoutTime_HU_A" SG_ 495 CommunityHelpNotif 0;
BA_ "GenSigTimeoutMsg_HU_Mid_X451" SG_ 495 CommunityHelpNotif 0;
BA_ "GenSigTimeoutMsg_HU_High_X451" SG_ 495 CommunityHelpNotif 0;
BA_ "GenSigTimeoutMsg_HU_B" SG_ 495 CommunityHelpNotif 0;
BA_ "GenSigTimeoutMsg_HU_A" SG_ 495 CommunityHelpNotif 0;
BA_ "GenSigSendType" SG_ 495 CommunityHelpNotif 2;
BA_ "GenSigTimeoutMsg_HU_High_X445" SG_ 495 CommunityHelpNotif 0;
BA_ "GenSigTimeoutMsg_HU_Mid_X445" SG_ 495 CommunityHelpNotif 0;
BA_ "GenSigTimeoutTime_HU_High_X445" SG_ 495 CommunityHelpNotif 0;
BA_ "GenSigTimeoutTime_HU_Mid_X445" SG_ 495 CommunityHelpNotif 0;
BA_ "GenSigTimeoutMsg_IVI" SG_ 495 CommunityHelpNotif 0;
BA_ "GenSigTimeoutTime_IVI" SG_ 495 CommunityHelpNotif 0;
BA_ "GenSigTimeoutTime_HU_Mid_X451" SG_ 495 RemoteHornCmdStatus 0;
BA_ "GenSigTimeoutTime_HU_High_X451" SG_ 495 RemoteHornCmdStatus 0;
BA_ "GenSigTimeoutTime_HU_B" SG_ 495 RemoteHornCmdStatus 0;
BA_ "GenSigTimeoutTime_HU_A" SG_ 495 RemoteHornCmdStatus 0;
BA_ "GenSigTimeoutMsg_HU_Mid_X451" SG_ 495 RemoteHornCmdStatus 0;
BA_ "GenSigTimeoutMsg_HU_High_X451" SG_ 495 RemoteHornCmdStatus 0;
BA_ "GenSigTimeoutMsg_HU_B" SG_ 495 RemoteHornCmdStatus 0;
BA_ "GenSigTimeoutMsg_HU_A" SG_ 495 RemoteHornCmdStatus 0;
BA_ "GenSigStartValue" SG_ 495 RemoteHornCmdStatus 1;
BA_ "GenSigSendType" SG_ 495 RemoteHornCmdStatus 2;
BA_ "GenSigTimeoutMsg_HU_High_X445" SG_ 495 RemoteHornCmdStatus 0;
BA_ "GenSigTimeoutMsg_HU_Mid_X445" SG_ 495 RemoteHornCmdStatus 0;
BA_ "GenSigTimeoutTime_HU_High_X445" SG_ 495 RemoteHornCmdStatus 0;
BA_ "GenSigTimeoutTime_HU_Mid_X445" SG_ 495 RemoteHornCmdStatus 0;
BA_ "GenSigTimeoutMsg_IVI" SG_ 495 RemoteHornCmdStatus 0;
BA_ "GenSigTimeoutTime_IVI" SG_ 495 RemoteHornCmdStatus 0;
BA_ "GenSigTimeoutTime_HU_Mid_X451" SG_ 495 RemoteHornCmd 0;
BA_ "GenSigTimeoutTime_HU_High_X451" SG_ 495 RemoteHornCmd 0;
BA_ "GenSigTimeoutTime_HU_B" SG_ 495 RemoteHornCmd 0;
BA_ "GenSigTimeoutTime_HU_A" SG_ 495 RemoteHornCmd 0;
BA_ "GenSigTimeoutMsg_HU_Mid_X451" SG_ 495 RemoteHornCmd 0;
BA_ "GenSigTimeoutMsg_HU_High_X451" SG_ 495 RemoteHornCmd 0;
BA_ "GenSigTimeoutMsg_HU_B" SG_ 495 RemoteHornCmd 0;
BA_ "GenSigTimeoutMsg_HU_A" SG_ 495 RemoteHornCmd 0;
BA_ "GenSigSendType" SG_ 495 RemoteHornCmd 2;
BA_ "GenSigTimeoutMsg_HU_High_X445" SG_ 495 RemoteHornCmd 0;
BA_ "GenSigTimeoutMsg_HU_Mid_X445" SG_ 495 RemoteHornCmd 0;
BA_ "GenSigTimeoutTime_HU_High_X445" SG_ 495 RemoteHornCmd 0;
BA_ "GenSigTimeoutTime_HU_Mid_X445" SG_ 495 RemoteHornCmd 0;
BA_ "GenSigTimeoutMsg_IVI" SG_ 495 RemoteHornCmd 0;
BA_ "GenSigTimeoutTime_IVI" SG_ 495 RemoteHornCmd 0;
BA_ "GenSigTimeoutTime_HU_Mid_X451" SG_ 495 RemoteApprochLmpCmdStatus 0;
BA_ "GenSigTimeoutTime_HU_High_X451" SG_ 495 RemoteApprochLmpCmdStatus 0;
BA_ "GenSigTimeoutTime_HU_B" SG_ 495 RemoteApprochLmpCmdStatus 0;
BA_ "GenSigTimeoutTime_HU_A" SG_ 495 RemoteApprochLmpCmdStatus 0;
BA_ "GenSigTimeoutMsg_HU_Mid_X451" SG_ 495 RemoteApprochLmpCmdStatus 0;
BA_ "GenSigTimeoutMsg_HU_High_X451" SG_ 495 RemoteApprochLmpCmdStatus 0;
BA_ "GenSigTimeoutMsg_HU_B" SG_ 495 RemoteApprochLmpCmdStatus 0;
BA_ "GenSigTimeoutMsg_HU_A" SG_ 495 RemoteApprochLmpCmdStatus 0;
BA_ "GenSigStartValue" SG_ 495 RemoteApprochLmpCmdStatus 1;
BA_ "GenSigSendType" SG_ 495 RemoteApprochLmpCmdStatus 2;
BA_ "GenSigTimeoutMsg_HU_High_X445" SG_ 495 RemoteApprochLmpCmdStatus 0;
BA_ "GenSigTimeoutMsg_HU_Mid_X445" SG_ 495 RemoteApprochLmpCmdStatus 0;
BA_ "GenSigTimeoutTime_HU_High_X445" SG_ 495 RemoteApprochLmpCmdStatus 0;
BA_ "GenSigTimeoutTime_HU_Mid_X445" SG_ 495 RemoteApprochLmpCmdStatus 0;
BA_ "GenSigTimeoutMsg_IVI" SG_ 495 RemoteApprochLmpCmdStatus 0;
BA_ "GenSigTimeoutTime_IVI" SG_ 495 RemoteApprochLmpCmdStatus 0;
BA_ "GenSigTimeoutTime_HU_Mid_X451" SG_ 495 RemoteApprochLmpCmd 0;
BA_ "GenSigTimeoutTime_HU_High_X451" SG_ 495 RemoteApprochLmpCmd 0;
BA_ "GenSigTimeoutTime_HU_B" SG_ 495 RemoteApprochLmpCmd 0;
BA_ "GenSigTimeoutTime_HU_A" SG_ 495 RemoteApprochLmpCmd 0;
BA_ "GenSigTimeoutMsg_HU_Mid_X451" SG_ 495 RemoteApprochLmpCmd 0;
BA_ "GenSigTimeoutMsg_HU_High_X451" SG_ 495 RemoteApprochLmpCmd 0;
BA_ "GenSigTimeoutMsg_HU_B" SG_ 495 RemoteApprochLmpCmd 0;
BA_ "GenSigTimeoutMsg_HU_A" SG_ 495 RemoteApprochLmpCmd 0;
BA_ "GenSigSendType" SG_ 495 RemoteApprochLmpCmd 2;
BA_ "GenSigTimeoutMsg_HU_High_X445" SG_ 495 RemoteApprochLmpCmd 0;
BA_ "GenSigTimeoutMsg_HU_Mid_X445" SG_ 495 RemoteApprochLmpCmd 0;
BA_ "GenSigTimeoutTime_HU_High_X445" SG_ 495 RemoteApprochLmpCmd 0;
BA_ "GenSigTimeoutTime_HU_Mid_X445" SG_ 495 RemoteApprochLmpCmd 0;
BA_ "GenSigTimeoutMsg_IVI" SG_ 495 RemoteApprochLmpCmd 0;
BA_ "GenSigTimeoutTime_IVI" SG_ 495 RemoteApprochLmpCmd 0;
BA_ "GenSigTimeoutTime_HU_Mid_X451" SG_ 495 RemoteValetCmdStatus 0;
BA_ "GenSigTimeoutTime_HU_High_X451" SG_ 495 RemoteValetCmdStatus 0;
BA_ "GenSigTimeoutTime_HU_B" SG_ 495 RemoteValetCmdStatus 0;
BA_ "GenSigTimeoutTime_HU_A" SG_ 495 RemoteValetCmdStatus 0;
BA_ "GenSigTimeoutMsg_HU_Mid_X451" SG_ 495 RemoteValetCmdStatus 0;
BA_ "GenSigTimeoutMsg_HU_High_X451" SG_ 495 RemoteValetCmdStatus 0;
BA_ "GenSigTimeoutMsg_HU_B" SG_ 495 RemoteValetCmdStatus 0;
BA_ "GenSigTimeoutMsg_HU_A" SG_ 495 RemoteValetCmdStatus 0;
BA_ "GenSigStartValue" SG_ 495 RemoteValetCmdStatus 1;
BA_ "GenSigSendType" SG_ 495 RemoteValetCmdStatus 2;
BA_ "GenSigTimeoutMsg_HU_High_X445" SG_ 495 RemoteValetCmdStatus 0;
BA_ "GenSigTimeoutMsg_HU_Mid_X445" SG_ 495 RemoteValetCmdStatus 0;
BA_ "GenSigTimeoutTime_HU_High_X445" SG_ 495 RemoteValetCmdStatus 0;
BA_ "GenSigTimeoutTime_HU_Mid_X445" SG_ 495 RemoteValetCmdStatus 0;
BA_ "GenSigTimeoutMsg_IVI" SG_ 495 RemoteValetCmdStatus 0;
BA_ "GenSigTimeoutTime_IVI" SG_ 495 RemoteValetCmdStatus 0;
BA_ "GenSigTimeoutTime_HU_Mid_X451" SG_ 495 RemoteValetCmd 0;
BA_ "GenSigTimeoutTime_HU_High_X451" SG_ 495 RemoteValetCmd 0;
BA_ "GenSigTimeoutTime_HU_B" SG_ 495 RemoteValetCmd 0;
BA_ "GenSigTimeoutTime_HU_A" SG_ 495 RemoteValetCmd 0;
BA_ "GenSigTimeoutMsg_HU_Mid_X451" SG_ 495 RemoteValetCmd 0;
BA_ "GenSigTimeoutMsg_HU_High_X451" SG_ 495 RemoteValetCmd 0;
BA_ "GenSigTimeoutMsg_HU_B" SG_ 495 RemoteValetCmd 0;
BA_ "GenSigTimeoutMsg_HU_A" SG_ 495 RemoteValetCmd 0;
BA_ "GenSigSendType" SG_ 495 RemoteValetCmd 2;
BA_ "GenSigTimeoutMsg_HU_High_X445" SG_ 495 RemoteValetCmd 0;
BA_ "GenSigTimeoutMsg_HU_Mid_X445" SG_ 495 RemoteValetCmd 0;
BA_ "GenSigTimeoutTime_HU_High_X445" SG_ 495 RemoteValetCmd 0;
BA_ "GenSigTimeoutTime_HU_Mid_X445" SG_ 495 RemoteValetCmd 0;
BA_ "GenSigTimeoutMsg_IVI" SG_ 495 RemoteValetCmd 0;
BA_ "GenSigTimeoutTime_IVI" SG_ 495 RemoteValetCmd 0;
BA_ "GenSigTimeoutTime_HU_Mid_X451" SG_ 495 RemoteAcTempSetStatus 0;
BA_ "GenSigTimeoutTime_HU_High_X451" SG_ 495 RemoteAcTempSetStatus 0;
BA_ "GenSigTimeoutTime_HU_B" SG_ 495 RemoteAcTempSetStatus 0;
BA_ "GenSigTimeoutTime_HU_A" SG_ 495 RemoteAcTempSetStatus 0;
BA_ "GenSigTimeoutMsg_HU_Mid_X451" SG_ 495 RemoteAcTempSetStatus 0;
BA_ "GenSigTimeoutMsg_HU_High_X451" SG_ 495 RemoteAcTempSetStatus 0;
BA_ "GenSigTimeoutMsg_HU_B" SG_ 495 RemoteAcTempSetStatus 0;
BA_ "GenSigTimeoutMsg_HU_A" SG_ 495 RemoteAcTempSetStatus 0;
BA_ "GenSigStartValue" SG_ 495 RemoteAcTempSetStatus 1;
BA_ "GenSigSendType" SG_ 495 RemoteAcTempSetStatus 2;
BA_ "GenSigTimeoutMsg_HU_High_X445" SG_ 495 RemoteAcTempSetStatus 0;
BA_ "GenSigTimeoutMsg_HU_Mid_X445" SG_ 495 RemoteAcTempSetStatus 0;
BA_ "GenSigTimeoutTime_HU_High_X445" SG_ 495 RemoteAcTempSetStatus 0;
BA_ "GenSigTimeoutTime_HU_Mid_X445" SG_ 495 RemoteAcTempSetStatus 0;
BA_ "GenSigTimeoutMsg_IVI" SG_ 495 RemoteAcTempSetStatus 0;
BA_ "GenSigTimeoutTime_IVI" SG_ 495 RemoteAcTempSetStatus 0;
BA_ "GenSigTimeoutTime_HU_Mid_X451" SG_ 495 RemoteAcTempSet 0;
BA_ "GenSigTimeoutTime_HU_High_X451" SG_ 495 RemoteAcTempSet 0;
BA_ "GenSigTimeoutTime_HU_B" SG_ 495 RemoteAcTempSet 0;
BA_ "GenSigTimeoutTime_HU_A" SG_ 495 RemoteAcTempSet 0;
BA_ "GenSigTimeoutMsg_HU_Mid_X451" SG_ 495 RemoteAcTempSet 0;
BA_ "GenSigTimeoutMsg_HU_High_X451" SG_ 495 RemoteAcTempSet 0;
BA_ "GenSigTimeoutMsg_HU_B" SG_ 495 RemoteAcTempSet 0;
BA_ "GenSigTimeoutMsg_HU_A" SG_ 495 RemoteAcTempSet 0;
BA_ "GenSigStartValue" SG_ 495 RemoteAcTempSet 8;
BA_ "GenSigSendType" SG_ 495 RemoteAcTempSet 2;
BA_ "GenSigTimeoutMsg_HU_High_X445" SG_ 495 RemoteAcTempSet 0;
BA_ "GenSigTimeoutMsg_HU_Mid_X445" SG_ 495 RemoteAcTempSet 0;
BA_ "GenSigTimeoutTime_HU_High_X445" SG_ 495 RemoteAcTempSet 0;
BA_ "GenSigTimeoutTime_HU_Mid_X445" SG_ 495 RemoteAcTempSet 0;
BA_ "GenSigTimeoutMsg_IVI" SG_ 495 RemoteAcTempSet 0;
BA_ "GenSigTimeoutTime_IVI" SG_ 495 RemoteAcTempSet 0;
BA_ "GenSigTimeoutTime_HU_Mid_X451" SG_ 495 RemoteAcCmd 0;
BA_ "GenSigTimeoutTime_HU_High_X451" SG_ 495 RemoteAcCmd 0;
BA_ "GenSigTimeoutTime_HU_B" SG_ 495 RemoteAcCmd 0;
BA_ "GenSigTimeoutTime_HU_A" SG_ 495 RemoteAcCmd 0;
BA_ "GenSigTimeoutMsg_HU_Mid_X451" SG_ 495 RemoteAcCmd 0;
BA_ "GenSigTimeoutMsg_HU_High_X451" SG_ 495 RemoteAcCmd 0;
BA_ "GenSigTimeoutMsg_HU_B" SG_ 495 RemoteAcCmd 0;
BA_ "GenSigTimeoutMsg_HU_A" SG_ 495 RemoteAcCmd 0;
BA_ "GenSigSendType" SG_ 495 RemoteAcCmd 2;
BA_ "GenSigTimeoutMsg_HU_High_X445" SG_ 495 RemoteAcCmd 0;
BA_ "GenSigTimeoutMsg_HU_Mid_X445" SG_ 495 RemoteAcCmd 0;
BA_ "GenSigTimeoutTime_HU_High_X445" SG_ 495 RemoteAcCmd 0;
BA_ "GenSigTimeoutTime_HU_Mid_X445" SG_ 495 RemoteAcCmd 0;
BA_ "GenSigTimeoutMsg_IVI" SG_ 495 RemoteAcCmd 0;
BA_ "GenSigTimeoutTime_IVI" SG_ 495 RemoteAcCmd 0;
BA_ "GenSigTimeoutTime_HU_Mid_X451" SG_ 495 RemoteAcCmdStatus 0;
BA_ "GenSigTimeoutTime_HU_High_X451" SG_ 495 RemoteAcCmdStatus 0;
BA_ "GenSigTimeoutTime_HU_B" SG_ 495 RemoteAcCmdStatus 0;
BA_ "GenSigTimeoutTime_HU_A" SG_ 495 RemoteAcCmdStatus 0;
BA_ "GenSigTimeoutMsg_HU_Mid_X451" SG_ 495 RemoteAcCmdStatus 0;
BA_ "GenSigTimeoutMsg_HU_High_X451" SG_ 495 RemoteAcCmdStatus 0;
BA_ "GenSigTimeoutMsg_HU_B" SG_ 495 RemoteAcCmdStatus 0;
BA_ "GenSigTimeoutMsg_HU_A" SG_ 495 RemoteAcCmdStatus 0;
BA_ "GenSigStartValue" SG_ 495 RemoteAcCmdStatus 1;
BA_ "GenSigSendType" SG_ 495 RemoteAcCmdStatus 2;
BA_ "GenSigTimeoutMsg_HU_High_X445" SG_ 495 RemoteAcCmdStatus 0;
BA_ "GenSigTimeoutMsg_HU_Mid_X445" SG_ 495 RemoteAcCmdStatus 0;
BA_ "GenSigTimeoutTime_HU_High_X445" SG_ 495 RemoteAcCmdStatus 0;
BA_ "GenSigTimeoutTime_HU_Mid_X445" SG_ 495 RemoteAcCmdStatus 0;
BA_ "GenSigTimeoutMsg_IVI" SG_ 495 RemoteAcCmdStatus 0;
BA_ "GenSigTimeoutTime_IVI" SG_ 495 RemoteAcCmdStatus 0;
BA_ "GenSigTimeoutTime_HU_Mid_X451" SG_ 495 RemoteImmoReqStatus 0;
BA_ "GenSigTimeoutTime_HU_High_X451" SG_ 495 RemoteImmoReqStatus 0;
BA_ "GenSigTimeoutTime_HU_B" SG_ 495 RemoteImmoReqStatus 0;
BA_ "GenSigTimeoutTime_HU_A" SG_ 495 RemoteImmoReqStatus 0;
BA_ "GenSigTimeoutMsg_HU_Mid_X451" SG_ 495 RemoteImmoReqStatus 0;
BA_ "GenSigTimeoutMsg_HU_High_X451" SG_ 495 RemoteImmoReqStatus 0;
BA_ "GenSigTimeoutMsg_HU_B" SG_ 495 RemoteImmoReqStatus 0;
BA_ "GenSigTimeoutMsg_HU_A" SG_ 495 RemoteImmoReqStatus 0;
BA_ "GenSigStartValue" SG_ 495 RemoteImmoReqStatus 1;
BA_ "GenSigSendType" SG_ 495 RemoteImmoReqStatus 2;
BA_ "GenSigTimeoutMsg_HU_High_X445" SG_ 495 RemoteImmoReqStatus 0;
BA_ "GenSigTimeoutMsg_HU_Mid_X445" SG_ 495 RemoteImmoReqStatus 0;
BA_ "GenSigTimeoutTime_HU_High_X445" SG_ 495 RemoteImmoReqStatus 0;
BA_ "GenSigTimeoutTime_HU_Mid_X445" SG_ 495 RemoteImmoReqStatus 0;
BA_ "GenSigTimeoutMsg_IVI" SG_ 495 RemoteImmoReqStatus 0;
BA_ "GenSigTimeoutTime_IVI" SG_ 495 RemoteImmoReqStatus 0;
BA_ "GenSigTimeoutTime_HU_Mid_X451" SG_ 495 RemoteImmoReq 0;
BA_ "GenSigTimeoutTime_HU_High_X451" SG_ 495 RemoteImmoReq 0;
BA_ "GenSigTimeoutTime_HU_B" SG_ 495 RemoteImmoReq 0;
BA_ "GenSigTimeoutTime_HU_A" SG_ 495 RemoteImmoReq 0;
BA_ "GenSigTimeoutMsg_HU_Mid_X451" SG_ 495 RemoteImmoReq 0;
BA_ "GenSigTimeoutMsg_HU_High_X451" SG_ 495 RemoteImmoReq 0;
BA_ "GenSigTimeoutMsg_HU_B" SG_ 495 RemoteImmoReq 0;
BA_ "GenSigTimeoutMsg_HU_A" SG_ 495 RemoteImmoReq 0;
BA_ "GenSigSendType" SG_ 495 RemoteImmoReq 2;
BA_ "GenSigTimeoutMsg_HU_High_X445" SG_ 495 RemoteImmoReq 0;
BA_ "GenSigTimeoutMsg_HU_Mid_X445" SG_ 495 RemoteImmoReq 0;
BA_ "GenSigTimeoutTime_HU_High_X445" SG_ 495 RemoteImmoReq 0;
BA_ "GenSigTimeoutTime_HU_Mid_X445" SG_ 495 RemoteImmoReq 0;
BA_ "GenSigTimeoutMsg_IVI" SG_ 495 RemoteImmoReq 0;
BA_ "GenSigTimeoutTime_IVI" SG_ 495 RemoteImmoReq 0;
BA_ "GenSigTimeoutTime_HU_Mid_X451" SG_ 495 TowInfoStatus 0;
BA_ "GenSigTimeoutTime_HU_High_X451" SG_ 495 TowInfoStatus 0;
BA_ "GenSigTimeoutTime_HU_B" SG_ 495 TowInfoStatus 0;
BA_ "GenSigTimeoutTime_HU_A" SG_ 495 TowInfoStatus 0;
BA_ "GenSigTimeoutMsg_HU_Mid_X451" SG_ 495 TowInfoStatus 0;
BA_ "GenSigTimeoutMsg_HU_High_X451" SG_ 495 TowInfoStatus 0;
BA_ "GenSigTimeoutMsg_HU_B" SG_ 495 TowInfoStatus 0;
BA_ "GenSigTimeoutMsg_HU_A" SG_ 495 TowInfoStatus 0;
BA_ "GenSigStartValue" SG_ 495 TowInfoStatus 1;
BA_ "GenSigSendType" SG_ 495 TowInfoStatus 2;
BA_ "GenSigTimeoutMsg_HU_High_X445" SG_ 495 TowInfoStatus 0;
BA_ "GenSigTimeoutMsg_HU_Mid_X445" SG_ 495 TowInfoStatus 0;
BA_ "GenSigTimeoutTime_HU_High_X445" SG_ 495 TowInfoStatus 0;
BA_ "GenSigTimeoutTime_HU_Mid_X445" SG_ 495 TowInfoStatus 0;
BA_ "GenSigTimeoutMsg_IVI" SG_ 495 TowInfoStatus 0;
BA_ "GenSigTimeoutTime_IVI" SG_ 495 TowInfoStatus 0;
BA_ "GenSigTimeoutTime_HU_Mid_X451" SG_ 495 TowInfo 0;
BA_ "GenSigTimeoutTime_HU_High_X451" SG_ 495 TowInfo 0;
BA_ "GenSigTimeoutTime_HU_B" SG_ 495 TowInfo 0;
BA_ "GenSigTimeoutTime_HU_A" SG_ 495 TowInfo 0;
BA_ "GenSigTimeoutMsg_HU_Mid_X451" SG_ 495 TowInfo 0;
BA_ "GenSigTimeoutMsg_HU_High_X451" SG_ 495 TowInfo 0;
BA_ "GenSigTimeoutMsg_HU_B" SG_ 495 TowInfo 0;
BA_ "GenSigTimeoutMsg_HU_A" SG_ 495 TowInfo 0;
BA_ "GenSigSendType" SG_ 495 TowInfo 2;
BA_ "GenSigTimeoutMsg_HU_High_X445" SG_ 495 TowInfo 0;
BA_ "GenSigTimeoutMsg_HU_Mid_X445" SG_ 495 TowInfo 0;
BA_ "GenSigTimeoutTime_HU_High_X445" SG_ 495 TowInfo 0;
BA_ "GenSigTimeoutTime_HU_Mid_X445" SG_ 495 TowInfo 0;
BA_ "GenSigTimeoutMsg_IVI" SG_ 495 TowInfo 0;
BA_ "GenSigTimeoutTime_IVI" SG_ 495 TowInfo 0;
BA_ "GenSigTimeoutTime_HU_Mid_X451" SG_ 495 ParkingCollisionInfoStatus 0;
BA_ "GenSigTimeoutTime_HU_High_X451" SG_ 495 ParkingCollisionInfoStatus 0;
BA_ "GenSigTimeoutTime_HU_B" SG_ 495 ParkingCollisionInfoStatus 0;
BA_ "GenSigTimeoutTime_HU_A" SG_ 495 ParkingCollisionInfoStatus 0;
BA_ "GenSigTimeoutMsg_HU_Mid_X451" SG_ 495 ParkingCollisionInfoStatus 0;
BA_ "GenSigTimeoutMsg_HU_High_X451" SG_ 495 ParkingCollisionInfoStatus 0;
BA_ "GenSigTimeoutMsg_HU_B" SG_ 495 ParkingCollisionInfoStatus 0;
BA_ "GenSigTimeoutMsg_HU_A" SG_ 495 ParkingCollisionInfoStatus 0;
BA_ "GenSigStartValue" SG_ 495 ParkingCollisionInfoStatus 1;
BA_ "GenSigSendType" SG_ 495 ParkingCollisionInfoStatus 2;
BA_ "GenSigTimeoutMsg_HU_High_X445" SG_ 495 ParkingCollisionInfoStatus 0;
BA_ "GenSigTimeoutMsg_HU_Mid_X445" SG_ 495 ParkingCollisionInfoStatus 0;
BA_ "GenSigTimeoutTime_HU_High_X445" SG_ 495 ParkingCollisionInfoStatus 0;
BA_ "GenSigTimeoutTime_HU_Mid_X445" SG_ 495 ParkingCollisionInfoStatus 0;
BA_ "GenSigTimeoutMsg_IVI" SG_ 495 ParkingCollisionInfoStatus 0;
BA_ "GenSigTimeoutTime_IVI" SG_ 495 ParkingCollisionInfoStatus 0;
BA_ "GenSigTimeoutTime_HU_Mid_X451" SG_ 495 ParkingCollisionInfo 0;
BA_ "GenSigTimeoutTime_HU_High_X451" SG_ 495 ParkingCollisionInfo 0;
BA_ "GenSigTimeoutTime_HU_B" SG_ 495 ParkingCollisionInfo 0;
BA_ "GenSigTimeoutTime_HU_A" SG_ 495 ParkingCollisionInfo 0;
BA_ "GenSigTimeoutMsg_HU_Mid_X451" SG_ 495 ParkingCollisionInfo 0;
BA_ "GenSigTimeoutMsg_HU_High_X451" SG_ 495 ParkingCollisionInfo 0;
BA_ "GenSigTimeoutMsg_HU_B" SG_ 495 ParkingCollisionInfo 0;
BA_ "GenSigTimeoutMsg_HU_A" SG_ 495 ParkingCollisionInfo 0;
BA_ "GenSigSendType" SG_ 495 ParkingCollisionInfo 2;
BA_ "GenSigTimeoutMsg_HU_High_X445" SG_ 495 ParkingCollisionInfo 0;
BA_ "GenSigTimeoutMsg_HU_Mid_X445" SG_ 495 ParkingCollisionInfo 0;
BA_ "GenSigTimeoutTime_HU_High_X445" SG_ 495 ParkingCollisionInfo 0;
BA_ "GenSigTimeoutTime_HU_Mid_X445" SG_ 495 ParkingCollisionInfo 0;
BA_ "GenSigTimeoutMsg_IVI" SG_ 495 ParkingCollisionInfo 0;
BA_ "GenSigTimeoutTime_IVI" SG_ 495 ParkingCollisionInfo 0;
BA_ "GenSigTimeoutTime_HU_Mid_X451" SG_ 495 RemotePositionCmdStatus 0;
BA_ "GenSigTimeoutTime_HU_High_X451" SG_ 495 RemotePositionCmdStatus 0;
BA_ "GenSigTimeoutTime_HU_B" SG_ 495 RemotePositionCmdStatus 0;
BA_ "GenSigTimeoutTime_HU_A" SG_ 495 RemotePositionCmdStatus 0;
BA_ "GenSigTimeoutMsg_HU_Mid_X451" SG_ 495 RemotePositionCmdStatus 0;
BA_ "GenSigTimeoutMsg_HU_High_X451" SG_ 495 RemotePositionCmdStatus 0;
BA_ "GenSigTimeoutMsg_HU_B" SG_ 495 RemotePositionCmdStatus 0;
BA_ "GenSigTimeoutMsg_HU_A" SG_ 495 RemotePositionCmdStatus 0;
BA_ "GenSigStartValue" SG_ 495 RemotePositionCmdStatus 1;
BA_ "GenSigSendType" SG_ 495 RemotePositionCmdStatus 2;
BA_ "GenSigTimeoutMsg_HU_High_X445" SG_ 495 RemotePositionCmdStatus 0;
BA_ "GenSigTimeoutMsg_HU_Mid_X445" SG_ 495 RemotePositionCmdStatus 0;
BA_ "GenSigTimeoutTime_HU_High_X445" SG_ 495 RemotePositionCmdStatus 0;
BA_ "GenSigTimeoutTime_HU_Mid_X445" SG_ 495 RemotePositionCmdStatus 0;
BA_ "GenSigTimeoutMsg_IVI" SG_ 495 RemotePositionCmdStatus 0;
BA_ "GenSigTimeoutTime_IVI" SG_ 495 RemotePositionCmdStatus 0;
BA_ "GenSigTimeoutTime_HU_Mid_X451" SG_ 495 RemotePositionCmd 0;
BA_ "GenSigTimeoutTime_HU_High_X451" SG_ 495 RemotePositionCmd 0;
BA_ "GenSigTimeoutTime_HU_B" SG_ 495 RemotePositionCmd 0;
BA_ "GenSigTimeoutTime_HU_A" SG_ 495 RemotePositionCmd 0;
BA_ "GenSigTimeoutMsg_HU_Mid_X451" SG_ 495 RemotePositionCmd 0;
BA_ "GenSigTimeoutMsg_HU_High_X451" SG_ 495 RemotePositionCmd 0;
BA_ "GenSigTimeoutMsg_HU_B" SG_ 495 RemotePositionCmd 0;
BA_ "GenSigTimeoutMsg_HU_A" SG_ 495 RemotePositionCmd 0;
BA_ "GenSigSendType" SG_ 495 RemotePositionCmd 2;
BA_ "GenSigTimeoutMsg_HU_High_X445" SG_ 495 RemotePositionCmd 0;
BA_ "GenSigTimeoutMsg_HU_Mid_X445" SG_ 495 RemotePositionCmd 0;
BA_ "GenSigTimeoutTime_HU_High_X445" SG_ 495 RemotePositionCmd 0;
BA_ "GenSigTimeoutTime_HU_Mid_X445" SG_ 495 RemotePositionCmd 0;
BA_ "GenSigTimeoutMsg_IVI" SG_ 495 RemotePositionCmd 0;
BA_ "GenSigTimeoutTime_IVI" SG_ 495 RemotePositionCmd 0;
BA_ "GenSigTimeoutTime_HU_Mid_X451" SG_ 495 RemoteHazardCmdStatus 0;
BA_ "GenSigTimeoutTime_HU_High_X451" SG_ 495 RemoteHazardCmdStatus 0;
BA_ "GenSigTimeoutTime_HU_B" SG_ 495 RemoteHazardCmdStatus 0;
BA_ "GenSigTimeoutTime_HU_A" SG_ 495 RemoteHazardCmdStatus 0;
BA_ "GenSigTimeoutMsg_HU_Mid_X451" SG_ 495 RemoteHazardCmdStatus 0;
BA_ "GenSigTimeoutMsg_HU_High_X451" SG_ 495 RemoteHazardCmdStatus 0;
BA_ "GenSigTimeoutMsg_HU_B" SG_ 495 RemoteHazardCmdStatus 0;
BA_ "GenSigTimeoutMsg_HU_A" SG_ 495 RemoteHazardCmdStatus 0;
BA_ "GenSigStartValue" SG_ 495 RemoteHazardCmdStatus 1;
BA_ "GenSigSendType" SG_ 495 RemoteHazardCmdStatus 2;
BA_ "GenSigTimeoutMsg_HU_High_X445" SG_ 495 RemoteHazardCmdStatus 0;
BA_ "GenSigTimeoutMsg_HU_Mid_X445" SG_ 495 RemoteHazardCmdStatus 0;
BA_ "GenSigTimeoutTime_HU_High_X445" SG_ 495 RemoteHazardCmdStatus 0;
BA_ "GenSigTimeoutTime_HU_Mid_X445" SG_ 495 RemoteHazardCmdStatus 0;
BA_ "GenSigTimeoutMsg_IVI" SG_ 495 RemoteHazardCmdStatus 0;
BA_ "GenSigTimeoutTime_IVI" SG_ 495 RemoteHazardCmdStatus 0;
BA_ "GenSigTimeoutTime_HU_Mid_X451" SG_ 495 RemoteHazardCmd 0;
BA_ "GenSigTimeoutTime_HU_High_X451" SG_ 495 RemoteHazardCmd 0;
BA_ "GenSigTimeoutTime_HU_B" SG_ 495 RemoteHazardCmd 0;
BA_ "GenSigTimeoutTime_HU_A" SG_ 495 RemoteHazardCmd 0;
BA_ "GenSigTimeoutMsg_HU_Mid_X451" SG_ 495 RemoteHazardCmd 0;
BA_ "GenSigTimeoutMsg_HU_High_X451" SG_ 495 RemoteHazardCmd 0;
BA_ "GenSigTimeoutMsg_HU_B" SG_ 495 RemoteHazardCmd 0;
BA_ "GenSigTimeoutMsg_HU_A" SG_ 495 RemoteHazardCmd 0;
BA_ "GenSigSendType" SG_ 495 RemoteHazardCmd 2;
BA_ "GenSigTimeoutMsg_HU_High_X445" SG_ 495 RemoteHazardCmd 0;
BA_ "GenSigTimeoutMsg_HU_Mid_X445" SG_ 495 RemoteHazardCmd 0;
BA_ "GenSigTimeoutTime_HU_High_X445" SG_ 495 RemoteHazardCmd 0;
BA_ "GenSigTimeoutTime_HU_Mid_X445" SG_ 495 RemoteHazardCmd 0;
BA_ "GenSigTimeoutMsg_IVI" SG_ 495 RemoteHazardCmd 0;
BA_ "GenSigTimeoutTime_IVI" SG_ 495 RemoteHazardCmd 0;
BA_ "GenSigTimeoutTime_HU_Mid_X451" SG_ 495 RemoteVehicleUnlockCmdStatus 0;
BA_ "GenSigTimeoutTime_HU_High_X451" SG_ 495 RemoteVehicleUnlockCmdStatus 0;
BA_ "GenSigTimeoutTime_HU_B" SG_ 495 RemoteVehicleUnlockCmdStatus 0;
BA_ "GenSigTimeoutTime_HU_A" SG_ 495 RemoteVehicleUnlockCmdStatus 0;
BA_ "GenSigTimeoutMsg_HU_Mid_X451" SG_ 495 RemoteVehicleUnlockCmdStatus 0;
BA_ "GenSigTimeoutMsg_HU_High_X451" SG_ 495 RemoteVehicleUnlockCmdStatus 0;
BA_ "GenSigTimeoutMsg_HU_B" SG_ 495 RemoteVehicleUnlockCmdStatus 0;
BA_ "GenSigTimeoutMsg_HU_A" SG_ 495 RemoteVehicleUnlockCmdStatus 0;
BA_ "GenSigStartValue" SG_ 495 RemoteVehicleUnlockCmdStatus 1;
BA_ "GenSigSendType" SG_ 495 RemoteVehicleUnlockCmdStatus 2;
BA_ "GenSigTimeoutMsg_HU_High_X445" SG_ 495 RemoteVehicleUnlockCmdStatus 0;
BA_ "GenSigTimeoutMsg_HU_Mid_X445" SG_ 495 RemoteVehicleUnlockCmdStatus 0;
BA_ "GenSigTimeoutTime_HU_High_X445" SG_ 495 RemoteVehicleUnlockCmdStatus 0;
BA_ "GenSigTimeoutTime_HU_Mid_X445" SG_ 495 RemoteVehicleUnlockCmdStatus 0;
BA_ "GenSigTimeoutMsg_IVI" SG_ 495 RemoteVehicleUnlockCmdStatus 0;
BA_ "GenSigTimeoutTime_IVI" SG_ 495 RemoteVehicleUnlockCmdStatus 0;
BA_ "GenSigTimeoutTime_HU_Mid_X451" SG_ 495 RemoteVehicleUnlockCmd 0;
BA_ "GenSigTimeoutTime_HU_High_X451" SG_ 495 RemoteVehicleUnlockCmd 0;
BA_ "GenSigTimeoutTime_HU_B" SG_ 495 RemoteVehicleUnlockCmd 0;
BA_ "GenSigTimeoutTime_HU_A" SG_ 495 RemoteVehicleUnlockCmd 0;
BA_ "GenSigTimeoutMsg_HU_Mid_X451" SG_ 495 RemoteVehicleUnlockCmd 0;
BA_ "GenSigTimeoutMsg_HU_High_X451" SG_ 495 RemoteVehicleUnlockCmd 0;
BA_ "GenSigTimeoutMsg_HU_B" SG_ 495 RemoteVehicleUnlockCmd 0;
BA_ "GenSigTimeoutMsg_HU_A" SG_ 495 RemoteVehicleUnlockCmd 0;
BA_ "GenSigSendType" SG_ 495 RemoteVehicleUnlockCmd 2;
BA_ "GenSigTimeoutMsg_HU_High_X445" SG_ 495 RemoteVehicleUnlockCmd 0;
BA_ "GenSigTimeoutMsg_HU_Mid_X445" SG_ 495 RemoteVehicleUnlockCmd 0;
BA_ "GenSigTimeoutTime_HU_High_X445" SG_ 495 RemoteVehicleUnlockCmd 0;
BA_ "GenSigTimeoutTime_HU_Mid_X445" SG_ 495 RemoteVehicleUnlockCmd 0;
BA_ "GenSigTimeoutMsg_IVI" SG_ 495 RemoteVehicleUnlockCmd 0;
BA_ "GenSigTimeoutTime_IVI" SG_ 495 RemoteVehicleUnlockCmd 0;
BA_ "GenSigTimeoutTime_HU_Mid_X451" SG_ 495 RemoteVehicleLockCmdStatus 0;
BA_ "GenSigTimeoutTime_HU_High_X451" SG_ 495 RemoteVehicleLockCmdStatus 0;
BA_ "GenSigTimeoutTime_HU_B" SG_ 495 RemoteVehicleLockCmdStatus 0;
BA_ "GenSigTimeoutTime_HU_A" SG_ 495 RemoteVehicleLockCmdStatus 0;
BA_ "GenSigTimeoutMsg_HU_Mid_X451" SG_ 495 RemoteVehicleLockCmdStatus 0;
BA_ "GenSigTimeoutMsg_HU_High_X451" SG_ 495 RemoteVehicleLockCmdStatus 0;
BA_ "GenSigTimeoutMsg_HU_B" SG_ 495 RemoteVehicleLockCmdStatus 0;
BA_ "GenSigTimeoutMsg_HU_A" SG_ 495 RemoteVehicleLockCmdStatus 0;
BA_ "GenSigStartValue" SG_ 495 RemoteVehicleLockCmdStatus 1;
BA_ "GenSigSendType" SG_ 495 RemoteVehicleLockCmdStatus 2;
BA_ "GenSigTimeoutMsg_HU_High_X445" SG_ 495 RemoteVehicleLockCmdStatus 0;
BA_ "GenSigTimeoutMsg_HU_Mid_X445" SG_ 495 RemoteVehicleLockCmdStatus 0;
BA_ "GenSigTimeoutTime_HU_High_X445" SG_ 495 RemoteVehicleLockCmdStatus 0;
BA_ "GenSigTimeoutTime_HU_Mid_X445" SG_ 495 RemoteVehicleLockCmdStatus 0;
BA_ "GenSigTimeoutMsg_IVI" SG_ 495 RemoteVehicleLockCmdStatus 0;
BA_ "GenSigTimeoutTime_IVI" SG_ 495 RemoteVehicleLockCmdStatus 0;
BA_ "GenSigTimeoutTime_HU_Mid_X451" SG_ 495 RemoteVehicleLockCmd 0;
BA_ "GenSigTimeoutTime_HU_High_X451" SG_ 495 RemoteVehicleLockCmd 0;
BA_ "GenSigTimeoutTime_HU_B" SG_ 495 RemoteVehicleLockCmd 0;
BA_ "GenSigTimeoutTime_HU_A" SG_ 495 RemoteVehicleLockCmd 0;
BA_ "GenSigTimeoutMsg_HU_Mid_X451" SG_ 495 RemoteVehicleLockCmd 0;
BA_ "GenSigTimeoutMsg_HU_High_X451" SG_ 495 RemoteVehicleLockCmd 0;
BA_ "GenSigTimeoutMsg_HU_B" SG_ 495 RemoteVehicleLockCmd 0;
BA_ "GenSigTimeoutMsg_HU_A" SG_ 495 RemoteVehicleLockCmd 0;
BA_ "GenSigSendType" SG_ 495 RemoteVehicleLockCmd 2;
BA_ "GenSigTimeoutMsg_HU_High_X445" SG_ 495 RemoteVehicleLockCmd 0;
BA_ "GenSigTimeoutMsg_HU_Mid_X445" SG_ 495 RemoteVehicleLockCmd 0;
BA_ "GenSigTimeoutTime_HU_High_X445" SG_ 495 RemoteVehicleLockCmd 0;
BA_ "GenSigTimeoutTime_HU_Mid_X445" SG_ 495 RemoteVehicleLockCmd 0;
BA_ "GenSigTimeoutMsg_IVI" SG_ 495 RemoteVehicleLockCmd 0;
BA_ "GenSigTimeoutTime_IVI" SG_ 495 RemoteVehicleLockCmd 0;
BA_ "GenSigTimeoutTime_HU_Mid_X451" SG_ 1105 VCUMToFailureStatus 0;
BA_ "GenSigTimeoutTime_HU_High_X451" SG_ 1105 VCUMToFailureStatus 0;
BA_ "GenSigTimeoutTime_HU_B" SG_ 1105 VCUMToFailureStatus 0;
BA_ "GenSigTimeoutTime_HU_A" SG_ 1105 VCUMToFailureStatus 0;
BA_ "GenSigTimeoutMsg_HU_Mid_X451" SG_ 1105 VCUMToFailureStatus 0;
BA_ "GenSigTimeoutMsg_HU_High_X451" SG_ 1105 VCUMToFailureStatus 0;
BA_ "GenSigTimeoutMsg_HU_B" SG_ 1105 VCUMToFailureStatus 0;
BA_ "GenSigTimeoutMsg_HU_A" SG_ 1105 VCUMToFailureStatus 0;
BA_ "GenSigSendType" SG_ 1105 VCUMToFailureStatus 7;
BA_ "GenSigCycleTimeActive" SG_ 1105 VCUMToFailureStatus 100;
BA_ "GenSigCycleTime" SG_ 1105 VCUMToFailureStatus 100;
BA_ "GenSigTimeoutTime_HU_Mid_X451" SG_ 1105 VCUInvalidFailureStatus 0;
BA_ "GenSigTimeoutTime_HU_High_X451" SG_ 1105 VCUInvalidFailureStatus 0;
BA_ "GenSigTimeoutTime_HU_B" SG_ 1105 VCUInvalidFailureStatus 0;
BA_ "GenSigTimeoutTime_HU_A" SG_ 1105 VCUInvalidFailureStatus 0;
BA_ "GenSigTimeoutMsg_HU_Mid_X451" SG_ 1105 VCUInvalidFailureStatus 0;
BA_ "GenSigTimeoutMsg_HU_High_X451" SG_ 1105 VCUInvalidFailureStatus 0;
BA_ "GenSigTimeoutMsg_HU_B" SG_ 1105 VCUInvalidFailureStatus 0;
BA_ "GenSigTimeoutMsg_HU_A" SG_ 1105 VCUInvalidFailureStatus 0;
BA_ "GenSigSendType" SG_ 1105 VCUInvalidFailureStatus 7;
BA_ "GenSigCycleTimeActive" SG_ 1105 VCUInvalidFailureStatus 100;
BA_ "GenSigCycleTime" SG_ 1105 VCUInvalidFailureStatus 100;
BA_ "GenSigTimeoutTime_HU_Mid_X451" SG_ 1105 IPcMToFailureStatus 0;
BA_ "GenSigTimeoutTime_HU_High_X451" SG_ 1105 IPcMToFailureStatus 0;
BA_ "GenSigTimeoutTime_HU_B" SG_ 1105 IPcMToFailureStatus 0;
BA_ "GenSigTimeoutTime_HU_A" SG_ 1105 IPcMToFailureStatus 0;
BA_ "GenSigTimeoutMsg_HU_Mid_X451" SG_ 1105 IPcMToFailureStatus 0;
BA_ "GenSigTimeoutMsg_HU_High_X451" SG_ 1105 IPcMToFailureStatus 0;
BA_ "GenSigTimeoutMsg_HU_B" SG_ 1105 IPcMToFailureStatus 0;
BA_ "GenSigTimeoutMsg_HU_A" SG_ 1105 IPcMToFailureStatus 0;
BA_ "GenSigSendType" SG_ 1105 IPcMToFailureStatus 7;
BA_ "GenSigCycleTimeActive" SG_ 1105 IPcMToFailureStatus 100;
BA_ "GenSigCycleTime" SG_ 1105 IPcMToFailureStatus 100;
BA_ "GenSigTimeoutTime_HU_Mid_X451" SG_ 1105 IPcInvalidFailureStatus 0;
BA_ "GenSigTimeoutTime_HU_High_X451" SG_ 1105 IPcInvalidFailureStatus 0;
BA_ "GenSigTimeoutTime_HU_B" SG_ 1105 IPcInvalidFailureStatus 0;
BA_ "GenSigTimeoutTime_HU_A" SG_ 1105 IPcInvalidFailureStatus 0;
BA_ "GenSigTimeoutMsg_HU_Mid_X451" SG_ 1105 IPcInvalidFailureStatus 0;
BA_ "GenSigTimeoutMsg_HU_High_X451" SG_ 1105 IPcInvalidFailureStatus 0;
BA_ "GenSigTimeoutMsg_HU_B" SG_ 1105 IPcInvalidFailureStatus 0;
BA_ "GenSigTimeoutMsg_HU_A" SG_ 1105 IPcInvalidFailureStatus 0;
BA_ "GenSigSendType" SG_ 1105 IPcInvalidFailureStatus 7;
BA_ "GenSigCycleTimeActive" SG_ 1105 IPcInvalidFailureStatus 100;
BA_ "GenSigCycleTime" SG_ 1105 IPcInvalidFailureStatus 100;
BA_ "GenSigTimeoutTime_HU_Mid_X451" SG_ 1105 GSS_EV_SW_Ver 0;
BA_ "GenSigTimeoutTime_HU_High_X451" SG_ 1105 GSS_EV_SW_Ver 0;
BA_ "GenSigTimeoutTime_HU_B" SG_ 1105 GSS_EV_SW_Ver 0;
BA_ "GenSigTimeoutTime_HU_A" SG_ 1105 GSS_EV_SW_Ver 0;
BA_ "GenSigTimeoutMsg_HU_Mid_X451" SG_ 1105 GSS_EV_SW_Ver 0;
BA_ "GenSigTimeoutMsg_HU_High_X451" SG_ 1105 GSS_EV_SW_Ver 0;
BA_ "GenSigTimeoutMsg_HU_B" SG_ 1105 GSS_EV_SW_Ver 0;
BA_ "GenSigTimeoutMsg_HU_A" SG_ 1105 GSS_EV_SW_Ver 0;
BA_ "GenSigSendType" SG_ 1105 GSS_EV_SW_Ver 7;
BA_ "GenSigCycleTimeActive" SG_ 1105 GSS_EV_SW_Ver 100;
BA_ "GenSigCycleTime" SG_ 1105 GSS_EV_SW_Ver 100;
BA_ "GenSigTimeoutTime_HU_Mid_X451" SG_ 1105 GSS_EV_HW_Ver 0;
BA_ "GenSigTimeoutTime_HU_High_X451" SG_ 1105 GSS_EV_HW_Ver 0;
BA_ "GenSigTimeoutTime_HU_B" SG_ 1105 GSS_EV_HW_Ver 0;
BA_ "GenSigTimeoutTime_HU_A" SG_ 1105 GSS_EV_HW_Ver 0;
BA_ "GenSigTimeoutMsg_HU_Mid_X451" SG_ 1105 GSS_EV_HW_Ver 0;
BA_ "GenSigTimeoutMsg_HU_High_X451" SG_ 1105 GSS_EV_HW_Ver 0;
BA_ "GenSigTimeoutMsg_HU_B" SG_ 1105 GSS_EV_HW_Ver 0;
BA_ "GenSigTimeoutMsg_HU_A" SG_ 1105 GSS_EV_HW_Ver 0;
BA_ "GenSigSendType" SG_ 1105 GSS_EV_HW_Ver 7;
BA_ "GenSigCycleTimeActive" SG_ 1105 GSS_EV_HW_Ver 100;
BA_ "GenSigCycleTime" SG_ 1105 GSS_EV_HW_Ver 100;
BA_ "GenSigTimeoutTime_HU_Mid_X451" SG_ 1105 GSS_EV_Err_State_Trans_Cntr 0;
BA_ "GenSigTimeoutTime_HU_High_X451" SG_ 1105 GSS_EV_Err_State_Trans_Cntr 0;
BA_ "GenSigTimeoutTime_HU_B" SG_ 1105 GSS_EV_Err_State_Trans_Cntr 0;
BA_ "GenSigTimeoutTime_HU_A" SG_ 1105 GSS_EV_Err_State_Trans_Cntr 0;
BA_ "GenSigTimeoutMsg_HU_Mid_X451" SG_ 1105 GSS_EV_Err_State_Trans_Cntr 0;
BA_ "GenSigTimeoutMsg_HU_High_X451" SG_ 1105 GSS_EV_Err_State_Trans_Cntr 0;
BA_ "GenSigTimeoutMsg_HU_B" SG_ 1105 GSS_EV_Err_State_Trans_Cntr 0;
BA_ "GenSigTimeoutMsg_HU_A" SG_ 1105 GSS_EV_Err_State_Trans_Cntr 0;
BA_ "GenSigSendType" SG_ 1105 GSS_EV_Err_State_Trans_Cntr 7;
BA_ "GenSigCycleTimeActive" SG_ 1105 GSS_EV_Err_State_Trans_Cntr 100;
BA_ "GenSigCycleTime" SG_ 1105 GSS_EV_Err_State_Trans_Cntr 100;
BA_ "GenSigTimeoutTime_HU_Mid_X451" SG_ 1105 GSS_EV_EP_Failure_Status 0;
BA_ "GenSigTimeoutTime_HU_High_X451" SG_ 1105 GSS_EV_EP_Failure_Status 0;
BA_ "GenSigTimeoutTime_HU_B" SG_ 1105 GSS_EV_EP_Failure_Status 0;
BA_ "GenSigTimeoutTime_HU_A" SG_ 1105 GSS_EV_EP_Failure_Status 0;
BA_ "GenSigTimeoutMsg_HU_Mid_X451" SG_ 1105 GSS_EV_EP_Failure_Status 0;
BA_ "GenSigTimeoutMsg_HU_High_X451" SG_ 1105 GSS_EV_EP_Failure_Status 0;
BA_ "GenSigTimeoutMsg_HU_B" SG_ 1105 GSS_EV_EP_Failure_Status 0;
BA_ "GenSigTimeoutMsg_HU_A" SG_ 1105 GSS_EV_EP_Failure_Status 0;
BA_ "GenSigSendType" SG_ 1105 GSS_EV_EP_Failure_Status 7;
BA_ "GenSigCycleTimeActive" SG_ 1105 GSS_EV_EP_Failure_Status 100;
BA_ "GenSigCycleTime" SG_ 1105 GSS_EV_EP_Failure_Status 100;
BA_ "GenSigTimeoutTime_HU_Mid_X451" SG_ 1105 GSS_EV_BO_Failure_Status 0;
BA_ "GenSigTimeoutTime_HU_High_X451" SG_ 1105 GSS_EV_BO_Failure_Status 0;
BA_ "GenSigTimeoutTime_HU_B" SG_ 1105 GSS_EV_BO_Failure_Status 0;
BA_ "GenSigTimeoutTime_HU_A" SG_ 1105 GSS_EV_BO_Failure_Status 0;
BA_ "GenSigTimeoutMsg_HU_Mid_X451" SG_ 1105 GSS_EV_BO_Failure_Status 0;
BA_ "GenSigTimeoutMsg_HU_High_X451" SG_ 1105 GSS_EV_BO_Failure_Status 0;
BA_ "GenSigTimeoutMsg_HU_B" SG_ 1105 GSS_EV_BO_Failure_Status 0;
BA_ "GenSigTimeoutMsg_HU_A" SG_ 1105 GSS_EV_BO_Failure_Status 0;
BA_ "GenSigSendType" SG_ 1105 GSS_EV_BO_Failure_Status 7;
BA_ "GenSigCycleTimeActive" SG_ 1105 GSS_EV_BO_Failure_Status 100;
BA_ "GenSigCycleTime" SG_ 1105 GSS_EV_BO_Failure_Status 100;
BA_ "GenSigTimeoutTime_HU_B" SG_ 1105 BCM_MTO_Failure_status 0;
BA_ "GenSigTimeoutTime_HU_A" SG_ 1105 BCM_MTO_Failure_status 0;
BA_ "GenSigTimeoutMsg_HU_B" SG_ 1105 BCM_MTO_Failure_status 0;
BA_ "GenSigTimeoutMsg_HU_A" SG_ 1105 BCM_MTO_Failure_status 0;
BA_ "GenSigSendType" SG_ 1105 BCM_MTO_Failure_status 7;
BA_ "GenSigCycleTimeActive" SG_ 1105 BCM_MTO_Failure_status 100;
BA_ "GenSigCycleTime" SG_ 1105 BCM_MTO_Failure_status 100;
BA_ "GenSigTimeoutTime_HU_Mid_X451" SG_ 1105 BCM_Invalid_Status_Failure 0;
BA_ "GenSigTimeoutTime_HU_High_X451" SG_ 1105 BCM_Invalid_Status_Failure 0;
BA_ "GenSigTimeoutTime_HU_B" SG_ 1105 BCM_Invalid_Status_Failure 0;
BA_ "GenSigTimeoutTime_HU_A" SG_ 1105 BCM_Invalid_Status_Failure 0;
BA_ "GenSigTimeoutMsg_HU_Mid_X451" SG_ 1105 BCM_Invalid_Status_Failure 0;
BA_ "GenSigTimeoutMsg_HU_High_X451" SG_ 1105 BCM_Invalid_Status_Failure 0;
BA_ "GenSigTimeoutMsg_HU_B" SG_ 1105 BCM_Invalid_Status_Failure 0;
BA_ "GenSigTimeoutMsg_HU_A" SG_ 1105 BCM_Invalid_Status_Failure 0;
BA_ "GenSigSendType" SG_ 1105 BCM_Invalid_Status_Failure 7;
BA_ "GenSigCycleTimeActive" SG_ 1105 BCM_Invalid_Status_Failure 100;
BA_ "GenSigCycleTime" SG_ 1105 BCM_Invalid_Status_Failure 100;
BA_ "GenSigTimeoutTime_HU_Mid_X451" SG_ 1105 BattVolt_GSS_EV 0;
BA_ "GenSigTimeoutTime_HU_High_X451" SG_ 1105 BattVolt_GSS_EV 0;
BA_ "GenSigTimeoutTime_HU_B" SG_ 1105 BattVolt_GSS_EV 0;
BA_ "GenSigTimeoutTime_HU_A" SG_ 1105 BattVolt_GSS_EV 0;
BA_ "GenSigTimeoutMsg_HU_Mid_X451" SG_ 1105 BattVolt_GSS_EV 0;
BA_ "GenSigTimeoutMsg_HU_High_X451" SG_ 1105 BattVolt_GSS_EV 0;
BA_ "GenSigTimeoutMsg_HU_B" SG_ 1105 BattVolt_GSS_EV 0;
BA_ "GenSigTimeoutMsg_HU_A" SG_ 1105 BattVolt_GSS_EV 0;
BA_ "GenSigSendType" SG_ 1105 BattVolt_GSS_EV 7;
BA_ "GenSigCycleTimeActive" SG_ 1105 BattVolt_GSS_EV 100;
BA_ "GenSigCycleTime" SG_ 1105 BattVolt_GSS_EV 100;
BA_ "GenSigSendType" SG_ 617 GSSGearSelectionDorStatus 7;
BA_ "GenSigCycleTimeActive" SG_ 617 GSSGearSelectionDorStatus 100;
BA_ "GenSigCycleTime" SG_ 617 GSSGearSelectionDorStatus 100;
BA_ "GenSigTimeoutMsg_HU_B" SG_ 617 GSSGearSelectionDor 0;
BA_ "GenSigTimeoutMsg_HU_A" SG_ 617 GSSGearSelectionDor 0;
BA_ "GenSigSendType" SG_ 617 GSSGearSelectionDor 7;
BA_ "GenSigCycleTimeActive" SG_ 617 GSSGearSelectionDor 100;
BA_ "GenSigCycleTime" SG_ 617 GSSGearSelectionDor 100;
BA_ "GenSigTimeoutTime_HU_Mid_X451" SG_ 617 GearSelectionSwStateStatus 0;
BA_ "GenSigTimeoutTime_HU_High_X451" SG_ 617 GearSelectionSwStateStatus 0;
BA_ "GenSigTimeoutTime_HU_B" SG_ 617 GearSelectionSwStateStatus 0;
BA_ "GenSigTimeoutTime_HU_A" SG_ 617 GearSelectionSwStateStatus 0;
BA_ "GenSigTimeoutMsg_HU_Mid_X451" SG_ 617 GearSelectionSwStateStatus 0;
BA_ "GenSigTimeoutMsg_HU_High_X451" SG_ 617 GearSelectionSwStateStatus 0;
BA_ "GenSigTimeoutMsg_HU_B" SG_ 617 GearSelectionSwStateStatus 0;
BA_ "GenSigTimeoutMsg_HU_A" SG_ 617 GearSelectionSwStateStatus 0;
BA_ "GenSigSendType" SG_ 617 GearSelectionSwStateStatus 7;
BA_ "GenSigCycleTimeActive" SG_ 617 GearSelectionSwStateStatus 100;
BA_ "GenSigCycleTime" SG_ 617 GearSelectionSwStateStatus 100;
BA_ "GenSigTimeoutTime_HU_Mid_X451" SG_ 617 GearSelectionSwState 0;
BA_ "GenSigTimeoutTime_HU_High_X451" SG_ 617 GearSelectionSwState 0;
BA_ "GenSigTimeoutTime_HU_B" SG_ 617 GearSelectionSwState 0;
BA_ "GenSigTimeoutTime_HU_A" SG_ 617 GearSelectionSwState 0;
BA_ "GenSigTimeoutMsg_HU_Mid_X451" SG_ 617 GearSelectionSwState 0;
BA_ "GenSigTimeoutMsg_HU_High_X451" SG_ 617 GearSelectionSwState 0;
BA_ "GenSigTimeoutMsg_HU_B" SG_ 617 GearSelectionSwState 0;
BA_ "GenSigTimeoutMsg_HU_A" SG_ 617 GearSelectionSwState 0;
BA_ "GenSigStartValue" SG_ 617 GearSelectionSwState 4;
BA_ "GenSigSendType" SG_ 617 GearSelectionSwState 7;
BA_ "GenSigCycleTimeActive" SG_ 617 GearSelectionSwState 100;
BA_ "GenSigCycleTime" SG_ 617 GearSelectionSwState 100;
BA_ "GenSigTimeoutTime_HU_Mid_X451" SG_ 617 GSSGearSelectionChangeTxt 0;
BA_ "GenSigTimeoutTime_HU_High_X451" SG_ 617 GSSGearSelectionChangeTxt 0;
BA_ "GenSigTimeoutTime_HU_B" SG_ 617 GSSGearSelectionChangeTxt 0;
BA_ "GenSigTimeoutTime_HU_A" SG_ 617 GSSGearSelectionChangeTxt 0;
BA_ "GenSigTimeoutMsg_HU_Mid_X451" SG_ 617 GSSGearSelectionChangeTxt 0;
BA_ "GenSigTimeoutMsg_HU_High_X451" SG_ 617 GSSGearSelectionChangeTxt 0;
BA_ "GenSigTimeoutMsg_HU_B" SG_ 617 GSSGearSelectionChangeTxt 0;
BA_ "GenSigTimeoutMsg_HU_A" SG_ 617 GSSGearSelectionChangeTxt 0;
BA_ "GenSigSendType" SG_ 617 GSSGearSelectionChangeTxt 7;
BA_ "GenSigCycleTimeActive" SG_ 617 GSSGearSelectionChangeTxt 100;
BA_ "GenSigCycleTime" SG_ 617 GSSGearSelectionChangeTxt 100;
BA_ "GenSigTimeoutTime_HU_Mid_X451" SG_ 617 GSSFailureStatusSignal 0;
BA_ "GenSigTimeoutTime_HU_High_X451" SG_ 617 GSSFailureStatusSignal 0;
BA_ "GenSigTimeoutTime_HU_B" SG_ 617 GSSFailureStatusSignal 0;
BA_ "GenSigTimeoutTime_HU_A" SG_ 617 GSSFailureStatusSignal 0;
BA_ "GenSigTimeoutMsg_HU_Mid_X451" SG_ 617 GSSFailureStatusSignal 0;
BA_ "GenSigTimeoutMsg_HU_High_X451" SG_ 617 GSSFailureStatusSignal 0;
BA_ "GenSigTimeoutMsg_HU_B" SG_ 617 GSSFailureStatusSignal 0;
BA_ "GenSigTimeoutMsg_HU_A" SG_ 617 GSSFailureStatusSignal 0;
BA_ "GenSigSendType" SG_ 617 GSSFailureStatusSignal 7;
BA_ "GenSigCycleTimeActive" SG_ 617 GSSFailureStatusSignal 100;
BA_ "GenSigCycleTime" SG_ 617 GSSFailureStatusSignal 100;
BA_ "GenSigTimeoutTime_HU_Mid_X451" SG_ 580 BrakePaddlePosVcuStatus 0;
BA_ "GenSigTimeoutTime_HU_High_X451" SG_ 580 BrakePaddlePosVcuStatus 0;
BA_ "GenSigTimeoutTime_HU_B" SG_ 580 BrakePaddlePosVcuStatus 0;
BA_ "GenSigTimeoutTime_HU_A" SG_ 580 BrakePaddlePosVcuStatus 0;
BA_ "GenSigTimeoutMsg_HU_Mid_X451" SG_ 580 BrakePaddlePosVcuStatus 0;
BA_ "GenSigTimeoutMsg_HU_High_X451" SG_ 580 BrakePaddlePosVcuStatus 0;
BA_ "GenSigTimeoutMsg_HU_B" SG_ 580 BrakePaddlePosVcuStatus 0;
BA_ "GenSigTimeoutMsg_HU_A" SG_ 580 BrakePaddlePosVcuStatus 0;
BA_ "GenSigSendType" SG_ 580 BrakePaddlePosVcuStatus 7;
BA_ "GenSigCycleTimeActive" SG_ 580 BrakePaddlePosVcuStatus 100;
BA_ "GenSigCycleTime" SG_ 580 BrakePaddlePosVcuStatus 100;
BA_ "GenSigTimeoutMsg_HU_High_X445" SG_ 580 BrakePaddlePosVcuStatus 0;
BA_ "GenSigTimeoutMsg_HU_Mid_X445" SG_ 580 BrakePaddlePosVcuStatus 0;
BA_ "GenSigTimeoutTime_HU_High_X445" SG_ 580 BrakePaddlePosVcuStatus 0;
BA_ "GenSigTimeoutTime_HU_Mid_X445" SG_ 580 BrakePaddlePosVcuStatus 0;
BA_ "GenSigTimeoutTime_HU_Mid_X451" SG_ 580 BrakePaddlePosVcu 0;
BA_ "GenSigTimeoutTime_HU_High_X451" SG_ 580 BrakePaddlePosVcu 0;
BA_ "GenSigTimeoutTime_HU_B" SG_ 580 BrakePaddlePosVcu 0;
BA_ "GenSigTimeoutTime_HU_A" SG_ 580 BrakePaddlePosVcu 0;
BA_ "GenSigTimeoutMsg_HU_Mid_X451" SG_ 580 BrakePaddlePosVcu 0;
BA_ "GenSigTimeoutMsg_HU_High_X451" SG_ 580 BrakePaddlePosVcu 0;
BA_ "GenSigTimeoutMsg_HU_B" SG_ 580 BrakePaddlePosVcu 0;
BA_ "GenSigTimeoutMsg_HU_A" SG_ 580 BrakePaddlePosVcu 0;
BA_ "GenSigSendType" SG_ 580 BrakePaddlePosVcu 7;
BA_ "GenSigCycleTimeActive" SG_ 580 BrakePaddlePosVcu 100;
BA_ "GenSigCycleTime" SG_ 580 BrakePaddlePosVcu 100;
BA_ "GenSigTimeoutMsg_HU_High_X445" SG_ 580 BrakePaddlePosVcu 0;
BA_ "GenSigTimeoutMsg_HU_Mid_X445" SG_ 580 BrakePaddlePosVcu 0;
BA_ "GenSigTimeoutTime_HU_High_X445" SG_ 580 BrakePaddlePosVcu 0;
BA_ "GenSigTimeoutTime_HU_Mid_X445" SG_ 580 BrakePaddlePosVcu 0;
BA_ "GenSigSendType" SG_ 580 HVBattSoCPercenStatus 7;
BA_ "GenSigCycleTimeActive" SG_ 580 HVBattSoCPercenStatus 100;
BA_ "GenSigCycleTime" SG_ 580 HVBattSoCPercenStatus 100;
BA_ "GenSigSendType" SG_ 580 HVBattSoCPercen 7;
BA_ "GenSigCycleTimeActive" SG_ 580 HVBattSoCPercen 100;
BA_ "GenSigCycleTime" SG_ 580 HVBattSoCPercen 100;
BA_ "GenSigSendType" SG_ 580 DTeInfoStatus 7;
BA_ "GenSigCycleTimeActive" SG_ 580 DTeInfoStatus 100;
BA_ "GenSigCycleTime" SG_ 580 DTeInfoStatus 100;
BA_ "GenSigSendType" SG_ 580 DTeInfo 7;
BA_ "GenSigCycleTimeActive" SG_ 580 DTeInfo 100;
BA_ "GenSigCycleTime" SG_ 580 DTeInfo 100;
BA_ "GenSigTimeoutTime_HU_Mid_X451" SG_ 580 VehicleStatus 0;
BA_ "GenSigTimeoutTime_HU_High_X451" SG_ 580 VehicleStatus 0;
BA_ "GenSigTimeoutTime_HU_B" SG_ 580 VehicleStatus 0;
BA_ "GenSigTimeoutTime_HU_A" SG_ 580 VehicleStatus 0;
BA_ "GenSigTimeoutMsg_HU_Mid_X451" SG_ 580 VehicleStatus 0;
BA_ "GenSigTimeoutMsg_HU_High_X451" SG_ 580 VehicleStatus 0;
BA_ "GenSigTimeoutMsg_HU_B" SG_ 580 VehicleStatus 0;
BA_ "GenSigTimeoutMsg_HU_A" SG_ 580 VehicleStatus 0;
BA_ "GenSigSendType" SG_ 580 VehicleStatus 7;
BA_ "GenSigCycleTimeActive" SG_ 580 VehicleStatus 100;
BA_ "GenSigCycleTime" SG_ 580 VehicleStatus 100;
BA_ "GenSigSendType" SG_ 580 VcuStatus 7;
BA_ "GenSigCycleTimeActive" SG_ 580 VcuStatus 100;
BA_ "GenSigCycleTime" SG_ 580 VcuStatus 100;
BA_ "GenSigTimeoutTime_HU_Mid_X451" SG_ 580 ValetStateStatus 0;
BA_ "GenSigTimeoutTime_HU_High_X451" SG_ 580 ValetStateStatus 0;
BA_ "GenSigTimeoutTime_HU_B" SG_ 580 ValetStateStatus 0;
BA_ "GenSigTimeoutTime_HU_A" SG_ 580 ValetStateStatus 0;
BA_ "GenSigTimeoutMsg_HU_Mid_X451" SG_ 580 ValetStateStatus 0;
BA_ "GenSigTimeoutMsg_HU_High_X451" SG_ 580 ValetStateStatus 0;
BA_ "GenSigTimeoutMsg_HU_B" SG_ 580 ValetStateStatus 0;
BA_ "GenSigTimeoutMsg_HU_A" SG_ 580 ValetStateStatus 0;
BA_ "GenSigSendType" SG_ 580 ValetStateStatus 7;
BA_ "GenSigCycleTimeActive" SG_ 580 ValetStateStatus 100;
BA_ "GenSigCycleTime" SG_ 580 ValetStateStatus 100;
BA_ "GenSigTimeoutMsg_HU_High_X445" SG_ 580 ValetStateStatus 0;
BA_ "GenSigTimeoutMsg_HU_Mid_X445" SG_ 580 ValetStateStatus 0;
BA_ "GenSigTimeoutTime_HU_High_X445" SG_ 580 ValetStateStatus 0;
BA_ "GenSigTimeoutTime_HU_Mid_X445" SG_ 580 ValetStateStatus 0;
BA_ "GenSigTimeoutTime_HU_Mid_X451" SG_ 580 ValetState 0;
BA_ "GenSigTimeoutTime_HU_High_X451" SG_ 580 ValetState 0;
BA_ "GenSigTimeoutTime_HU_B" SG_ 580 ValetState 0;
BA_ "GenSigTimeoutTime_HU_A" SG_ 580 ValetState 0;
BA_ "GenSigTimeoutMsg_HU_Mid_X451" SG_ 580 ValetState 0;
BA_ "GenSigTimeoutMsg_HU_High_X451" SG_ 580 ValetState 0;
BA_ "GenSigTimeoutMsg_HU_B" SG_ 580 ValetState 0;
BA_ "GenSigTimeoutMsg_HU_A" SG_ 580 ValetState 0;
BA_ "GenSigSendType" SG_ 580 ValetState 7;
BA_ "GenSigCycleTimeActive" SG_ 580 ValetState 100;
BA_ "GenSigCycleTime" SG_ 580 ValetState 100;
BA_ "GenSigTimeoutMsg_HU_High_X445" SG_ 580 ValetState 0;
BA_ "GenSigTimeoutMsg_HU_Mid_X445" SG_ 580 ValetState 0;
BA_ "GenSigTimeoutTime_HU_High_X445" SG_ 580 ValetState 0;
BA_ "GenSigTimeoutTime_HU_Mid_X445" SG_ 580 ValetState 0;
BA_ "GenSigTimeoutTime_HU_Mid_X451" SG_ 580 AcComprMalFn 0;
BA_ "GenSigTimeoutTime_HU_High_X451" SG_ 580 AcComprMalFn 0;
BA_ "GenSigTimeoutTime_HU_B" SG_ 580 AcComprMalFn 0;
BA_ "GenSigTimeoutTime_HU_A" SG_ 580 AcComprMalFn 0;
BA_ "GenSigTimeoutMsg_HU_Mid_X451" SG_ 580 AcComprMalFn 0;
BA_ "GenSigTimeoutMsg_HU_High_X451" SG_ 580 AcComprMalFn 0;
BA_ "GenSigTimeoutMsg_HU_B" SG_ 580 AcComprMalFn 0;
BA_ "GenSigTimeoutMsg_HU_A" SG_ 580 AcComprMalFn 0;
BA_ "GenSigSendType" SG_ 580 AcComprMalFn 7;
BA_ "GenSigCycleTimeActive" SG_ 580 AcComprMalFn 100;
BA_ "GenSigCycleTime" SG_ 580 AcComprMalFn 100;
BA_ "GenSigTimeoutMsg_HU_High_X445" SG_ 580 AcComprMalFn 0;
BA_ "GenSigTimeoutMsg_HU_Mid_X445" SG_ 580 AcComprMalFn 0;
BA_ "GenSigTimeoutTime_HU_High_X445" SG_ 580 AcComprMalFn 0;
BA_ "GenSigTimeoutTime_HU_Mid_X445" SG_ 580 AcComprMalFn 0;
BA_ "GenSigTimeoutTime_HU_Mid_X451" SG_ 580 AcCmprStatusVcu 0;
BA_ "GenSigTimeoutTime_HU_High_X451" SG_ 580 AcCmprStatusVcu 0;
BA_ "GenSigTimeoutTime_HU_B" SG_ 580 AcCmprStatusVcu 0;
BA_ "GenSigTimeoutTime_HU_A" SG_ 580 AcCmprStatusVcu 0;
BA_ "GenSigTimeoutMsg_HU_Mid_X451" SG_ 580 AcCmprStatusVcu 0;
BA_ "GenSigTimeoutMsg_HU_High_X451" SG_ 580 AcCmprStatusVcu 0;
BA_ "GenSigTimeoutMsg_HU_B" SG_ 580 AcCmprStatusVcu 0;
BA_ "GenSigTimeoutMsg_HU_A" SG_ 580 AcCmprStatusVcu 0;
BA_ "GenSigSendType" SG_ 580 AcCmprStatusVcu 7;
BA_ "GenSigCycleTimeActive" SG_ 580 AcCmprStatusVcu 100;
BA_ "GenSigCycleTime" SG_ 580 AcCmprStatusVcu 100;
BA_ "GenSigSendType" SG_ 580 VcuPowerMode 7;
BA_ "GenSigCycleTimeActive" SG_ 580 VcuPowerMode 100;
BA_ "GenSigCycleTime" SG_ 580 VcuPowerMode 100;
BA_ "GenSigSendType" SG_ 580 VcuPowerModeStatus 7;
BA_ "GenSigCycleTimeActive" SG_ 580 VcuPowerModeStatus 100;
BA_ "GenSigCycleTime" SG_ 580 VcuPowerModeStatus 100;
VAL_ 1142 PEPS_MTO_Failure_Status 3 "Reserved" 2 "Failure healed aging in progress" 1 "Failure detected DTC in Memory" 0 "Failure is not detected" ;
VAL_ 1142 ABS_ESP_MRC_Failure_Status 3 "Reserved" 2 "Failurehealed Ageing in progress" 1 "Failure matured & DTC in memory" 0 "Faiulure is not detected " ;
VAL_ 1142 ABS_ESP_CRC_Failure_Status 3 "Reserved" 2 "Failurehealed Ageing in progress" 1 "Failure matured & DTC in memory" 0 "Faiulure is not detected " ;
VAL_ 1142 Telematics_MTO_Failure_status 3 "Reserved" 2 "Failure healed aging in progress" 1 "Failure matured & DTC in memory" 0 "Failure is not detected" ;
VAL_ 1142 Telematics_Invalid_FailureStatus 3 "Reserved" 2 "Failure healed aging in progress" 1 "Failure matured & DTC in memory" 0 "Failure is not detected" ;
VAL_ 1142 SRS_MTO_Failure_Status 3 "Reserved" 2 "Failure healed aging in progress" 1 "Failure detected DTC in Memory" 0 "Failure is not detected" ;
VAL_ 1142 IPcMToFailureStatus 3 "Reserved" 2 "Failure healed Ageing in progress" 1 "Failure matured & DTC in memory" 0 "Failure is not detected" ;
VAL_ 1142 IPcInvalidFailureStatus 3 "Reserved" 2 "Failure healed Ageing in progress" 1 "Failure matured & DTC in memory" 0 "Failure is not detected" ;
VAL_ 1142 ABsMToFailureStatus 3 "Reserved" 2 "Failure healed aging in progress" 1 "Failrue detected DTC in memory" 0 "Failure is not detected" ;
VAL_ 1142 ABsInvalidFailureStatus 3 "Reserved" 2 "Failure healed ageing in progress" 1 "fail detected and DTC  in memory" 0 "failure not detected" ;
VAL_ 1142 VCU_EP_Failure_Status 3 "Historic DTC" 2 "Failurehealed Ageing in progress" 1 "Failure matured & DTC in memory" 0 "Faiulure is not detected " ;
VAL_ 1142 VCU_BO_Failure_Status 3 "Historic DTC" 2 "Failurehealed Ageing in progress" 1 "Failure matured & DTC in memory" 0 "Faiulure is not detected " ;
VAL_ 1142 GSS_EV_Invalid_Failure_Status 3 "Reserved" 2 "Failure Healed; aging in progress" 1 "Failure Detected; DTC in memory" 0 "Failure is not Detected" ;
VAL_ 1142 GSS_EV_MTO_Failure_Status 3 "Reserved" 2 "Failure Healed; aging in progress" 1 "Failure Detected; DTC in memory" 0 "Failure is not Detected" ;
VAL_ 1142 CCM_MTO_Failure_Status 3 "Reserved" 2 "Failure healed & Ageing in progress" 1 "failure is detected & DTC in memeory" 0 "Failure is not detected" ;
VAL_ 1142 CCM_Invalid_Failure_Status 3 "Reserved" 2 "Failure healed Ageing in progress" 1 "Failure matured & DTC in memory" 0 "Failure is not detected" ;
VAL_ 1142 BCmMToFailureStatus 3 "Reserved" 2 "Failure healed aging in progress" 1 "Failure detected; DTC in memory" 0 "Failrue is not detected" ;
VAL_ 1184 GSS_EV_MTO_Failure_Status 3 "Reserved" 2 "Failure Healed; aging in progress" 1 "Failure Detected; DTC in memory" 0 "Failure is not Detected" ;
VAL_ 1184 Telematics_MTO_Failure_status 3 "Reserved" 2 "Failure healed aging in progress" 1 "Failure matured & DTC in memory" 0 "Failure is not detected" ;
VAL_ 1184 Telematics_Invalid_FailureStatus 3 "Reserved" 2 "Failure healed aging in progress" 1 "Failure matured & DTC in memory" 0 "Failure is not detected" ;
VAL_ 1184 VCUMToFailureStatus 3 "Reserved" 2 "Failure healed aging in progress" 1 "Failure matured & DTC in memory" 0 "Failure is not detected" ;
VAL_ 1184 VCUInvalidFailureStatus 3 "Reserved" 2 "Failure healed aging in progress" 1 "Failure matured & DTC in memory" 0 "Failure is not detected" ;
VAL_ 493 CarAnniversary 1 "Display message It's your car's Birthday. Congratulations!" 0 "No trigger" ;
VAL_ 493 OwnersAnniversary 1 "Display message Happy Marriage Anniversary!" 0 "No trigger" ;
VAL_ 493 OwnersBirthday 1 "Display message Happy Birthday" 0 "No trigger" ;
VAL_ 581 HvChargeTypeStatus 3 "Signal Not Available" 2 "Signal is implausible" 1 "Reserved for Future use" 0 "Signal is plausible" ;
VAL_ 581 HvChargeType 3 "Reserved" 2 "Reserved" 1 "Fast Charging" 0 "Normal Charging" ;
VAL_ 581 HvChargingStateStatus 3 "Signal Not Available" 2 "Signal is implausible" 1 "Reserved for Future use" 0 "Signal is plausible" ;
VAL_ 581 HvChargingState 7 "Reserved" 6 "Reserved" 5 "Reserved" 4 "Charger Connection lamp Red color  Blink" 3 "Charger Connection lamp Red color  ON" 2 "Charger Connection lamp Green color  Blink" 1 "Charger Connection lamp Green color  ON" 0 "Charger Connection lamp is OFF. " ;
VAL_ 581 TimetoChargeHVMintsStatus 3 "Reserved" 2 "Information given is implausible due to a detected failure" 1 "Reserved" 0 "Information given is correct and according to specification" ;
VAL_ 581 TimetoChargeHVHoursStatus 3 "Reserved" 2 "Information given is implausible due to a detected failure" 1 "Reserved" 0 "Information given is correct and according to specification" ;
VAL_ 581 CabinCoolingSolValveStateStatus 3 "Reserved" 2 "Information given is implausible due to a detected failure " 1 "Reserved" 0 "Information given correct and according to specification" ;
VAL_ 581 CabinCoolingSolValveState 3 "Reserved" 2 "Cabin Cooling SV is ON" 1 "Reserved" 0 "Cabin Cooling SV is OFF" ;
VAL_ 581 LowHVBatteryChargeStatus 3 "Reserved" 2 "Information given is implausible due to a detected failure" 1 "Reserved" 0 "Information given is correct and according to specification" ;
VAL_ 581 LowHVBatteryCharge 3 " Reserved for future use" 2 "Low HV Battery Charge lamp ON" 1 "Low HV Battery Charge lamp Flashing" 0 "Low HV Battery Charge lamp is OFF. " ;
VAL_ 581 LowLVBatteryChargeStatus 3 "Reserved" 2 "Information given is implausible due to a detected failure" 1 "Reserved" 0 "Information given is correct and according to specification" ;
VAL_ 581 LowLVBatteryCharge 3 " Reserved for future use" 2 "Low LV Battery Charge lamp ON" 1 "Low LV Battery Charge lamp Flashing" 0 "Low LV Battery Charge lamp is OFF. " ;
VAL_ 581 HvAmpHrStatus 3 "Reserved" 2 "Information  is implausible due to a detected failure " 1 "Reserved" 0 "Information is correct and accord to specification" ;
VAL_ 1171 VCUMToFailureStatus 3 "Reserved" 2 "Failure healed aging in progress" 1 "Failure matured & DTC in memory" 0 "Failure is not detected" ;
VAL_ 1171 VCUInvalidFailureStatus 3 "Reserved" 2 "Failure healed aging in progress" 1 "Failure matured & DTC in memory" 0 "Failure is not detected" ;
VAL_ 1330 P_Status 3 "Invalid 2" 2 "Invalid 1" 1 "Dust Sensor OFF" 0 "Dust Sensor ON" ;
VAL_ 1330 P_ResponsErr 1 "Response Error" 0 "No Response Error" ;
VAL_ 1330 P_TempError 3 "Invalid 2" 2 "Invalid 1" 1 "Error in Sensor Temperature" 0 "NO Error in sensor temperature" ;
VAL_ 1330 P_TempOverHeat 3 "Invalid 2" 2 "Invalid 1" 1 "Dust Sensor Temp Overheated" 0 "Dust Sensor Temp not Overheated" ;
VAL_ 1330 P_SensorChange 3 "Invalid 2" 2 "Invalid 1" 1 "Change" 0 "No Change" ;
VAL_ 1330 P_MotorError 3 "Invalid 2" 2 "Invalid 1" 1 "Error" 0 "No Error" ;
VAL_ 1330 P_Initialization 3 "Invalid 2" 2 "Invalid 1" 1 "Initilisation In Progress" 0 "Initilisation Finish" ;
VAL_ 1330 P_HighTempMode 3 "Invalid 2" 2 "Invalid 1" 1 "High Temperature Mode is Activated" 0 "High Temperature Mode is Not activated" ;
VAL_ 1330 C_LinError 1 "LIN communication error" 0 "No Communication Error" ;
VAL_ 1330 C_Operation 3 "Invalid" 2 "Error" 1 "Dust Sensor Disable" 0 "Dust Sensor Enable" ;
VAL_ 1288 RepeatMessageReq_TM 1 "Repeat message state requested" 0 "Repeat message state not requested" ;
VAL_ 1288 PreviousState_TM 7 "Reserved" 6 "Reserved" 5 "Reserved" 4 " Bus Sleep State" 3 "Prepare Bus Sleep State" 2 "Ready Sleep State" 1 "Normal Operation State" 0 "Repeat Message State" ;
VAL_ 1288 CurrentState_TM 1 "Normal Operation State" 0 "Repeat Messgae State" ;
VAL_ 1288 ActiveWakeUp_TM 1 "Node has  woken up the network(Active wakeup)" 0 "Node has not woken up the network(Passive wakeup)" ;
VAL_ 1287 RepeatMessageReq_VCU 1 "Repeat message state requested" 0 "Repeat message state not requested" ;
VAL_ 1287 PreviousState_VCU 7 "Reserved" 6 "Reserved" 5 "Reserved" 4 " Bus Sleep State" 3 "Prepare Bus Sleep State" 2 "Ready Sleep State" 1 "Normal Operation State" 0 "Repeat Message State" ;
VAL_ 1287 CurrentState_VCU 1 "Normal Operation State" 0 "Repeat Messgae State" ;
VAL_ 1287 ActiveWakeUp_VCU 1 "Node has  woken up the network(Active wakeup)" 0 "Node has not woken up the network(Passive wakeup)" ;
VAL_ 703 PaddleShifterStatus 3 "Signal not available" 2 "Signal is implausible" 1 "Reserved for future use." 0 "Signal is correct" ;
VAL_ 703 PaddleShifter 7 "not used" 6 "not used" 5 "not used" 4 "Invalid" 3 "up and down both are active" 2 "down is active" 1 "up is active" 0 "inactive" ;
VAL_ 703 OATICSigNewStatus 3 "Signal OATSig is not available" 2 "Implausible -Information given at OATICSig is implausible" 1 "Reserved for future use" 0 "Plausible-InformationgivenatOATICSigiscorrectandaccordingtospec" ;
VAL_ 724 PtcTempValStatus 3 "Signal not available" 2 "Implausible" 1 "Reserved for future use" 0 "Plausible and signal is correct" ;
VAL_ 724 CCMVbatStatus 3 "Signal Not Available" 2 "Implausible" 1 "Reserved" 0 "Plausible" ;
VAL_ 724 BlowerFBVoltageStatus 3 "Signal BlowerFBVoltage Not Available" 2 "Information given at BlowerFBVoltage is implausible" 1 "Reserved for future use" 0 "Information  is correct and according to specification" ;
VAL_ 724 BlowerPWMStatus 3 "Signal BlowerPWM  Not Available" 2 "Information given at BlowerPWM  is implausible" 1 "Reserved for future use" 0 "Information  is correct and according to specification" ;
VAL_ 724 BlowerStatus 3 "Signal BlowerStatus Not Available" 2 "Information given at blowerstatus is implausible" 1 "Reserved for future use" 0 "Information  is correct and according to specification" ;
VAL_ 724 BlowerState 3 "Fault Occurred" 2 "On" 1 "Off " 0 "Not initialised" ;
VAL_ 724 HeatingPwrValStatus 3 "Signal not available" 2 "Implausible" 1 "Reserved for future use" 0 "Plausible and signal is correct" ;
VAL_ 724 CoolingPwrValStatus 3 "Signal not available" 2 "Implausible" 1 "Reserved for future use" 0 "Plausible and signal is correct" ;
VAL_ 724 AcReqNew 1 "AC request from driver activated" 0 "AC Request from driver deactivated" ;
VAL_ 408 ParkBrkStatus2 3 "Signal not available" 2 "Value is implausible" 1 "Reserved for future use" 0 "Value is correct and according to specification" ;
VAL_ 408 ParkBrkState2 3 "Fully Engaged" 2 "Reserved" 1 "Partially Engaged" 0 "Not Engaged" ;
VAL_ 408 ICDispSpeedSigStatus 3 "Reserved" 2 "Implausible -Information given at ICDispSpeedSig is implausible" 1 "Reserved for future use" 0 "Plausible-Informationgiveniscorrectandaccordingtospecification" ;
VAL_ 738 BcmHbaFaultState 1 "System Fault" 0 "No fault" ;
VAL_ 738 HighBeamState 1 "High Beam Input ON" 0 "High Beam Input OFF" ;
VAL_ 738 RearWiperStateStatus 3 "Signal Not Available(SNA)" 2 "Implausible" 1 "Reserved" 0 "Plausible" ;
VAL_ 738 RearWiperState 3 "Reserved for future use" 2 "Reserved for future use" 1 "Rear Wiper Activated" 0 "Rear Wiper Deactivated" ;
VAL_ 738 RemoteUsecaseStateStatus 3 "Signal not available" 2 "Signal is implausible" 1 "Reserved for future use." 0 "Signal is correct" ;
VAL_ 738 RemoteUsecaseState 3 "Remote Use case is ON" 2 "Reserved" 1 "Remote Use case is OFF with Normal Running Mode ON  " 0 "Remote Use case is OFF" ;
VAL_ 738 DewPointTemperature 1023 "Failure value" 0 "Initial / Invalid" ;
VAL_ 738 WindshieldTemperature 255 "Failure value" 0 "Initial / Invalid" ;
VAL_ 738 HumidityValue 255 "Failure value" 0 "Initial / Invalid" ;
VAL_ 738 HornStateStatus 3 "Reserved" 2 "Information given is implausible due to a detected failure " 1 "Reserved" 0 "Information given is correct" ;
VAL_ 738 HornState 1 "Horn is  Acive " 0 "Horn is  Not Acive " ;
VAL_ 738 ForcePanicStatus 1 "Force Panic  Active" 0 "Force panic Not Active" ;
VAL_ 738 ApprochLampStateStatus 3 "Signal Not Available" 2 "Signal is implausible" 1 "Reserved for future use" 0 "Plausible  - Information given is correct" ;
VAL_ 738 ApprochLampState 1 "ApprochLamp ON" 0 "ApprochLamp OFF" ;
VAL_ 738 LowBeamTellTaleStatus 3 "Signal LowBeamTelltale Not Available" 2 "Reserved for future use" 1 "Reserved for future use" 0 "Plausible  and Signal is correct" ;
VAL_ 738 LowBeamTellTale 1 "Low Beam ON" 0 "Low Beam OFF" ;
VAL_ 738 IntrusionInfoStateStatus 3 "Signal Not Available" 2 "Reserved for future use." 1 "Reserved for future use." 0 "Plausible-Information is correct and according to specification" ;
VAL_ 738 IntrusionInfoState 1 "Perimetric alarm ON" 0 "Perimetric alarm OFF" ;
VAL_ 738 HazardLampState 1 "Hazard Lamp On" 0 "Hazard Lamp off" ;
VAL_ 738 HazardLampStateStatus 3 "Signal Not Available" 2 "Signal is implausible" 1 "Reserved for future use." 0 "Signal is plausible" ;
VAL_ 738 VehicleSecured 1 "Secured" 0 "Not Secured" ;
VAL_ 738 VehicleSecuredStatus 3 "Signal Not Available" 2 "Signal is implausible" 1 "Reserved for future use." 0 "Plausible-Informationgiveniscorrectandaccordingtospecification" ;
VAL_ 495 SharedLocationReqAck 7 "Reserved" 6 "Reserved" 5 "Reserved" 4 "Location sharing failed due to server error " 3 "Location sharing failed due to network error" 2 "Location shared successfully" 1 "Location request sent to Server" 0 "Not Applicable/No Action required" ;
VAL_ 495 CommunityHelpResp 7 "Reserved" 6 "Community Help Cancel Request Failure" 5 "Community Help Cancel Request Successful" 4 "Community Help command not Accepted" 3 "Community Help command Accepted" 2 "Community Help command Failure" 1 "Community Help request In progress" 0 "Don’t Care" ;
VAL_ 495 CommunityHelpNotif 15 "Reserved" 14 "Reserved" 13 "Reserved" 12 "Reserved" 11 "Reserved" 10 "Reserved" 9 "Reserved" 8 "Community Help requested for Low Fuel." 7 "Community Help requested for Low SOC." 6 "Community Help requested for Tire puncture. " 5 "Community Help requested for Towing." 4 "Community Help requested for Medical issue." 3 "Community Help requested for Accident." 2 "Community Help requested for Vehicle Breakdown." 1 "Community Help cancel" 0 "No Action required" ;
VAL_ 495 RemoteHornCmdStatus 3 "Signal Not Available" 2 "Signal is Implausible" 1 "Don't Care " 0 "Plausible  - Information given is correct" ;
VAL_ 495 RemoteHornCmd 1 "Remote horn requested" 0 "Remote horn not requested" ;
VAL_ 495 RemoteApprochLmpCmdStatus 3 "Signal Not Available" 2 "Signal is implausible" 1 "Don't Care " 0 "Plausible  - Information given is correct" ;
VAL_ 495 RemoteApprochLmpCmd 1 "Turn On Approch lamp" 0 "Turn Off Approch lamp" ;
VAL_ 495 RemoteValetCmdStatus 3 "Signal not available" 2 "Signal is implausible" 1 "Don't Care " 0 "Plausible and signal is correct" ;
VAL_ 495 RemoteValetCmd 1 "valet Command enable" 0 "Valet command Disable" ;
VAL_ 495 RemoteAcTempSetStatus 3 "Signal Not Available" 2 "Signal is Implausible" 1 "Don't Care " 0 "Plausible and signal is correct" ;
VAL_ 495 RemoteAcTempSet 31 "Reserved" 30 "HI" 29 "30" 28 "29.5" 27 "29" 26 "28.5" 25 "28" 24 "27.5" 23 "27" 22 "26.5" 21 "26" 20 "25.5" 19 "25" 18 "24.5" 17 "24" 16 "23.5" 15 "23" 14 "22.5" 13 "22" 12 "21.5" 11 "21" 10 "20.5" 9 "20" 8 "19.5" 7 "19" 6 "18.5" 5 "18" 4 "LO" 3 "Reserved" 2 "Reserved" 1 "Reserved" 0 "Reserved" ;
VAL_ 495 RemoteAcCmd 1 "Turn On AC" 0 "Turn Off AC" ;
VAL_ 495 RemoteAcCmdStatus 3 "Signal Not Available" 2 "Signal is Implausible" 1 "Don't Care " 0 "Plausible and signal is correct" ;
VAL_ 495 RemoteImmoReqStatus 3 "Signal Not Available" 2 "Signal is Implausible" 1 "Don't Care " 0 "Plausible and signal is correct" ;
VAL_ 495 RemoteImmoReq 3 "Reserved" 2 "Immobilize request" 1 "Mobilize request" 0 "No request" ;
VAL_ 495 TowInfoStatus 3 "Signal Not Available" 2 "Reserved for future use." 1 "Don't Care " 0 "Plausible -Information is correct and according to specification" ;
VAL_ 495 TowInfo 1 "Tow occurred" 0 "Tow not occurred" ;
VAL_ 495 ParkingCollisionInfoStatus 3 "Signal Not Available" 2 "Signal is implausible" 1 "Don't Care " 0 "Plausible -Information is correct and according to specification" ;
VAL_ 495 ParkingCollisionInfo 1 "Parking collision occured" 0 "Parking collision not occured" ;
VAL_ 495 RemotePositionCmdStatus 3 "Signal Not Available" 2 "Signal is implausible" 1 "Don't Care " 0 "Plausible-Information is correct and according to specification" ;
VAL_ 495 RemotePositionCmd 1 "Turn ON Position Lamp" 0 "Turn Off Position Lamp" ;
VAL_ 495 RemoteHazardCmdStatus 3 "Signal Not Available" 2 "Signal is implausible" 1 "Don't Care " 0 "Plausible -Informationgiveniscorrectandaccordingtospecification" ;
VAL_ 495 RemoteHazardCmd 1 "Turn ON Hazard Lamp" 0 "Turn Off Hazard Lamp" ;
VAL_ 495 RemoteVehicleUnlockCmdStatus 3 "Signal Not Available" 2 "Signal is implausible" 1 "Don't Care " 0 "Plausible-Information is correct and according to specification" ;
VAL_ 495 RemoteVehicleUnlockCmd 1 "Vehicle unlock request received" 0 "Vehicle unlock request not received" ;
VAL_ 495 RemoteVehicleLockCmdStatus 3 "Signal Not Available" 2 "Signal is implausible" 1 "Don't Care " 0 "Plausible-Information is correct and according to specification" ;
VAL_ 495 RemoteVehicleLockCmd 1 "Vehicle lock request received" 0 "Vehicle lock request not received" ;
VAL_ 1105 VCUMToFailureStatus 3 "Reserved" 2 "Failure healed aging in progress" 1 "Failure matured & DTC in memory" 0 "Failure is not detected" ;
VAL_ 1105 VCUInvalidFailureStatus 3 "Reserved" 2 "Failure healed aging in progress" 1 "Failure matured & DTC in memory" 0 "Failure is not detected" ;
VAL_ 1105 IPcMToFailureStatus 3 "Reserved" 2 "Failure healed Ageing in progress" 1 "Failure matured & DTC in memory" 0 "Failure is not detected" ;
VAL_ 1105 IPcInvalidFailureStatus 3 "Reserved" 2 "Failure healed Ageing in progress" 1 "Failure matured & DTC in memory" 0 "Failure is not detected" ;
VAL_ 1105 GSS_EV_EP_Failure_Status 3 "Reserved" 2 "Failurehealed Ageing in progress" 1 "Failure matured & DTC in memory" 0 "Faiulure is not detected " ;
VAL_ 1105 GSS_EV_BO_Failure_Status 3 "Reserved" 2 "Failure healed Ageing in progress" 1 "Failure matured & DTC in memory" 0 "Faiulure is not detected " ;
VAL_ 1105 BCM_MTO_Failure_status 3 "Reserved" 2 "Failure is cleared and DTC is moved to history." 1 "Failure is detected and active DTC is stored in the error memory." 0 "Failure is currently not detected." ;
VAL_ 1105 BCM_Invalid_Status_Failure 3 "Reserved" 2 "Failure healed aging in progress" 1 "Failure detected DTC in memory" 0 "Failure is not detected" ;
VAL_ 617 GSSGearSelectionDorStatus 3 "Signal Not Available" 2 "Information given is implausible due to a detected failure " 1 "Reserved" 0 "Information given correct and according to specification" ;
VAL_ 617 GSSGearSelectionDor 3 "Reserved" 2 "Anti-Clockwise Rotation " 1 "Clockwise Rotation" 0 "No Valid Change Request" ;
VAL_ 617 GearSelectionSwStateStatus 3 "Signal Not available" 2 "Information given  is implausible" 1 "Reserved" 0 "Information given is correct and according to specification" ;
VAL_ 617 GearSelectionSwState 15 "Reserved" 14 "Reserved" 13 "Reserved" 12 "Reserved" 11 "Reserved" 10 "Reserved" 9 "Reserved" 8 "Reserved" 7 "Reserved" 6 "Reserved" 5 "Reserved" 4 "Park" 3 "Reverse" 2 "Sport" 1 "Drive" 0 "Neutral" ;
VAL_ 617 GSSGearSelectionChangeTxt 4 "Press Brake for gear Selection" 3 "Gear Selection is not possible due to system Fault" 2 "Rotate in Clockwise to Change the Gear Position" 1 "Rotate in anti-clock wise to Change Gear position" 0 "Gear Selection possible" ;
VAL_ 580 BrakePaddlePosVcuStatus 3 "Signal Not available" 2 "BrakePaddlePosVcu signal Value is implausible" 1 "Reserved" 0 "Information given by BrakePaddlePosVcu is correct and according to specification" ;
VAL_ 580 HVBattSoCPercenStatus 3 "Reserved" 2 "Information given is implausible due to a detected failure" 1 "Reserved" 0 "Information given is correct and according to specification" ;
VAL_ 580 DTeInfoStatus 3 "Reserved" 2 "Information given is implausible due to a detected failure" 1 "Reserved" 0 "Information given is correct and according to specification" ;
VAL_ 580 VehicleStatus 7 "Reserved" 6 "Reserved" 5 "Reserved" 4 "Reserved" 3 "EV System Disengaged" 2 "Not Ready to Go,  HV System Not Ready" 1 "Not Ready to Go, Charger Connected" 0 "Ready to Go" ;
VAL_ 580 VcuStatus 1 "VCU Malfunction" 0 "VCU Normal" ;
VAL_ 580 ValetStateStatus 3 "Signal not available" 2 "Signal is implausible" 1 "Reserved for future use" 0 "Plausible and signal is correct" ;
VAL_ 580 ValetState 1 "Valet State Mode On" 0 "Valet State Mode OFF" ;
VAL_ 580 AcComprMalFn 1 "AC Compressor Malfunction" 0 "AC Compressor Normal" ;
VAL_ 580 AcCmprStatusVcu 1 "AC Compressor is On" 0 "AC Compressor is Off" ;
VAL_ 580 VcuPowerMode 15 "Reserved" 14 "Reserved" 13 "Reserved" 12 "Reserved" 11 "Reserved" 10 "Reserved" 9 "Reserved" 8 "Reserved" 7 "Reserved" 6 "Limited power mode" 5 "Charging mode" 4 "Energy Recuperation" 3 "Normal Run" 2 "Crank" 1 "Active" 0 "Awake" ;
VAL_ 580 VcuPowerModeStatus 3 "Reserved" 2 "Information given is implausible due to a detected failure" 1 "Reserved" 0 "Information given is correct and according to specification" ;
